VERSION "BASE;119 -- 04.07.2025 -- R3233 -- FDMgenDBC1.0"

NS_ :

BS_:

BU_: CM4

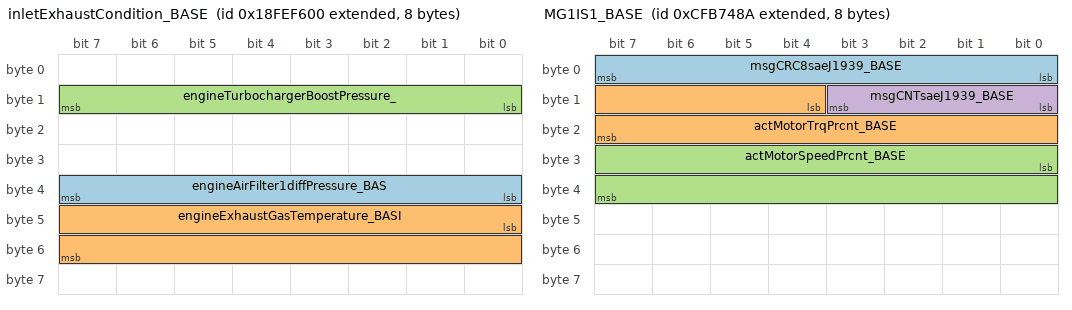
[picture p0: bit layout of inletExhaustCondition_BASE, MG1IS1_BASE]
BO_ 2566845952 inletExhaustCondition_BASE: 8 Vector__XXX
 SG_ engineAirFilter1diffPressure_BAS : 32|8@1+ (0.05,0) [0|12.5] "kPa" CM4
 SG_ engineExhaustGasTemperature_BASI : 40|16@1+ (0.03125,-273) [-273|1734.96875] "°C" CM4
 SG_ engineTurbochargerBoostPressure_ : 8|8@1+ (2,0) [0|500] "kPa" CM4

BO_ 2365289610 MG1IS1_BASE: 8 Vector__XXX
 SG_ msgCRC8saeJ1939_BASE : 0|8@1+ (1,0) [0|255] "-" CM4
 SG_ actMotorTrqPrcnt_BASE : 12|12@1+ (0.0625,-125) [-125|125.9375] "%" CM4
 SG_ actMotorSpeedPrcnt_BASE : 24|16@1+ (0.00390625,-125) [-125|125.99609375] "%" CM4
 SG_ msgCNTsaeJ1939_BASE : 8|4@1+ (1,0) [0|15] "-" CM4

BO_ 2566898183 bodyBuilderInfo7_BASE: 8 Vector__XXX
 SG_ BB_PlaceHolder_BASE : 0|8@1+ (1,0) [0|255] "-" CM4

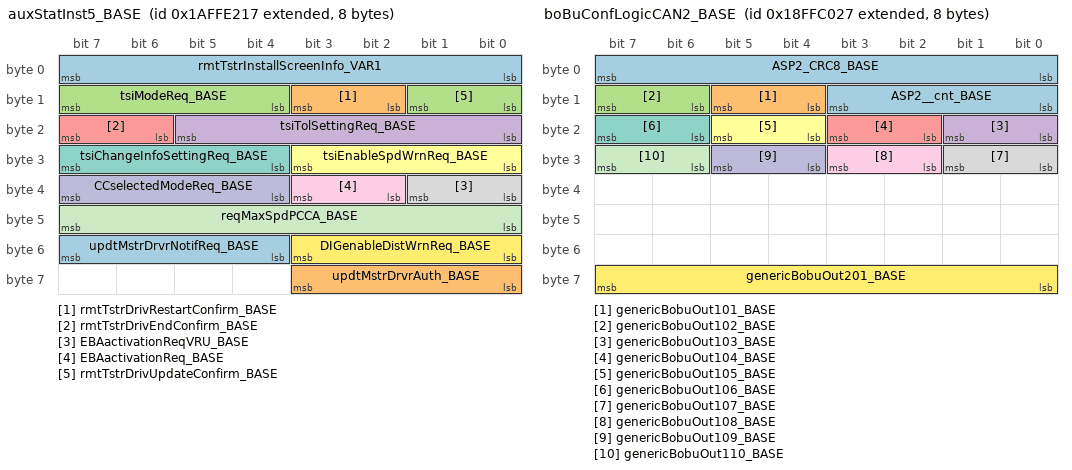
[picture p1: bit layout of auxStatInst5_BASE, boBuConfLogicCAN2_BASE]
BO_ 2600460823 auxStatInst5_BASE: 8 Vector__XXX
 SG_ rmtTstrInstallScreenInfo_VAR1 : 0|8@1+ (1,0) [0|0] "-" CM4
 SG_ rmtTstrDrivRestartConfirm_BASE : 10|2@1+ (1,0) [0|0] "-" CM4
 SG_ tsiModeReq_BASE : 12|4@1+ (1,0) [0|0] "-" CM4
 SG_ tsiTolSettingReq_BASE : 16|6@1+ (1,0) [0|0] "-" CM4
 SG_ rmtTstrDrivEndConfirm_BASE : 22|2@1+ (1,0) [0|0] "-" CM4
 SG_ tsiEnableSpdWrnReq_BASE : 24|4@1+ (1,0) [0|0] "-" CM4
 SG_ tsiChangeInfoSettingReq_BASE : 28|4@1+ (1,0) [0|0] "-" CM4
 SG_ EBAactivationReqVRU_BASE : 32|2@1+ (1,0) [0|0] "-" CM4
 SG_ EBAactivationReq_BASE : 34|2@1+ (1,0) [0|0] "-" CM4
 SG_ CCselectedModeReq_BASE : 36|4@1+ (1,0) [0|0] "-" CM4
 SG_ reqMaxSpdPCCA_BASE : 40|8@1+ (0.2,80) [80|130] "km/h" CM4
 SG_ DIGenableDistWrnReq_BASE : 48|4@1+ (1,0) [0|0] "-" CM4
 SG_ updtMstrDrvrNotifReq_BASE : 52|4@1+ (1,0) [0|0] "-" CM4
 SG_ updtMstrDrvrAuth_BASE : 56|4@1+ (1,0) [0|0] "-" CM4
 SG_ rmtTstrDrivUpdateConfirm_BASE : 8|2@1+ (1,0) [0|0] "-" CM4

BO_ 2566891559 auxStatMC7_BASE: 8 Vector__XXX
 SG_ bckgrndLghtAutoRevRqSave_BASE : 0|2@1+ (1,0) [0|0] "-" CM4
 SG_ ISCcondClutchOpen_BASE : 16|2@1+ (1,0) [0|0] "-" CM4
 SG_ ISCcondEngWarming_BASE : 18|2@1+ (1,0) [0|0] "-" CM4
 SG_ ISCcondBrakeNotPressed_BASE : 2|2@1+ (1,0) [0|0] "-" CM4
 SG_ ISCcondGearEngaged_BASE : 20|2@1+ (1,0) [0|0] "-" CM4
 SG_ ISCcondNeutralEngaged_BASE : 22|2@1+ (1,0) [0|0] "-" CM4
 SG_ ISCcondParkingBrakeActv_BASE : 24|2@1+ (1,0) [0|0] "-" CM4
 SG_ ISCcondParkingBrakeNotActv_BASE : 26|2@1+ (1,0) [0|0] "-" CM4
 SG_ ISCcondVehSpd_BASE : 28|2@1+ (1,0) [0|0] "-" CM4
 SG_ ZDRact_BASE : 30|2@1+ (1,0) [0|0] "-" CM4
 SG_ brightFunctionLight_BASE : 32|8@1+ (0.4,0) [0|100] "%" CM4
 SG_ ISCcondBrakePressed_BASE : 4|2@1+ (1,0) [0|0] "-" CM4
 SG_ dispInteriorLightAutoReq_BASE : 40|2@1+ (1,0) [0|0] "-" CM4
 SG_ dispIntLghtAutoCLreq_BASE : 42|2@1+ (1,0) [0|0] "-" CM4
 SG_ centrLubGreaseLvlLow_BASE : 44|2@1+ (1,0) [0|0] "-" CM4
 SG_ vehStandStill_BASE : 46|2@1+ (1,0) [0|0] "-" CM4
 SG_ centralUnlockDoorSelect_BASE : 48|2@1+ (1,0) [0|0] "-" CM4
 SG_ dispEntranceLightAutoReq_BASE : 50|2@1+ (1,0) [0|0] "-" CM4
 SG_ ureaLvlWarningDisp_BASE : 52|2@1+ (1,0) [0|0] "-" CM4
 SG_ centralLockSpeedSelect_BASE : 54|2@1+ (1,0) [0|0] "-" CM4
 SG_ auxStatMC7cntE2E_BASE : 56|4@1+ (1,0) [0|15] "-" CM4
 SG_ ISCcondClutchClosed_BASE : 6|2@1+ (1,0) [0|0] "-" CM4
 SG_ auxStatMC7chkE2E_BASE : 60|4@1+ (1,0) [0|15] "-" CM4
 SG_ bckgrndLghtBrghtReqSave_BASE : 8|8@1+ (0.4,0) [0|100] "%" CM4

BO_ 2566897703 boBuConfLogicCAN2_BASE: 8 Vector__XXX
 SG_ ASP2_CRC8_BASE : 0|8@1+ (1,0) [0|255] "-" CM4
 SG_ genericBobuOut101_BASE : 12|2@1+ (1,0) [0|0] "-" CM4
 SG_ genericBobuOut102_BASE : 14|2@1+ (1,0) [0|0] "-" CM4
 SG_ genericBobuOut103_BASE : 16|2@1+ (1,0) [0|0] "-" CM4
 SG_ genericBobuOut104_BASE : 18|2@1+ (1,0) [0|0] "-" CM4
 SG_ genericBobuOut105_BASE : 20|2@1+ (1,0) [0|0] "-" CM4
 SG_ genericBobuOut106_BASE : 22|2@1+ (1,0) [0|0] "-" CM4
 SG_ genericBobuOut107_BASE : 24|2@1+ (1,0) [0|0] "-" CM4
 SG_ genericBobuOut108_BASE : 26|2@1+ (1,0) [0|0] "-" CM4
 SG_ genericBobuOut109_BASE : 28|2@1+ (1,0) [0|0] "-" CM4
 SG_ genericBobuOut110_BASE : 30|2@1+ (1,0) [0|0] "-" CM4
 SG_ genericBobuOut201_BASE : 56|8@1+ (1,0) [0|250] "-" CM4
 SG_ ASP2__cnt_BASE : 8|4@1+ (1,0) [0|15] "-" CM4

BO_ 2600407315 customerInterface26_BASE: 8 Vector__XXX
 SG_ placeholderCuIntf26_BASE : 0|8@1+ (1,0) [0|255] "-" CM4

BO_ 2600407314 customerInterface25_BASE: 8 Vector__XXX
 SG_ placeholderCuIntf25_BASE : 0|8@1+ (1,0) [0|255] "-" CM4

BO_ 2600407316 customerInterface27_BASE: 8 Vector__XXX
 SG_ placeholderCuIntf27_BASE : 0|8@1+ (1,0) [0|255] "-" CM4

BO_ 2600407310 customerInterface21_BASE: 8 Vector__XXX
 SG_ placeholderCuIntf21_BASE : 0|8@1+ (1,0) [0|255] "-" CM4

BO_ 2600407311 customerInterface22_BASE: 8 Vector__XXX
 SG_ placeholderCuIntf22_BASE : 0|8@1+ (1,0) [0|255] "-" CM4

BO_ 2600407312 customerInterface23_BASE: 8 Vector__XXX
 SG_ placeholderCuIntf23_BASE : 0|8@1+ (1,0) [0|255] "-" CM4

BO_ 2600407313 customerInterface24_BASE: 8 Vector__XXX
 SG_ placeholderCuIntf24_BASE : 0|8@1+ (1,0) [0|255] "-" CM4

BO_ 2565879335 HVESSS2_BASE: 8 Vector__XXX
 SG_ HVESSDischrgPwLimDueSOC_BASE : 0|2@1+ (1,0) [0|0] "-" CM4

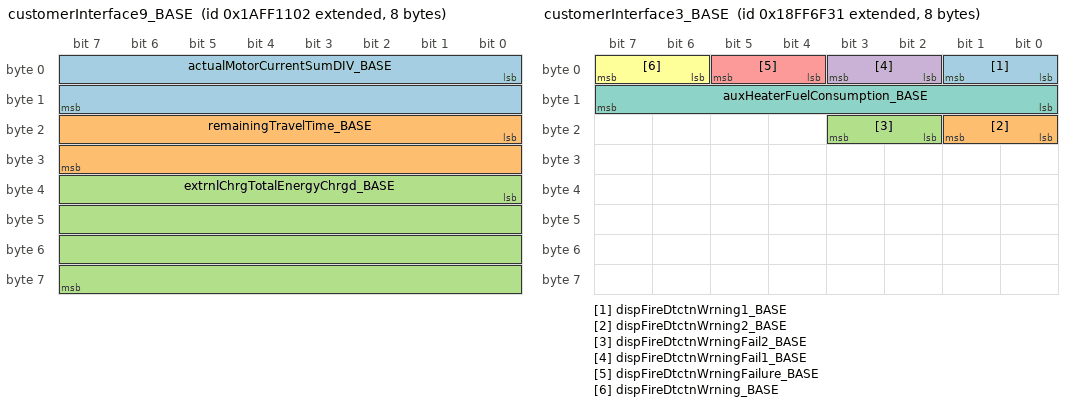
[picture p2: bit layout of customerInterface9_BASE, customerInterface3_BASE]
BO_ 2600407298 customerInterface9_BASE: 8 Vector__XXX
 SG_ actualMotorCurrentSumDIV_BASE : 0|16@1+ (1,-32000) [-32000|32255] "A" CM4
 SG_ remainingTravelTime_BASE : 16|16@1+ (0.05,0) [0|3212.75] "h" CM4
 SG_ extrnlChrgTotalEnergyChrgd_BASE : 32|32@1+ (1,0) [0|4211081215] "kWh" CM4

BO_ 2561553175 tirePressureReferenceSetting_BAS: 8 Vector__XXX
 SG_ axleLocation_TPRS : 0|8@1+ (1,0) [0|0] "-" CM4
 SG_ referenceTirePressureSetting_BAS : 8|8@1+ (8,0) [0|2000] "kPa" CM4

BO_ 2566764851 tirePressureReferenceInformation: 8 Vector__XXX
 SG_ axleLocation_TPRI : 0|8@1+ (1,0) [0|0] "-" CM4
 SG_ referenceTirePressure_BASIS : 8|8@1+ (8,0) [0|2000] "kPa" CM4

BO_ 2566876977 customerInterface3_BASE: 8 Vector__XXX
 SG_ dispFireDtctnWrning1_BASE : 0|2@1+ (1,0) [0|0] "-" CM4
 SG_ dispFireDtctnWrning2_BASE : 16|2@1+ (1,0) [0|0] "-" CM4
 SG_ dispFireDtctnWrningFail2_BASE : 18|2@1+ (1,0) [0|0] "-" CM4
 SG_ dispFireDtctnWrningFail1_BASE : 2|2@1+ (1,0) [0|0] "-" CM4
 SG_ dispFireDtctnWrningFailure_BASE : 4|2@1+ (1,0) [0|0] "-" CM4
 SG_ dispFireDtctnWrning_BASE : 6|2@1+ (1,0) [0|0] "-" CM4
 SG_ auxHeaterFuelConsumption_BASE : 8|8@1+ (0.1,0) [0|25] "l/h" CM4

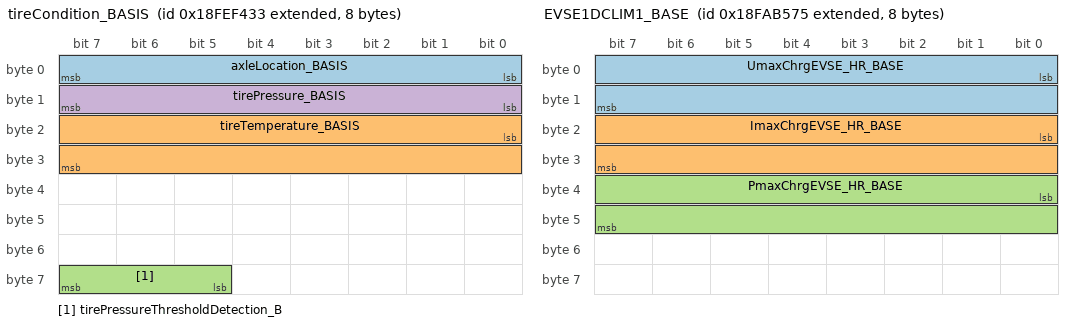
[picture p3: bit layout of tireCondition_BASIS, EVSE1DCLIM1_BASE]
BO_ 2566845491 tireCondition_BASIS: 8 Vector__XXX
 SG_ axleLocation_BASIS : 0|8@1+ (1,0) [0|255] "-" CM4
 SG_ tireTemperature_BASIS : 16|16@1+ (0.03125,-273) [-273|1735] "°C" CM4
 SG_ tirePressureThresholdDetection_B : 61|3@1+ (1,0) [0|0] "-" CM4
 SG_ tirePressure_BASIS : 8|8@1+ (8,0) [0|2000] "kPa" CM4

BO_ 2566567285 EVSE1DCLIM1_BASE: 8 Vector__XXX
 SG_ UmaxChrgEVSE_HR_BASE : 0|16@1+ (0.05,0) [0|3212.75] "V" CM4
 SG_ ImaxChrgEVSE_HR_BASE : 16|16@1+ (0.0625,0) [0|4015.9375] "A" CM4
 SG_ PmaxChrgEVSE_HR_BASE : 32|16@1+ (0.05,0) [0|3212.75] "kW" CM4

BO_ 2600407302 customerInterface13_BASE: 8 Vector__XXX
 SG_ customerInterface13placeholder_B : 0|8@1+ (1,0) [0|255] "-" CM4

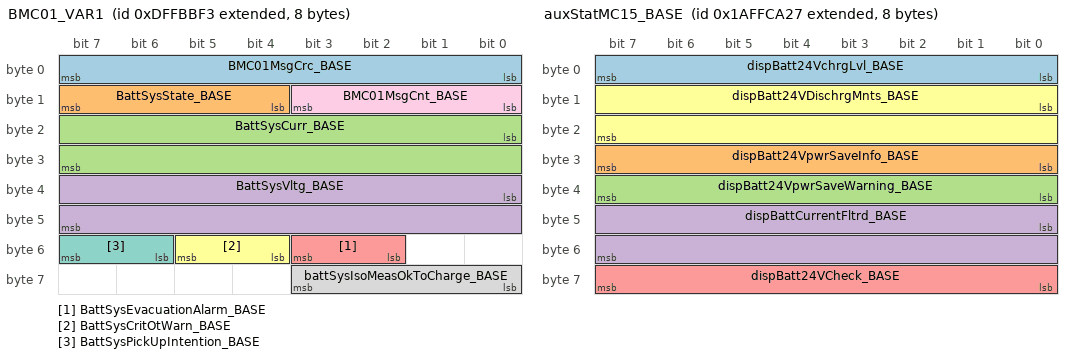
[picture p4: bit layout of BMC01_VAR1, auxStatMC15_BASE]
BO_ 2382347251 BMC01_VAR1: 8 Vector__XXX
 SG_ BMC01MsgCrc_BASE : 0|8@1+ (1,0) [0|255] "-" CM4
 SG_ BattSysState_BASE : 12|4@1+ (1,0) [0|0] "-" CM4
 SG_ BattSysCurr_BASE : 16|16@1+ (0.1,-3200) [-3200|3225.5] "A" CM4
 SG_ BattSysVltg_BASE : 32|16@1+ (0.1,0) [0|6425.5] "V" CM4
 SG_ BattSysEvacuationAlarm_BASE : 50|2@1+ (1,0) [0|0] "-" CM4
 SG_ BattSysCritOtWarn_BASE : 52|2@1+ (1,0) [0|0] "-" CM4
 SG_ BattSysPickUpIntention_BASE : 54|2@1+ (1,0) [0|0] "-" CM4
 SG_ battSysIsoMeasOkToCharge_BASE : 56|4@1+ (1,0) [0|0] "-" CM4
 SG_ BMC01MsgCnt_BASE : 8|4@1+ (1,0) [0|15] "-" CM4

BO_ 2600406039 parkHeaterInfo_VAR1: 8 Vector__XXX
 SG_ uiLCWactivationReq_BASE : 22|2@1+ (1,0) [0|0] "-" CM4
 SG_ uiTCWactivationReq_BASE : 24|2@1+ (1,0) [0|0] "-" CM4

BO_ 2600454695 auxStatMC15_BASE: 8 Vector__XXX
 SG_ dispBatt24VchrgLvl_BASE : 0|8@1+ (0.5,0) [0|125] "%" CM4
 SG_ dispBatt24VpwrSaveInfo_BASE : 24|8@1+ (1,0) [0|0] "-" CM4
 SG_ dispBatt24VpwrSaveWarning_BASE : 32|8@1+ (1,0) [0|0] "-" CM4
 SG_ dispBattCurrentFltrd_BASE : 40|16@1+ (0.1,-3212.8) [-3212.8|3212.7] "A" CM4
 SG_ dispBatt24VCheck_BASE : 56|8@1+ (1,0) [0|0] "-" CM4
 SG_ dispBatt24VDischrgMnts_BASE : 8|16@1+ (1,0) [0|64255] "min" CM4

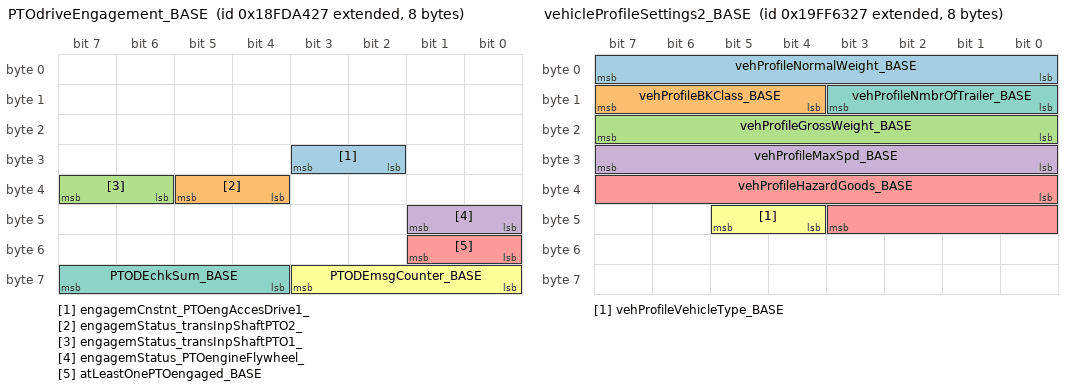
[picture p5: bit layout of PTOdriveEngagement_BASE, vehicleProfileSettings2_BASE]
BO_ 2566759463 PTOdriveEngagement_BASE: 8 Vector__XXX
 SG_ engagemCnstnt_PTOengAccesDrive1_ : 26|2@1+ (1,0) [0|0] "-" CM4
 SG_ engagemStatus_transInpShaftPTO2_ : 36|2@1+ (1,0) [0|0] "-" CM4
 SG_ engagemStatus_transInpShaftPTO1_ : 38|2@1+ (1,0) [0|0] "-" CM4
 SG_ engagemStatus_PTOengineFlywheel_ : 40|2@1+ (1,0) [0|0] "-" CM4
 SG_ atLeastOnePTOengaged_BASE : 48|2@1+ (1,0) [0|0] "-" CM4
 SG_ PTODEmsgCounter_BASE : 56|4@1+ (1,0) [0|7] "count" CM4
 SG_ PTODEchkSum_BASE : 60|4@1+ (1,0) [0|7] "count" CM4

BO_ 2583651111 vehicleProfileSettings2_BASE: 8 Vector__XXX
 SG_ vehProfileNormalWeight_BASE : 0|8@1+ (500,0) [0|99000] "kg" CM4
 SG_ vehProfileBKClass_BASE : 12|4@1+ (1,0) [0|0] "-" CM4
 SG_ vehProfileGrossWeight_BASE : 16|8@1+ (500,0) [0|99000] "kg" CM4
 SG_ vehProfileMaxSpd_BASE : 24|8@1+ (1,0) [0|120] "km/h" CM4
 SG_ vehProfileHazardGoods_BASE : 32|12@1+ (1,0) [0|4095] "-" CM4
 SG_ vehProfileVehicleType_BASE : 44|2@1+ (1,0) [0|0] "-" CM4
 SG_ vehProfileNmbrOfTrailer_BASE : 8|4@1+ (1,0) [0|0] "-" CM4

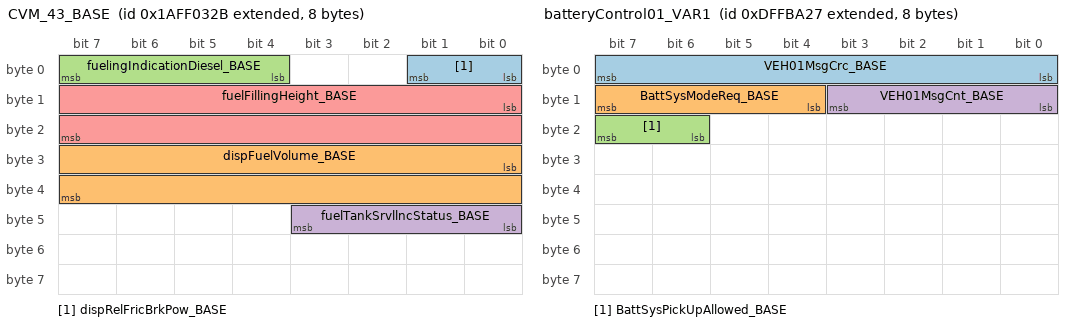
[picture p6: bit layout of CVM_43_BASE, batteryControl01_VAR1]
BO_ 2600403755 CVM_43_BASE: 8 Vector__XXX
 SG_ dispRelFricBrkPow_BASE : 0|2@1+ (1,0) [0|0] "-" CM4
 SG_ dispFuelVolume_BASE : 24|16@1+ (0.5,0) [0|32127.5] "l" CM4
 SG_ fuelingIndicationDiesel_BASE : 4|4@1+ (1,0) [0|0] "-" CM4
 SG_ fuelTankSrvllncStatus_BASE : 40|4@1+ (1,0) [0|0] "-" CM4
 SG_ fuelFillingHeight_BASE : 8|16@1+ (1,0) [0|64255] "mm" CM4

BO_ 2382346791 batteryControl01_VAR1: 8 Vector__XXX
 SG_ VEH01MsgCrc_BASE : 0|8@1+ (1,0) [0|255] "-" CM4
 SG_ BattSysModeReq_BASE : 12|4@1+ (1,0) [0|0] "-" CM4
 SG_ BattSysPickUpAllowed_BASE : 22|2@1+ (1,0) [0|0] "-" CM4
 SG_ VEH01MsgCnt_BASE : 8|4@1+ (1,0) [0|15] "-" CM4

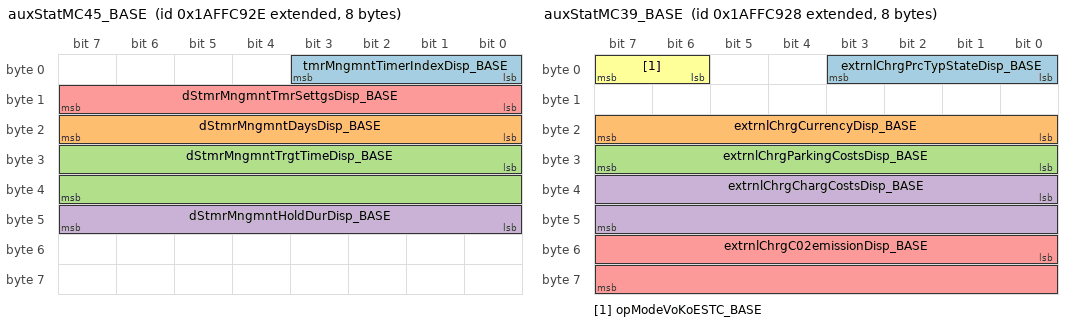
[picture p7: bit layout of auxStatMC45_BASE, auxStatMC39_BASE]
BO_ 2600454446 auxStatMC45_BASE: 8 Vector__XXX
 SG_ tmrMngmntTimerIndexDisp_BASE : 0|4@1+ (1,0) [0|0] "-" CM4
 SG_ dStmrMngmntDaysDisp_BASE : 16|8@1+ (1,0) [0|127] "-" CM4
 SG_ dStmrMngmntTrgtTimeDisp_BASE : 24|16@1+ (1,0) [0|64255] "min" CM4
 SG_ dStmrMngmntHoldDurDisp_BASE : 40|8@1+ (15,0) [0|3750] "min" CM4
 SG_ dStmrMngmntTmrSettgsDisp_BASE : 8|8@1+ (1,0) [0|127] "-" CM4

BO_ 2600454440 auxStatMC39_BASE: 8 Vector__XXX
 SG_ extrnlChrgPrcTypStateDisp_BASE : 0|4@1+ (1,0) [0|0] "-" CM4
 SG_ extrnlChrgCurrencyDisp_BASE : 16|8@1+ (1,0) [0|0] "-" CM4
 SG_ extrnlChrgParkingCostsDisp_BASE : 24|8@1+ (1,0) [0|250] "-" CM4
 SG_ extrnlChrgChargCostsDisp_BASE : 32|16@1+ (1,0) [0|64255] "-" CM4
 SG_ extrnlChrgC02emissionDisp_BASE : 48|16@1+ (0.1,0) [0|6425.5] "kg" CM4
 SG_ opModeVoKoESTC_BASE : 6|2@1+ (1,0) [0|0] "-" CM4

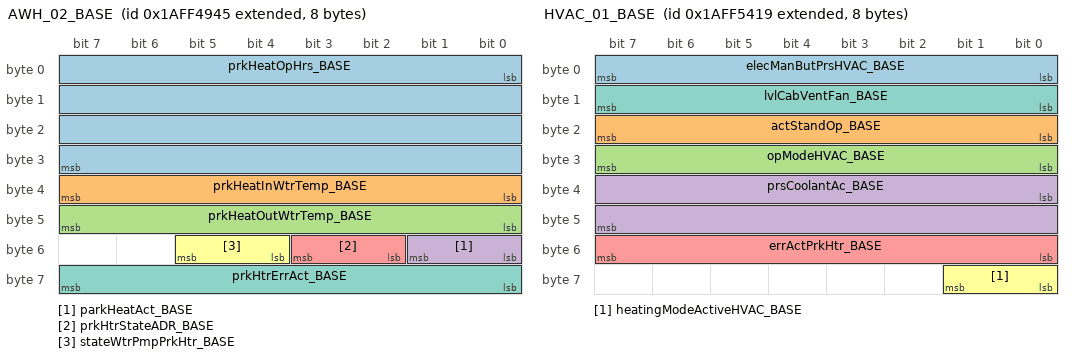
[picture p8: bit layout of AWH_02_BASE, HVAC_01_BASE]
BO_ 2600421701 AWH_02_BASE: 8 Vector__XXX
 SG_ prkHeatOpHrs_BASE : 0|32@1+ (0.0166667,0) [0|50000] "h" CM4
 SG_ prkHeatInWtrTemp_BASE : 32|8@1+ (1,-40) [-40|210] "°C" CM4
 SG_ prkHeatOutWtrTemp_BASE : 40|8@1+ (1,-40) [-40|210] "°C" CM4
 SG_ parkHeatAct_BASE : 48|2@1+ (1,0) [0|0] "-" CM4
 SG_ prkHtrStateADR_BASE : 50|2@1+ (1,0) [0|0] "-" CM4
 SG_ stateWtrPmpPrkHtr_BASE : 52|2@1+ (1,0) [0|0] "-" CM4
 SG_ prkHtrErrAct_BASE : 56|8@1+ (1,0) [0|0] "-" CM4

BO_ 2600425497 HVAC_05_BASE: 8 Vector__XXX
 SG_ nmbStrtCmprssr_BASE : 0|32@1+ (1,0) [0|4211081215] "-" CM4
 SG_ totOprtnHoursCmprssr_BASE : 32|32@1+ (0.05,0) [0|210554060.75] "h" CM4

BO_ 2600424473 HVAC_01_BASE: 8 Vector__XXX
 SG_ elecManButPrsHVAC_BASE : 0|8@1+ (1,0) [0|0] "-" CM4
 SG_ actStandOp_BASE : 16|8@1+ (1,0) [0|0] "-" CM4
 SG_ opModeHVAC_BASE : 24|8@1+ (1,0) [0|0] "-" CM4
 SG_ prsCoolantAc_BASE : 32|16@1+ (0.5,0) [0|32127.5] "kPa" CM4
 SG_ errActPrkHtr_BASE : 48|8@1+ (1,0) [0|0] "-" CM4
 SG_ heatingModeActiveHVAC_BASE : 56|2@1+ (1,0) [0|0] "-" CM4
 SG_ lvlCabVentFan_BASE : 8|8@1+ (1,0) [0|250] "-" CM4

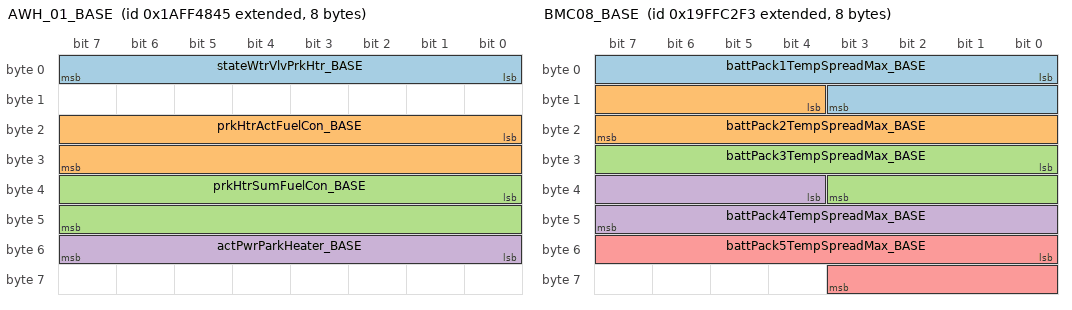
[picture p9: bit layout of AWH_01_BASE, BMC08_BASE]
BO_ 2600421445 AWH_01_BASE: 8 Vector__XXX
 SG_ stateWtrVlvPrkHtr_BASE : 0|8@1+ (1,0) [0|0] "-" CM4
 SG_ prkHtrActFuelCon_BASE : 16|16@1+ (0.01,0) [0|50] "l/h" CM4
 SG_ prkHtrSumFuelCon_BASE : 32|16@1+ (1,0) [0|50000] "l" CM4
 SG_ actPwrParkHeater_BASE : 48|8@1+ (0.04,0) [0|10] "kW" CM4

BO_ 2600425241 HVAC_04_BASE: 8 Vector__XXX
 SG_ nmbStrtElCmprssr_BASE : 0|32@1+ (1,0) [0|4211081215] "-" CM4
 SG_ totOprtnHoursElCmprssr_BASE : 32|32@1+ (0.05,0) [0|210554060.75] "h" CM4

BO_ 2583675635 BMC08_BASE: 8 Vector__XXX
 SG_ battPack1TempSpreadMax_BASE : 0|12@1+ (0.1,0) [0|401.5] "°C" CM4
 SG_ battPack2TempSpreadMax_BASE : 12|12@1+ (0.1,0) [0|401.5] "°C" CM4
 SG_ battPack3TempSpreadMax_BASE : 24|12@1+ (0.1,0) [0|401.5] "°C" CM4
 SG_ battPack4TempSpreadMax_BASE : 36|12@1+ (0.1,0) [0|401.5] "°C" CM4
 SG_ battPack5TempSpreadMax_BASE : 48|12@1+ (0.1,0) [0|401.5] "°C" CM4

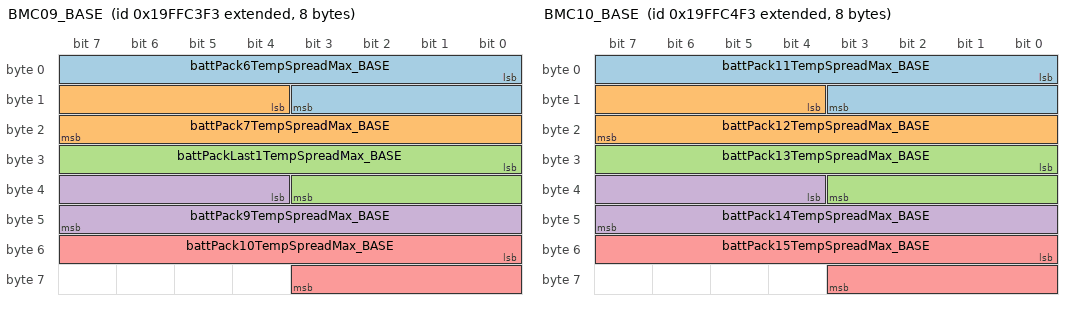
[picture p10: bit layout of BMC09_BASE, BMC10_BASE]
BO_ 2583675891 BMC09_BASE: 8 Vector__XXX
 SG_ battPack6TempSpreadMax_BASE : 0|12@1+ (0.1,0) [0|401.5] "°C" CM4
 SG_ battPack7TempSpreadMax_BASE : 12|12@1+ (0.1,0) [0|401.5] "°C" CM4
 SG_ battPackLast1TempSpreadMax_BASE : 24|12@1+ (0.1,0) [0|401.5] "°C" CM4
 SG_ battPack9TempSpreadMax_BASE : 36|12@1+ (0.1,0) [0|401.5] "°C" CM4
 SG_ battPack10TempSpreadMax_BASE : 48|12@1+ (0.1,0) [0|401.5] "°C" CM4

BO_ 2583676147 BMC10_BASE: 8 Vector__XXX
 SG_ battPack11TempSpreadMax_BASE : 0|12@1+ (0.1,0) [0|401.5] "°C" CM4
 SG_ battPack12TempSpreadMax_BASE : 12|12@1+ (0.1,0) [0|401.5] "°C" CM4
 SG_ battPack13TempSpreadMax_BASE : 24|12@1+ (0.1,0) [0|401.5] "°C" CM4
 SG_ battPack14TempSpreadMax_BASE : 36|12@1+ (0.1,0) [0|401.5] "°C" CM4
 SG_ battPack15TempSpreadMax_BASE : 48|12@1+ (0.1,0) [0|401.5] "°C" CM4

BO_ 2600403762 CVM_50_BASE: 8 Vector__XXX
 SG_ CVM50placeholder_BASE : 0|8@1+ (1,0) [0|255] "-" CM4

BO_ 2600403763 CVM_51_BASE: 8 Vector__XXX
 SG_ CVM51placeholder_BASE : 8|8@1+ (1,0) [0|255] "-" CM4

BO_ 2583677942 batteryAnalyticsPack02_BASE: 8 Vector__XXX
 SG_ battAnalyticsPack02muxID_BASE M : 0|4@1+ (1,0) [0|0] "-" CM4
 SG_ HVESP2highestCellTemp_BASE m5 : 16|16@1+ (0.03125,-273) [-273|1734.96875] "°C" CM4
 SG_ HVESP2lowestCellTemp_BASE m6 : 16|16@1+ (0.03125,-273) [-273|1734.96875] "°C" CM4
 SG_ battPack02dschrgEthrtcMax_BASE m4 : 16|16@1+ (0.05,0) [0|1000] "kWh" CM4
 SG_ HVESP2dischargeCapacity_BASE m3 : 16|16@1+ (0.01,0) [0|642.55] "Ah" CM4
 SG_ HVESP2fastUpdateSOC_BASE m0 : 16|16@1+ (0.0015625,0) [0|100.3984375] "%" CM4
 SG_ HVESP2voltageLevel_BASE m0 : 32|16@1+ (0.05,0) [0|3212.75] "V" CM4
 SG_ battPack02minCellVoltage_BASE m1 : 32|16@1+ (0.0001,0) [0|6.4255] "V" CM4
 SG_ battPack02isoMeasResNegv_BASE m3 : 4|12@1+ (2500,0) [0|10037500] "Ohm" CM4
 SG_ battPack02isoMeasResPosv_BASE m2 : 4|12@1+ (2500,0) [0|10037500] "Ohm" CM4
 SG_ battPack02glblDscnnctReq_BASE m0 : 4|4@1+ (1,0) [0|15] "-" CM4
 SG_ battPack02maxCellVoltage_BASE m1 : 48|16@1+ (0.0001,0) [0|6.4255] "V" CM4
 SG_ HVESP2current_BASE m0 : 48|16@1+ (0.05,-1600) [-1600|1612.75] "A" CM4
 SG_ battPack02SOH_BASE m1 : 6|10@1+ (0.1,0) [0|100] "%" CM4
 SG_ battPack02modeReq_BASE m0 : 8|4@1+ (1,0) [0|0] "-" CM4

BO_ 2583677881 batteryAnalyticsPack03_BASE: 8 Vector__XXX
 SG_ battAnalyticsPack03muxID_BASE M : 0|4@1+ (1,0) [0|0] "-" CM4
 SG_ HVESP3highestCellTemp_BASE m5 : 16|16@1+ (0.03125,-273) [-273|1734.96875] "°C" CM4
 SG_ HVESP3lowestCellTemp_BASE m6 : 16|16@1+ (0.03125,-273) [-273|1734.96875] "°C" CM4
 SG_ battPack03dschrgEthrtcMax_BASE m4 : 16|16@1+ (0.05,0) [0|1000] "kWh" CM4
 SG_ HVESP3dischargeCapacity_BASE m3 : 16|16@1+ (0.01,0) [0|642.55] "Ah" CM4
 SG_ HVESP3fastUpdateSOC_BASE m0 : 16|16@1+ (0.0015625,0) [0|100.3984375] "%" CM4
 SG_ battPack03minCellVoltage_BASE m1 : 32|16@1+ (0.0001,0) [0|6.4255] "V" CM4
 SG_ HVESP3voltageLevel_BASE m0 : 32|16@1+ (0.05,0) [0|3212.75] "V" CM4
 SG_ battPack03isoMeasResPosv_BASE m2 : 4|12@1+ (2500,0) [0|10037500] "Ohm" CM4
 SG_ battPack03isoMeasResNegv_BASE m3 : 4|12@1+ (2500,0) [0|10037500] "Ohm" CM4
 SG_ battPack03glblDscnnctReq_BASE m0 : 4|4@1+ (1,0) [0|15] "-" CM4
 SG_ HVESP3current_BASE m0 : 48|16@1+ (0.05,-1600) [-1600|1612.75] "A" CM4
 SG_ battPack03maxCellVoltage_BASE m1 : 48|16@1+ (0.0001,0) [0|6.4255] "V" CM4
 SG_ battPack03SOH_BASE m1 : 6|10@1+ (0.1,0) [0|100] "%" CM4
 SG_ battPack03modeReq_BASE m0 : 8|4@1+ (1,0) [0|0] "-" CM4

BO_ 2583677882 batteryAnalyticsPack04_BASE: 8 Vector__XXX
 SG_ battAnalyticsPack04muxID_BASE M : 0|4@1+ (1,0) [0|0] "-" CM4
 SG_ battPack04dschrgEthrtcMax_BASE m4 : 16|16@1+ (0.05,0) [0|1000] "kWh" CM4
 SG_ HVESP4lowestCellTemp_BASE m6 : 16|16@1+ (0.03125,-273) [-273|1734.96875] "°C" CM4
 SG_ HVESP4highestCellTemp_BASE m5 : 16|16@1+ (0.03125,-273) [-273|1734.96875] "°C" CM4
 SG_ HVESP4dischargeCapacity_BASE m3 : 16|16@1+ (0.01,0) [0|642.55] "Ah" CM4
 SG_ HVESP4fastUpdateSOC_BASE m0 : 16|16@1+ (0.0015625,0) [0|100.3984375] "%" CM4
 SG_ HVESP4voltageLevel_BASE m0 : 32|16@1+ (0.05,0) [0|3212.75] "V" CM4
 SG_ battPack04minCellVoltage_BASE m1 : 32|16@1+ (0.0001,0) [0|6.4255] "V" CM4
 SG_ battPack04isoMeasResPosv_BASE m2 : 4|12@1+ (2500,0) [0|10037500] "Ohm" CM4
 SG_ battPack04glblDscnnctReq_BASE m0 : 4|4@1+ (1,0) [0|15] "-" CM4
 SG_ battPack04isoMeasResNegv_BASE m3 : 4|12@1+ (2500,0) [0|10037500] "Ohm" CM4
 SG_ battPack04maxCellVoltage_BASE m1 : 48|16@1+ (0.0001,0) [0|6.4255] "V" CM4
 SG_ HVESP4current_BASE m0 : 48|16@1+ (0.05,-1600) [-1600|1612.75] "A" CM4
 SG_ battPack04SOH_BASE m1 : 6|10@1+ (0.1,0) [0|100] "%" CM4
 SG_ battPack04modeReq_BASE m0 : 8|4@1+ (1,0) [0|0] "-" CM4

BO_ 2583677883 batteryAnalyticsPack05_BASE: 8 Vector__XXX
 SG_ battAnalyticsPack05muxID_BASE M : 0|4@1+ (1,0) [0|0] "-" CM4
 SG_ battPack05dschrgEthrtcMax_BASE m4 : 16|16@1+ (0.05,0) [0|1000] "kWh" CM4
 SG_ HVESP5lowestCellTemp_BASE m6 : 16|16@1+ (0.03125,-273) [-273|1734.96875] "°C" CM4
 SG_ HVESP5highestCellTemp_BASE m5 : 16|16@1+ (0.03125,-273) [-273|1734.96875] "°C" CM4
 SG_ HVESP5fastUpdateSOC_BASE m0 : 16|16@1+ (0.0015625,0) [0|100.3984375] "%" CM4
 SG_ HVESP5dischargeCapacity_BASE m3 : 16|16@1+ (0.01,0) [0|642.55] "Ah" CM4
 SG_ battPack05minCellVoltage_BASE m1 : 32|16@1+ (0.0001,0) [0|6.4255] "V" CM4
 SG_ HVESP5voltageLevel_BASE m0 : 32|16@1+ (0.05,0) [0|3212.75] "V" CM4
 SG_ battPack05glblDscnnctReq_BASE m0 : 4|4@1+ (1,0) [0|15] "-" CM4
 SG_ battPack05isoMeasResNegv_BASE m3 : 4|12@1+ (2500,0) [0|10037500] "Ohm" CM4
 SG_ battPack05isoMeasResPosv_BASE m2 : 4|12@1+ (2500,0) [0|10037500] "Ohm" CM4
 SG_ HVESP5current_BASE m0 : 48|16@1+ (0.05,-1600) [-1600|1612.75] "A" CM4
 SG_ battPack05maxCellVoltage_BASE m1 : 48|16@1+ (0.0001,0) [0|6.4255] "V" CM4
 SG_ battPack05SOH_BASE m1 : 6|10@1+ (0.1,0) [0|100] "%" CM4
 SG_ battPack05modeReq_BASE m0 : 8|4@1+ (1,0) [0|0] "-" CM4

BO_ 2583677884 batteryAnalyticsPack06_BASE: 8 Vector__XXX
 SG_ battAnalyticsPack06muxID_BASE M : 0|4@1+ (1,0) [0|0] "-" CM4
 SG_ battPack06dschrgEthrtcMax_BASE m4 : 16|16@1+ (0.05,0) [0|1000] "kWh" CM4
 SG_ HVESP6highestCellTemp_BASE m5 : 16|16@1+ (0.03125,-273) [-273|1734.96875] "°C" CM4
 SG_ HVESP6lowestCellTemp_BASE m6 : 16|16@1+ (0.03125,-273) [-273|1734.96875] "°C" CM4
 SG_ HVESP6dischargeCapacity_BASE m3 : 16|16@1+ (0.01,0) [0|642.55] "Ah" CM4
 SG_ HVESP6fastUpdateSOC_BASE m0 : 16|16@1+ (0.0015625,0) [0|100.3984375] "%" CM4
 SG_ HVESP6voltageLevel_BASE m0 : 32|16@1+ (0.05,0) [0|3212.75] "V" CM4
 SG_ battPack06minCellVoltage_BASE m1 : 32|16@1+ (0.0001,0) [0|6.4255] "V" CM4
 SG_ battPack06isoMeasResPosv_BASE m2 : 4|12@1+ (2500,0) [0|10037500] "Ohm" CM4
 SG_ battPack06isoMeasResNegv_BASE m3 : 4|12@1+ (2500,0) [0|10037500] "Ohm" CM4
 SG_ battPack06glblDscnnctReq_BASE m0 : 4|4@1+ (1,0) [0|15] "-" CM4
 SG_ battPack06maxCellVoltage_BASE m1 : 48|16@1+ (0.0001,0) [0|6.4255] "V" CM4
 SG_ HVESP6current_BASE m0 : 48|16@1+ (0.05,-1600) [-1600|1612.75] "A" CM4
 SG_ battPack06SOH_BASE m1 : 6|10@1+ (0.1,0) [0|100] "%" CM4
 SG_ battPack06modeReq_BASE m0 : 8|4@1+ (1,0) [0|0] "-" CM4

BO_ 2583677886 batteryAnalyticsPack07_BASE: 8 Vector__XXX
 SG_ battAnalyticsPack07muxID_BASE M : 0|4@1+ (1,0) [0|0] "-" CM4
 SG_ HVESP7highestCellTemp_BASE m5 : 16|16@1+ (0.03125,-273) [-273|1734.96875] "°C" CM4
 SG_ battPack07dschrgEthrtcMax_BASE m4 : 16|16@1+ (0.05,0) [0|1000] "kWh" CM4
 SG_ HVESP7lowestCellTemp_BASE m6 : 16|16@1+ (0.03125,-273) [-273|1734.96875] "°C" CM4
 SG_ HVESP7dischargeCapacity_BASE m3 : 16|16@1+ (0.01,0) [0|642.55] "Ah" CM4
 SG_ HVESP7fastUpdateSOC_BASE m0 : 16|16@1+ (0.0015625,0) [0|100.3984375] "%" CM4
 SG_ battPack07minCellVoltage_BASE m1 : 32|16@1+ (0.0001,0) [0|6.4255] "V" CM4
 SG_ HVESP7voltageLevel_BASE m0 : 32|16@1+ (0.05,0) [0|3212.75] "V" CM4
 SG_ battPack07isoMeasResNegv_BASE m3 : 4|12@1+ (2500,0) [0|10037500] "Ohm" CM4
 SG_ battPack07isoMeasResPosv_BASE m2 : 4|12@1+ (2500,0) [0|10037500] "Ohm" CM4
 SG_ battPack07glblDscnnctReq_BASE m0 : 4|4@1+ (1,0) [0|15] "-" CM4
 SG_ HVESP7current_BASE m0 : 48|16@1+ (0.05,-1600) [-1600|1612.75] "A" CM4
 SG_ battPack07maxCellVoltage_BASE m1 : 48|16@1+ (0.0001,0) [0|6.4255] "V" CM4
 SG_ battPack07SOH_BASE m1 : 6|10@1+ (0.1,0) [0|100] "%" CM4
 SG_ battPack07modeReq_BASE m0 : 8|4@1+ (1,0) [0|0] "-" CM4

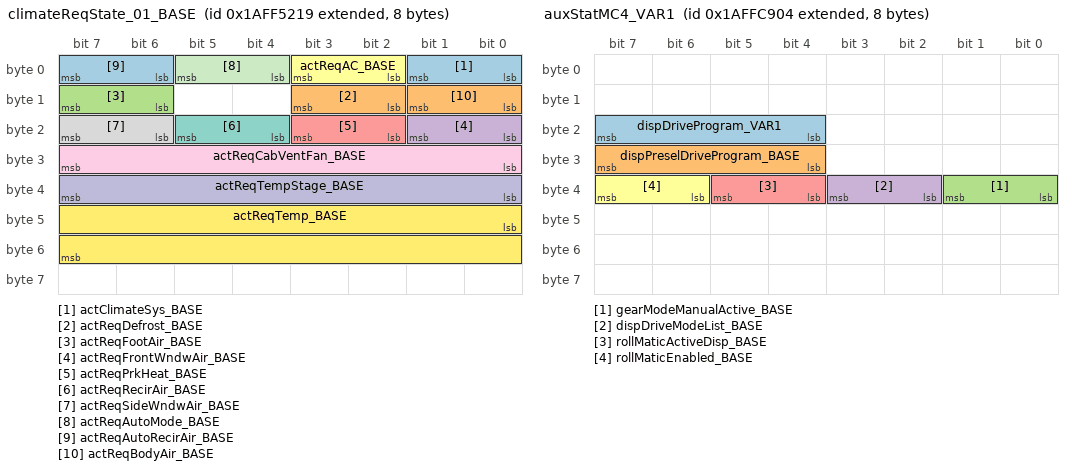
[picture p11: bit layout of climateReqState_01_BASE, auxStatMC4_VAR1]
BO_ 2600423961 climateReqState_01_BASE: 8 Vector__XXX
 SG_ actClimateSys_BASE : 0|2@1+ (1,0) [0|0] "-" CM4
 SG_ actReqDefrost_BASE : 10|2@1+ (1,0) [0|0] "-" CM4
 SG_ actReqFootAir_BASE : 14|2@1+ (1,0) [0|0] "-" CM4
 SG_ actReqFrontWndwAir_BASE : 16|2@1+ (1,0) [0|0] "-" CM4
 SG_ actReqPrkHeat_BASE : 18|2@1+ (1,0) [0|0] "-" CM4
 SG_ actReqAC_BASE : 2|2@1+ (1,0) [0|0] "-" CM4
 SG_ actReqRecirAir_BASE : 20|2@1+ (1,0) [0|0] "-" CM4
 SG_ actReqSideWndwAir_BASE : 22|2@1+ (1,0) [0|0] "-" CM4
 SG_ actReqCabVentFan_BASE : 24|8@1+ (1,0) [0|250] "-" CM4
 SG_ actReqTempStage_BASE : 32|8@1+ (1,0) [0|30] "-" CM4
 SG_ actReqAutoMode_BASE : 4|2@1+ (1,0) [0|0] "-" CM4
 SG_ actReqTemp_BASE : 40|16@1+ (0.03125,-273) [-273|1734.96875] "°C" CM4
 SG_ actReqAutoRecirAir_BASE : 6|2@1+ (1,0) [0|0] "-" CM4
 SG_ actReqBodyAir_BASE : 8|2@1+ (1,0) [0|0] "-" CM4

BO_ 2583677894 batteryAnalyticsPack08_BASE: 8 Vector__XXX
 SG_ battAnalyticsPack08muxID_BASE M : 0|4@1+ (1,0) [0|0] "-" CM4
 SG_ HVESP8lowestCellTemp_BASE m6 : 16|16@1+ (0.03125,-273) [-273|1734.96875] "°C" CM4
 SG_ HVESP8highestCellTemp_BASE m5 : 16|16@1+ (0.03125,-273) [-273|1734.96875] "°C" CM4
 SG_ battPack08dschrgEthrtcMax_BASE m4 : 16|16@1+ (0.05,0) [0|1000] "kWh" CM4
 SG_ HVESP8dischargeCapacity_BASE m3 : 16|16@1+ (0.01,0) [0|642.55] "Ah" CM4
 SG_ HVESP8fastUpdateSOC_BASE m0 : 16|16@1+ (0.0015625,0) [0|100.3984375] "%" CM4
 SG_ HVESP8voltageLevel_BASE m0 : 32|16@1+ (0.05,0) [0|3212.75] "V" CM4
 SG_ battPack08minCellVoltage_BASE m1 : 32|16@1+ (0.0001,0) [0|6.4255] "V" CM4
 SG_ battPack08isoMeasResNegv_BASE m3 : 4|12@1+ (2500,0) [0|10037500] "Ohm" CM4
 SG_ battPack08isoMeasResPosv_BASE m2 : 4|12@1+ (2500,0) [0|10037500] "Ohm" CM4
 SG_ battPack08glblDscnnctReq_BASE m0 : 4|4@1+ (1,0) [0|15] "-" CM4
 SG_ HVESP8current_BASE m0 : 48|16@1+ (0.05,-1600) [-1600|1612.75] "A" CM4
 SG_ battPack08maxCellVoltage_BASE m1 : 48|16@1+ (0.0001,0) [0|6.4255] "V" CM4
 SG_ battPack08SOH_BASE m1 : 6|10@1+ (0.1,0) [0|100] "%" CM4
 SG_ battPack08modeReq_BASE m0 : 8|4@1+ (1,0) [0|0] "-" CM4

BO_ 2583677895 batteryAnalyticsPack09_BASE: 8 Vector__XXX
 SG_ battAnalyticsPack09muxID_BASE M : 0|4@1+ (1,0) [0|0] "-" CM4
 SG_ HVESP9fastUpdateSOC_BASE m0 : 16|16@1+ (0.0015625,0) [0|100.3984375] "%" CM4
 SG_ battPack09dschrgEthrtcMax_BASE m4 : 16|16@1+ (0.05,0) [0|1000] "kWh" CM4
 SG_ HVESP9lowestCellTemp_BASE m6 : 16|16@1+ (0.03125,-273) [-273|1734.96875] "°C" CM4
 SG_ HVESP9dischargeCapacity_BASE m3 : 16|16@1+ (0.01,0) [0|642.55] "Ah" CM4
 SG_ HVESP9highestCellTemp_BASE m5 : 16|16@1+ (0.03125,-273) [-273|1734.96875] "°C" CM4
 SG_ battPack09minCellVoltage_BASE m1 : 32|16@1+ (0.0001,0) [0|6.4255] "V" CM4
 SG_ HVESP9voltageLevel_BASE m0 : 32|16@1+ (0.05,0) [0|3212.75] "V" CM4
 SG_ battPack09isoMeasResPosv_BASE m2 : 4|12@1+ (2500,0) [0|10037500] "Ohm" CM4
 SG_ battPack09glblDscnnctReq_BASE m0 : 4|4@1+ (1,0) [0|15] "-" CM4
 SG_ battPack09isoMeasResNegv_BASE m3 : 4|12@1+ (2500,0) [0|10037500] "Ohm" CM4
 SG_ HVESP9current_BASE m0 : 48|16@1+ (0.05,-1600) [-1600|1612.75] "A" CM4
 SG_ battPack09maxCellVoltage_BASE m1 : 48|16@1+ (0.0001,0) [0|6.4255] "V" CM4
 SG_ battPack09SOH_BASE m1 : 6|10@1+ (0.1,0) [0|100] "%" CM4
 SG_ battPack09modeReq_BASE m0 : 8|4@1+ (1,0) [0|0] "-" CM4

BO_ 2583677902 batteryAnalyticsPack11_BASE: 8 Vector__XXX
 SG_ battAnalyticsPack11muxID_BASE M : 0|4@1+ (1,0) [0|0] "-" CM4
 SG_ HVESP11highestCellTemp_BASE m5 : 16|16@1+ (0.03125,-273) [-273|1734.96875] "°C" CM4
 SG_ HVESP11fastUpdateSOC_BASE m0 : 16|16@1+ (0.0015625,0) [0|100.3984375] "%" CM4
 SG_ battPack11dschrgEthrtcMax_BASE m4 : 16|16@1+ (0.05,0) [0|1000] "kWh" CM4
 SG_ HVESP11dischargeCapacity_BASE m3 : 16|16@1+ (0.01,0) [0|642.55] "Ah" CM4
 SG_ HVESP11lowestCellTemp_BASE m6 : 16|16@1+ (0.03125,-273) [-273|1734.96875] "°C" CM4
 SG_ HVESP11voltageLevel_BASE m0 : 32|16@1+ (0.05,0) [0|3212.75] "V" CM4
 SG_ battPack11minCellVoltage_BASE m1 : 32|16@1+ (0.0001,0) [0|6.4255] "V" CM4
 SG_ battPack11glblDscnnctReq_BASE m0 : 4|4@1+ (1,0) [0|15] "-" CM4
 SG_ battPack11isoMeasResNegv_BASE m3 : 4|12@1+ (2500,0) [0|10037500] "Ohm" CM4
 SG_ battPack11isoMeasResPosv_BASE m2 : 4|12@1+ (2500,0) [0|10037500] "Ohm" CM4
 SG_ battPack11maxCellVoltage_BASE m1 : 48|16@1+ (0.0001,0) [0|6.4255] "V" CM4
 SG_ HVESP11current_BASE m0 : 48|16@1+ (0.05,-1600) [-1600|1612.75] "A" CM4
 SG_ battPack11SOH_BASE m1 : 6|10@1+ (0.1,0) [0|100] "%" CM4
 SG_ battPack11modeReq_BASE m0 : 8|4@1+ (1,0) [0|0] "-" CM4

BO_ 2583677903 batteryAnalyticsPack12_BASE: 8 Vector__XXX
 SG_ battAnalyticsPack12muxID_BASE M : 0|4@1+ (1,0) [0|0] "-" CM4
 SG_ battPack12dschrgEthrtcMax_BASE m4 : 16|16@1+ (0.05,0) [0|1000] "kWh" CM4
 SG_ HVESP12dischargeCapacity_BASE m3 : 16|16@1+ (0.01,0) [0|642.55] "Ah" CM4
 SG_ HVESP12highestCellTemp_BASE m5 : 16|16@1+ (0.03125,-273) [-273|1734.96875] "°C" CM4
 SG_ HVESP12lowestCellTemp_BASE m6 : 16|16@1+ (0.03125,-273) [-273|1734.96875] "°C" CM4
 SG_ HVESP12fastUpdateSOC_BASE m0 : 16|16@1+ (0.0015625,0) [0|100.3984375] "%" CM4
 SG_ battPack12minCellVoltage_BASE m1 : 32|16@1+ (0.0001,0) [0|6.4255] "V" CM4
 SG_ HVESP12voltageLevel_BASE m0 : 32|16@1+ (0.05,0) [0|3212.75] "V" CM4
 SG_ battPack12glblDscnnctReq_BASE m0 : 4|4@1+ (1,0) [0|15] "-" CM4
 SG_ battPack12isoMeasResPosv_BASE m2 : 4|12@1+ (2500,0) [0|10037500] "Ohm" CM4
 SG_ battPack12isoMeasResNegv_BASE m3 : 4|12@1+ (2500,0) [0|10037500] "Ohm" CM4
 SG_ HVESP12current_BASE m0 : 48|16@1+ (0.05,-1600) [-1600|1612.75] "A" CM4
 SG_ battPack12maxCellVoltage_BASE m1 : 48|16@1+ (0.0001,0) [0|6.4255] "V" CM4
 SG_ battPack12SOH_BASE m1 : 6|10@1+ (0.1,0) [0|100] "%" CM4
 SG_ battPack12modeReq_BASE m0 : 8|4@1+ (1,0) [0|0] "-" CM4

BO_ 2583677900 batteryAnalyticsPack10_BASE: 8 Vector__XXX
 SG_ battAnalyticsPack10muxID_BASE M : 0|4@1+ (1,0) [0|0] "-" CM4
 SG_ HVESP10fastUpdateSOC_BASE m0 : 16|16@1+ (0.0015625,0) [0|100.3984375] "%" CM4
 SG_ HVESP10highestCellTemp_BASE m5 : 16|16@1+ (0.03125,-273) [-273|1734.96875] "°C" CM4
 SG_ HVESP10dischargeCapacity_BASE m3 : 16|16@1+ (0.01,0) [0|642.55] "Ah" CM4
 SG_ HVESP10lowestCellTemp_BASE m6 : 16|16@1+ (0.03125,-273) [-273|1734.96875] "°C" CM4
 SG_ battPack10dschrgEthrtcMax_BASE m4 : 16|16@1+ (0.05,0) [0|1000] "kWh" CM4
 SG_ HVESP10voltageLevel_BASE m0 : 32|16@1+ (0.05,0) [0|3212.75] "V" CM4
 SG_ battPack10minCellVoltage_BASE m1 : 32|16@1+ (0.0001,0) [0|6.4255] "V" CM4
 SG_ battPack10isoMeasResPosv_BASE m2 : 4|12@1+ (2500,0) [0|10037500] "Ohm" CM4
 SG_ battPack10isoMeasResNegv_BASE m3 : 4|12@1+ (2500,0) [0|10037500] "Ohm" CM4
 SG_ battPack10glblDscnnctReq_BASE m0 : 4|4@1+ (1,0) [0|15] "-" CM4
 SG_ battPack10maxCellVoltage_BASE m1 : 48|16@1+ (0.0001,0) [0|6.4255] "V" CM4
 SG_ HVESP10current_BASE m0 : 48|16@1+ (0.05,-1600) [-1600|1612.75] "A" CM4
 SG_ battPack10SOH_BASE m1 : 6|10@1+ (0.1,0) [0|100] "%" CM4
 SG_ battPack10modeReq_BASE m0 : 8|4@1+ (1,0) [0|0] "-" CM4

BO_ 2583677939 batteryAnalyticsPack01_BASE: 8 Vector__XXX
 SG_ battAnalyticsPack01muxID_BASE M : 0|4@1+ (1,0) [0|0] "-" CM4
 SG_ battPack01dschrgEthrtcMax_BASE m4 : 16|16@1+ (0.05,0) [0|1000] "kWh" CM4
 SG_ HVESP1dischargeCapacity_BASE m3 : 16|16@1+ (0.01,0) [0|642.55] "Ah" CM4
 SG_ HVESP1fastUpdateSOC_BASE m0 : 16|16@1+ (0.0015625,0) [0|100.3984375] "%" CM4
 SG_ HVESP1highestCellTemp_BASE m5 : 16|16@1+ (0.03125,-273) [-273|1734.96875] "°C" CM4
 SG_ HVESP1lowestCellTemp_BASE m6 : 16|16@1+ (0.03125,-273) [-273|1734.96875] "°C" CM4
 SG_ battPack01minCellVoltage_BASE m1 : 32|16@1+ (0.0001,0) [0|6.4255] "V" CM4
 SG_ HVESP1voltageLevel_BASE m0 : 32|16@1+ (0.05,0) [0|3212.75] "V" CM4
 SG_ battPack01glblDscnnctReq_BASE m0 : 4|4@1+ (1,0) [0|15] "-" CM4
 SG_ battPack01isoMeasResNegv_BASE m3 : 4|12@1+ (2500,0) [0|10037500] "Ohm" CM4
 SG_ battPack01isoMeasResPosv_BASE m2 : 4|12@1+ (2500,0) [0|10037500] "Ohm" CM4
 SG_ battPack01maxCellVoltage_BASE m1 : 48|16@1+ (0.0001,0) [0|6.4255] "V" CM4
 SG_ HVESP1current_BASE m0 : 48|16@1+ (0.05,-1600) [-1600|1612.75] "A" CM4
 SG_ battPack01SOH_BASE m1 : 6|10@1+ (0.1,0) [0|100] "%" CM4
 SG_ battPack01modeReq_BASE m0 : 8|4@1+ (1,0) [0|0] "-" CM4

BO_ 2600454404 auxStatMC4_VAR1: 8 Vector__XXX
 SG_ dispDriveProgram_VAR1 : 20|4@1+ (1,0) [0|0] "-" CM4
 SG_ dispPreselDriveProgram_BASE : 28|4@1+ (1,0) [0|0] "-" CM4
 SG_ gearModeManualActive_BASE : 32|2@1+ (1,0) [0|0] "-" CM4
 SG_ dispDriveModeList_BASE : 34|2@1+ (1,0) [0|0] "-" CM4
 SG_ rollMaticActiveDisp_BASE : 36|2@1+ (1,0) [0|0] "-" CM4
 SG_ rollMaticEnabled_BASE : 38|2@1+ (1,0) [0|0] "-" CM4

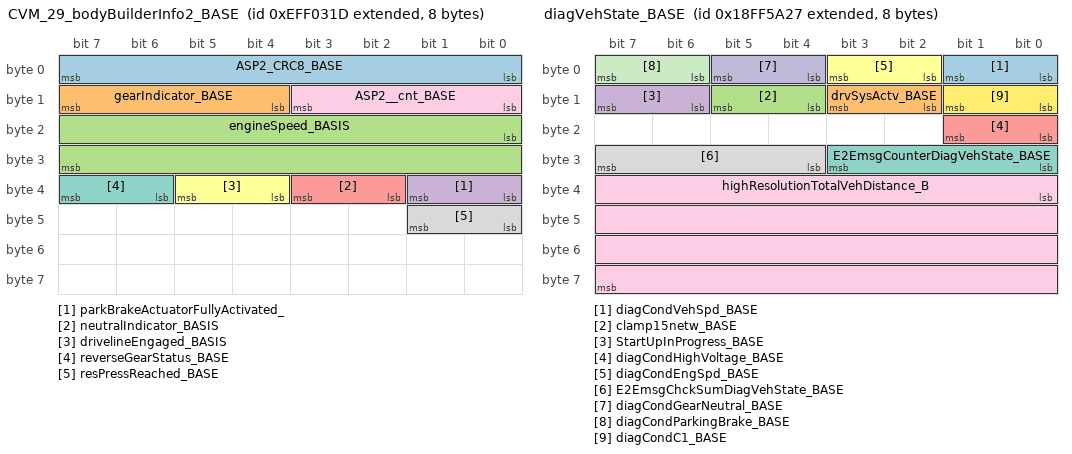
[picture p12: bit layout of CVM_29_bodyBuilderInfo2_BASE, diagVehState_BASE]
BO_ 2399077149 CVM_29_bodyBuilderInfo2_BASE: 8 Vector__XXX
 SG_ ASP2_CRC8_BASE : 0|8@1+ (1,0) [0|255] "-" CM4
 SG_ gearIndicator_BASE : 12|4@1+ (1,0) [0|0] "-" CM4
 SG_ engineSpeed_BASIS : 16|16@1+ (0.125,0) [0|8031.875] "rpm" CM4
 SG_ parkBrakeActuatorFullyActivated_ : 32|2@1+ (1,0) [0|0] "-" CM4
 SG_ neutralIndicator_BASIS : 34|2@1+ (1,0) [0|0] "-" CM4
 SG_ drivelineEngaged_BASIS : 36|2@1+ (1,0) [0|0] "-" CM4
 SG_ reverseGearStatus_BASE : 38|2@1+ (1,0) [0|0] "-" CM4
 SG_ resPressReached_BASE : 40|2@1+ (1,0) [0|0] "-" CM4
 SG_ ASP2__cnt_BASE : 8|4@1+ (1,0) [0|15] "-" CM4

BO_ 2566871591 diagVehState_BASE: 8 Vector__XXX
 SG_ diagCondVehSpd_BASE : 0|2@1+ (1,0) [0|0] "-" CM4
 SG_ drvSysActv_BASE : 10|2@1+ (1,0) [0|0] "-" CM4
 SG_ clamp15netw_BASE : 12|2@1+ (1,0) [0|0] "-" CM4
 SG_ StartUpInProgress_BASE : 14|2@1+ (1,0) [0|0] "-" CM4
 SG_ diagCondHighVoltage_BASE : 16|2@1+ (1,0) [0|0] "-" CM4
 SG_ diagCondEngSpd_BASE : 2|2@1+ (1,0) [0|0] "-" CM4
 SG_ E2EmsgCounterDiagVehState_BASE : 24|4@1+ (1,0) [0|15] "count" CM4
 SG_ E2EmsgChckSumDiagVehState_BASE : 28|4@1+ (1,0) [0|15] "count" CM4
 SG_ highResolutionTotalVehDistance_B : 32|32@1+ (0.005,0) [0|21055406] "km" CM4
 SG_ diagCondGearNeutral_BASE : 4|2@1+ (1,0) [0|0] "-" CM4
 SG_ diagCondParkingBrake_BASE : 6|2@1+ (1,0) [0|0] "-" CM4
 SG_ diagCondC1_BASE : 8|2@1+ (1,0) [0|0] "-" CM4

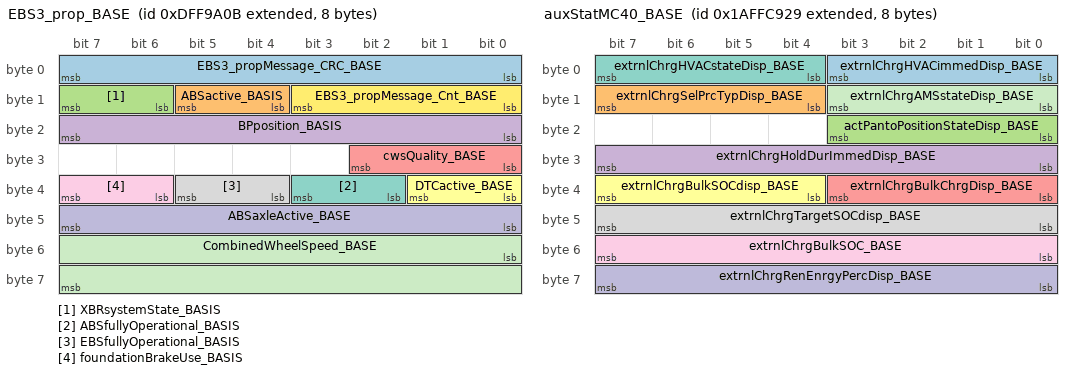
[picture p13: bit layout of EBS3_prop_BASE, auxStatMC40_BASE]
BO_ 2382338571 EBS3_prop_BASE: 8 Vector__XXX
 SG_ EBS3_propMessage_CRC_BASE : 0|8@1+ (1,0) [0|255] "-" CM4
 SG_ ABSactive_BASIS : 12|2@1+ (1,0) [0|0] "-" CM4
 SG_ XBRsystemState_BASIS : 14|2@1+ (1,0) [0|0] "-" CM4
 SG_ BPposition_BASIS : 16|8@1+ (0.4,0) [0|100] "%" CM4
 SG_ cwsQuality_BASE : 24|3@1+ (1,0) [0|0] "-" CM4
 SG_ DTCactive_BASE : 32|2@1+ (1,0) [0|0] "-" CM4
 SG_ ABSfullyOperational_BASIS : 34|2@1+ (1,0) [0|0] "-" CM4
 SG_ EBSfullyOperational_BASIS : 36|2@1+ (1,0) [0|0] "-" CM4
 SG_ foundationBrakeUse_BASIS : 38|2@1+ (1,0) [0|0] "-" CM4
 SG_ ABSaxleActive_BASE : 40|8@1+ (1,0) [0|0] "-" CM4
 SG_ CombinedWheelSpeed_BASE : 48|16@1+ (0.0078125,-251) [-251|250.9921875] "km/h" CM4
 SG_ EBS3_propMessage_Cnt_BASE : 8|4@1+ (1,0) [0|15] "-" CM4

BO_ 2600454441 auxStatMC40_BASE: 8 Vector__XXX
 SG_ extrnlChrgHVACimmedDisp_BASE : 0|4@1+ (1,0) [0|0] "-" CM4
 SG_ extrnlChrgSelPrcTypDisp_BASE : 12|4@1+ (1,0) [0|0] "-" CM4
 SG_ actPantoPositionStateDisp_BASE : 16|4@1+ (1,0) [0|0] "-" CM4
 SG_ extrnlChrgHoldDurImmedDisp_BASE : 24|8@1+ (15,0) [0|3750] "min" CM4
 SG_ extrnlChrgBulkChrgDisp_BASE : 32|4@1+ (1,0) [0|0] "-" CM4
 SG_ extrnlChrgBulkSOCdisp_BASE : 36|4@1+ (10,0) [0|100] "%" CM4
 SG_ extrnlChrgHVACstateDisp_BASE : 4|4@1+ (1,0) [0|0] "-" CM4
 SG_ extrnlChrgTargetSOCdisp_BASE : 40|8@1+ (0.5,0) [0|125] "%" CM4
 SG_ extrnlChrgBulkSOC_BASE : 48|8@1+ (0.5,0) [0|125] "%" CM4
 SG_ extrnlChrgRenEnrgyPercDisp_BASE : 56|8@1+ (1,0) [0|250] "%" CM4
 SG_ extrnlChrgAMSstateDisp_BASE : 8|4@1+ (1,0) [0|0] "-" CM4

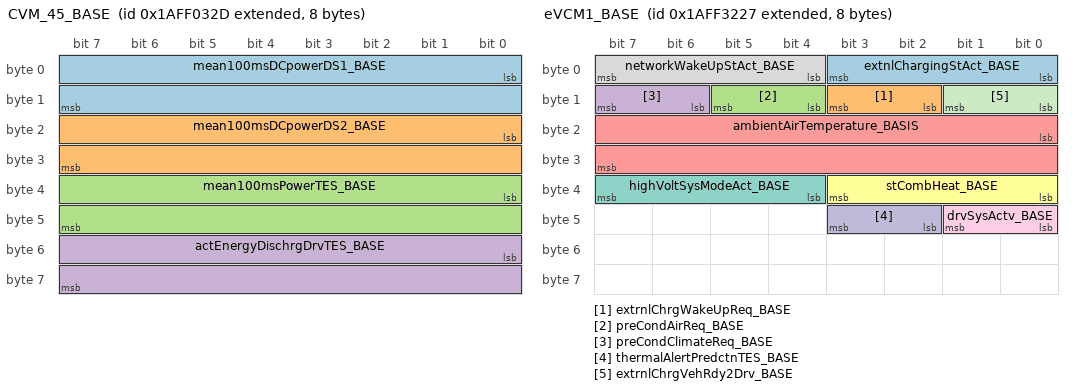
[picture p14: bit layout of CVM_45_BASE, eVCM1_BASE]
BO_ 2600403757 CVM_45_BASE: 8 Vector__XXX
 SG_ mean100msDCpowerDS1_BASE : 0|16@1+ (0.025,-800) [-800|800] "kW" CM4
 SG_ mean100msDCpowerDS2_BASE : 16|16@1+ (0.025,-800) [-800|800] "kW" CM4
 SG_ mean100msPowerTES_BASE : 32|16@1+ (0.05,-1600) [-1600|1600] "kW" CM4
 SG_ actEnergyDischrgDrvTES_BASE : 48|16@1+ (0.05,0) [0|3000] "kWh" CM4

BO_ 2600415783 eVCM1_BASE: 8 Vector__XXX
 SG_ extnlChargingStAct_BASE : 0|4@1+ (1,0) [0|0] "-" CM4
 SG_ extrnlChrgWakeUpReq_BASE : 10|2@1+ (1,0) [0|0] "-" CM4
 SG_ preCondAirReq_BASE : 12|2@1+ (1,0) [0|0] "-" CM4
 SG_ preCondClimateReq_BASE : 14|2@1+ (1,0) [0|0] "-" CM4
 SG_ ambientAirTemperature_BASIS : 16|16@1+ (0.03125,-273) [-273|1734.96875] "°C" CM4
 SG_ stCombHeat_BASE : 32|4@1+ (1,0) [0|0] "-" CM4
 SG_ highVoltSysModeAct_BASE : 36|4@1+ (1,0) [0|0] "-" CM4
 SG_ networkWakeUpStAct_BASE : 4|4@1+ (1,0) [0|0] "-" CM4
 SG_ drvSysActv_BASE : 40|2@1+ (1,0) [0|0] "-" CM4
 SG_ thermalAlertPredctnTES_BASE : 42|2@1+ (1,0) [0|0] "-" CM4
 SG_ extrnlChrgVehRdy2Drv_BASE : 8|2@1+ (1,0) [0|0] "-" CM4

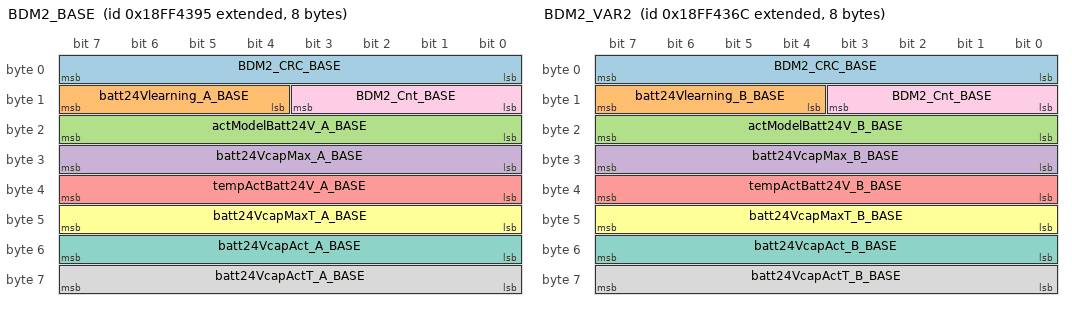
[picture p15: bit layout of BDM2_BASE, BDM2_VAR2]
BO_ 2566865813 BDM2_BASE: 8 Vector__XXX
 SG_ BDM2_CRC_BASE : 0|8@1+ (1,0) [0|255] "-" CM4
 SG_ batt24Vlearning_A_BASE : 12|4@1+ (1,0) [0|0] "-" CM4
 SG_ actModelBatt24V_A_BASE : 16|8@1+ (1,0) [0|0] "-" CM4
 SG_ batt24VcapMax_A_BASE : 24|8@1+ (1,0) [0|250] "Ah" CM4
 SG_ tempActBatt24V_A_BASE : 32|8@1+ (1,-100) [-100|150] "°C" CM4
 SG_ batt24VcapMaxT_A_BASE : 40|8@1+ (1,0) [0|250] "Ah" CM4
 SG_ batt24VcapAct_A_BASE : 48|8@1+ (1,0) [0|250] "Ah" CM4
 SG_ batt24VcapActT_A_BASE : 56|8@1+ (1,0) [0|250] "Ah" CM4
 SG_ BDM2_Cnt_BASE : 8|4@1+ (1,0) [0|15] "-" CM4

BO_ 2566865772 BDM2_VAR2: 8 Vector__XXX
 SG_ BDM2_CRC_BASE : 0|8@1+ (1,0) [0|255] "-" CM4
 SG_ batt24Vlearning_B_BASE : 12|4@1+ (1,0) [0|0] "-" CM4
 SG_ actModelBatt24V_B_BASE : 16|8@1+ (1,0) [0|0] "-" CM4
 SG_ batt24VcapMax_B_BASE : 24|8@1+ (1,0) [0|250] "Ah" CM4
 SG_ tempActBatt24V_B_BASE : 32|8@1+ (1,-100) [-100|150] "°C" CM4
 SG_ batt24VcapMaxT_B_BASE : 40|8@1+ (1,0) [0|250] "Ah" CM4
 SG_ batt24VcapAct_B_BASE : 48|8@1+ (1,0) [0|250] "Ah" CM4
 SG_ batt24VcapActT_B_BASE : 56|8@1+ (1,0) [0|250] "Ah" CM4
 SG_ BDM2_Cnt_BASE : 8|4@1+ (1,0) [0|15] "-" CM4

BO_ 2667525633 AppCommunication1_BASE: 8 Vector__XXX
 SG_ driveProgramAppVersion_BASE : 0|4@1+ (1,0) [0|15] "-" CM4
 SG_ appMinValSlider1_BASE : 12|4@1+ (0.1,0) [0|1] "-" CM4
 SG_ appValSlider1_BASE : 16|4@1+ (0.1,0) [0|1] "-" CM4
 SG_ appMaxValSlider2_BASE : 20|4@1+ (0.1,0) [0|1] "-" CM4
 SG_ appMinValSlider2_BASE : 24|4@1+ (0.1,0) [0|1] "-" CM4
 SG_ appValSlider2_BASE : 28|4@1+ (0.1,0) [0|1] "-" CM4
 SG_ appEnaSwitch3_BASE : 32|2@1+ (1,0) [0|0] "-" CM4
 SG_ appValSwitch3_BASE : 34|2@1+ (1,0) [0|0] "-" CM4
 SG_ appEnaSwitch4_BASE : 36|2@1+ (1,0) [0|0] "-" CM4
 SG_ appValSwitch4_BASE : 38|2@1+ (1,0) [0|0] "-" CM4
 SG_ appEnaSwitch1_BASE : 4|2@1+ (1,0) [0|0] "-" CM4
 SG_ appEnaSwitch5_BASE : 40|2@1+ (1,0) [0|0] "-" CM4
 SG_ appValSwitch5_BASE : 42|2@1+ (1,0) [0|0] "-" CM4
 SG_ appMaxValSlider3_BASE : 44|4@1+ (0.1,0) [0|1] "-" CM4
 SG_ appMinValSlider3_BASE : 48|4@1+ (0.1,0) [0|1] "-" CM4
 SG_ appValSlider3_BASE : 52|4@1+ (0.1,0) [0|1] "-" CM4
 SG_ appEnaSwitch2_BASE : 56|2@1+ (1,0) [0|0] "-" CM4
 SG_ appValSwitch2_BASE : 58|2@1+ (1,0) [0|0] "-" CM4
 SG_ appValSwitch1_BASE : 6|2@1+ (1,0) [0|0] "-" CM4
 SG_ appMaxValSlider1_BASE : 8|4@1+ (0.1,0) [0|1] "-" CM4

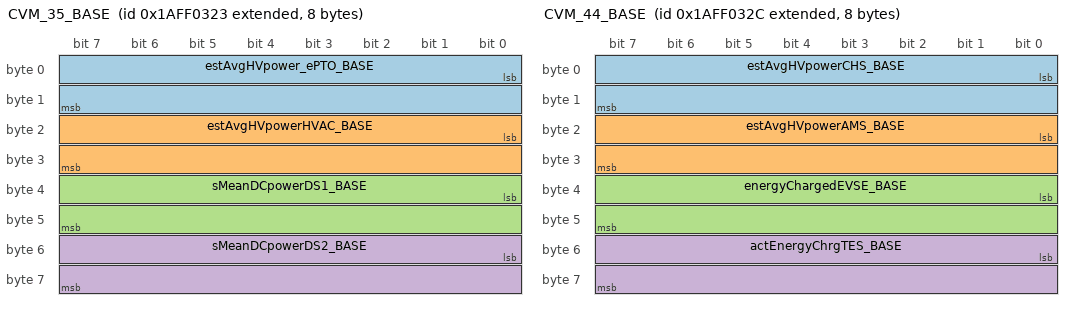
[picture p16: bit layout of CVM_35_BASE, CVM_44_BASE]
BO_ 2600403747 CVM_35_BASE: 8 Vector__XXX
 SG_ estAvgHVpower_ePTO_BASE : 0|16@1+ (0.025,-800) [-800|806.375] "kW" CM4
 SG_ estAvgHVpowerHVAC_BASE : 16|16@1+ (0.025,-800) [-800|806.375] "kW" CM4
 SG_ sMeanDCpowerDS1_BASE : 32|16@1+ (0.025,-800) [-800|800] "kW" CM4
 SG_ sMeanDCpowerDS2_BASE : 48|16@1+ (0.025,-800) [-800|800] "kW" CM4

BO_ 2600403756 CVM_44_BASE: 8 Vector__XXX
 SG_ estAvgHVpowerCHS_BASE : 0|16@1+ (0.025,-800) [-800|806.375] "kW" CM4
 SG_ estAvgHVpowerAMS_BASE : 16|16@1+ (0.025,-800) [-800|806.375] "kW" CM4
 SG_ energyChargedEVSE_BASE : 32|16@1+ (1,0) [0|64255] "kWh" CM4
 SG_ actEnergyChrgTES_BASE : 48|16@1+ (0.05,0) [0|3000] "kWh" CM4

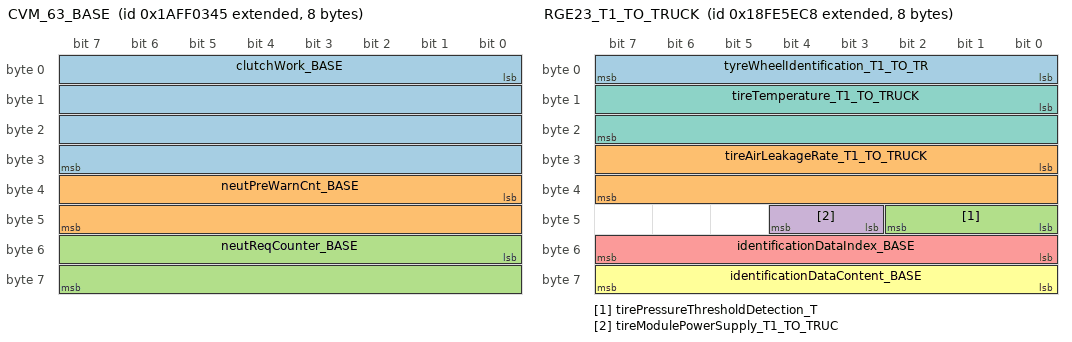
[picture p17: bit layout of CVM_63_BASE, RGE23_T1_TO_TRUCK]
BO_ 2600403781 CVM_63_BASE: 8 Vector__XXX
 SG_ clutchWork_BASE : 0|32@1+ (0.001,0) [0|4294967.294999999925494194] "kWs" CM4
 SG_ neutPreWarnCnt_BASE : 32|16@1+ (1,0) [0|65535] "-" CM4
 SG_ neutReqCounter_BASE : 48|16@1+ (1,0) [0|65535] "-" CM4

BO_ 2566807240 RGE23_T1_TO_TRUCK: 8 Vector__XXX
 SG_ tyreWheelIdentification_T1_TO_TR : 0|8@1+ (1,0) [0|0] "-" CM4
 SG_ tireAirLeakageRate_T1_TO_TRUCK : 24|16@1+ (0.1,0) [0|6425.5] "Pa/s" CM4
 SG_ tirePressureThresholdDetection_T : 40|3@1+ (1,0) [0|0] "-" CM4
 SG_ tireModulePowerSupply_T1_TO_TRUC : 43|2@1+ (1,0) [0|0] "-" CM4
 SG_ identificationDataIndex_BASE : 48|8@1+ (1,0) [0|250] "-" CM4
 SG_ identificationDataContent_BASE : 56|8@1+ (1,0) [0|250] "-" CM4
 SG_ tireTemperature_T1_TO_TRUCK : 8|16@1+ (0.03125,-273) [-273|1735] "°C" CM4

CM_ BO_ 2566845952 "Intake/Exhaust Conditions 1";
CM_ BO_ 2365289610 "Motor/Generator 1 Inverter Status 1 msg id: 0x00FB748A";
CM_ SG_ 2365289610 msgCRC8saeJ1939_BASE "CRC8 SAE J1939";
CM_ SG_ 2365289610 actMotorTrqPrcnt_BASE "The measured or estimated motor torque";
CM_ SG_ 2365289610 actMotorSpeedPrcnt_BASE "current motor speed of the drive inverter with percentage reference to the reference speed";
CM_ SG_ 2365289610 msgCNTsaeJ1939_BASE "The message counter is used to detect situations where the transmitting ECU malfunction repeats the same frame all the time. The receiver of the information may use the counter parameter to detect this situation. The transmitting device will increase the ";
CM_ BO_ 2566898183 "bodyBuilderInfo7";
CM_ BO_ 2600460823 "CAN message auxStatInst5";
CM_ SG_ 2600460823 rmtTstrInstallScreenInfo_VAR1 "This signal denotes the selected screen in the MANDIGITAL Menustructure with the following exceptions: 0: any other screen is displayed This is the signal variant for FOTA L3. The names are derived from the state names in document CV_vehicleConfiguration";
CM_ SG_ 2600460823 rmtTstrDrivRestartConfirm_BASE "This signal is set to 1 as soon as the driver confirms a restart of an installation by the RemoteTester, e.g. after a clamp30 power-off/on event. Reset when number of RemoteTester jobs is reduced by 1";
CM_ SG_ 2600460823 tsiModeReq_BASE "The signal is used to request a specific mode to the traffic sign information.";
CM_ SG_ 2600460823 tsiTolSettingReq_BASE "Request for the setting value for the speed limit tolerance for the speed limit violation warning.";
CM_ SG_ 2600460823 rmtTstrDrivEndConfirm_BASE "This signal is set to 1 as soon as the driver confirms the end of an installation by the RemoteTester. Reset when number of RemoteTester jobs is reduced by 1";
CM_ SG_ 2600460823 tsiEnableSpdWrnReq_BASE "This signal requests a change of the speed limit warning setting.";
CM_ SG_ 2600460823 tsiChangeInfoSettingReq_BASE "This signal requests a change of the sound notfication setting. The sound notification is provided when the speed limit changed.";
CM_ SG_ 2600460823 EBAactivationReqVRU_BASE "Signal of the checkbox for pre- or deselection of the EBA functionality for VRU (Vulnerable Road Users)";
CM_ SG_ 2600460823 EBAactivationReq_BASE "Signal of the checkbox for pre- or deselection of the EBA (Emergency Brake Assist)";
CM_ SG_ 2600460823 CCselectedModeReq_BASE "This signal indicates which longitudinal assistance system is requested to be preselected by the driver.";
CM_ SG_ 2600460823 reqMaxSpdPCCA_BASE "The signal indicates the requested maximum speed for PCCA by the driver interface";
CM_ SG_ 2600460823 DIGenableDistWrnReq_BASE "This signal requests a change of the distance warning setting.";
CM_ SG_ 2600460823 updtMstrDrvrNotifReq_BASE "Signal contains the driver's request to change the value of update notifications suppression.";
CM_ SG_ 2600460823 updtMstrDrvrAuth_BASE "Signal indicates if the driver authorizes the update or wants to postpone it.";
CM_ SG_ 2600460823 rmtTstrDrivUpdateConfirm_BASE "This signal is set to 1 as soon as the driver confirms the start of an installation by the RemoteTester. Reset when number of RemoteTester jobs is reduced by 1";
CM_ SG_ 2566891559 auxStatMC7cntE2E_BASE "counter of end-to-end communication protection";
CM_ SG_ 2566891559 auxStatMC7chkE2E_BASE "checksum of end-to-end communication protection";
CM_ BO_ 2566897703 "body builder configurable logic CAN output data ID: 65 86 173 204 184 21 244 138 34 208 128 185 30 2 212 137";
CM_ SG_ 2566897703 ASP2_CRC8_BASE "CRC8 Autosar Profile 2 with Data ID";
CM_ SG_ 2566897703 genericBobuOut101_BASE "Generic Output Signal CAN - bool";
CM_ SG_ 2566897703 genericBobuOut102_BASE "Generic Output Signal CAN - bool";
CM_ SG_ 2566897703 genericBobuOut103_BASE "Generic Output Signal CAN - bool";
CM_ SG_ 2566897703 genericBobuOut104_BASE "Generic Output Signal CAN - bool";
CM_ SG_ 2566897703 genericBobuOut105_BASE "Generic Input Signal via CAN - bool";
CM_ SG_ 2566897703 genericBobuOut106_BASE "Generic Input Signal via CAN - bool";
CM_ SG_ 2566897703 genericBobuOut107_BASE "Generic Input Signal via CAN - bool";
CM_ SG_ 2566897703 genericBobuOut108_BASE "Generic Input Signal via CAN - bool";
CM_ SG_ 2566897703 genericBobuOut109_BASE "Generic Input Signal via CAN - bool";
CM_ SG_ 2566897703 genericBobuOut110_BASE "Generic Input Signal via CAN - bool";
CM_ SG_ 2566897703 genericBobuOut201_BASE "Generic Output Signal via CAN - 8bit";
CM_ SG_ 2566897703 ASP2__cnt_BASE "Cnt Autosar Profile 2";
CM_ BO_ 2600407315 "prop. message for the transmission of customer-specific signals";
CM_ SG_ 2600407315 placeholderCuIntf26_BASE "placeholder signal";
CM_ BO_ 2600407314 "prop. message for the transmission of customer-specific signals";
CM_ SG_ 2600407314 placeholderCuIntf25_BASE "placeholder signal";
CM_ BO_ 2600407316 "prop. message for the transmission of customer-specific signals";
CM_ SG_ 2600407316 placeholderCuIntf27_BASE "placeholder signal";
CM_ BO_ 2600407310 "prop. message for the transmission of customer-specific signals";
CM_ SG_ 2600407310 placeholderCuIntf21_BASE "placeholder signal";
CM_ BO_ 2600407311 "prop. message for the transmission of customer-specific signals";
CM_ SG_ 2600407311 placeholderCuIntf22_BASE "placeholder signal";
CM_ BO_ 2600407312 "prop. message for the transmission of customer-specific signals";
CM_ SG_ 2600407312 placeholderCuIntf23_BASE "placeholder signal";
CM_ BO_ 2600407313 "prop. message for the transmission of customer-specific signals";
CM_ SG_ 2600407313 placeholderCuIntf24_BASE "placeholder signal";
CM_ SG_ 2565879335 HVESSDischrgPwLimDueSOC_BASE "Indicates whether or not discharge power of this HVES instance is being limited due to state of charge.";
CM_ BO_ 2600407298 "prop. message for the transmission of customer-specific signals";
CM_ SG_ 2600407298 actualMotorCurrentSumDIV_BASE "Actual DC-current of drive inverters as sum of all installed drive inverters.";
CM_ SG_ 2600407298 remainingTravelTime_BASE "The remaining travel time of the vehicle based on the remaining range and the average vehicle speed.";
CM_ SG_ 2600407298 extrnlChrgTotalEnergyChrgd_BASE "Total external energy demand over the entire vehicle life.";
CM_ BO_ 2561553175 "For setting the tire pressure reference values.&#x0D; &#x0D; This message is the setpoint for the PGN 64953 Tire Pressure reference information message.";
CM_ SG_ 2561553175 axleLocation_TPRS "To identify to which of several similar devices (such as tires or fuel tanks) the information applies.The low order 4 bits represent a position number, counting left to right when facing in the direction of normal vehicle travel (forward).The high order 4";
CM_ SG_ 2561553175 referenceTirePressureSetting_BAS "reference tire pressure setting for specific axle location";
CM_ BO_ 2566764851 "Information on actual tire pressure reference value for monitoring.&#x0D; &#x0D; NOTE: Message has to repeated as necessary to transmit all available information. This method of location identification requires individual SPs to be assigned to report fail";
CM_ SG_ 2566764851 axleLocation_TPRI "Identifies which tire is associated with the parametric data in this PG.The low order 4 bits represent a position number, counting left to right when facing in the direction of normal vehicle travel (forward).The high order 4 bits represent a position num";
CM_ SG_ 2566876977 dispFireDtctnWrning1_BASE "Fire Detection Alarm Information from FireProtection System This signal using for E4C GelenkBus's front motor cabine.";
CM_ SG_ 2566876977 dispFireDtctnWrning2_BASE "Fire Detection Alarm Information from FireProtection System This signal using for E4C GelenkBus's rear motor cabine.";
CM_ SG_ 2566876977 dispFireDtctnWrningFail2_BASE "Fire Detection system Failure is detected. This signal using for E4C GelenkBus's rear motor cabine.";
CM_ SG_ 2566876977 dispFireDtctnWrningFail1_BASE "Fire Detection system Failure is detected. This signal using for E4C GelenkBus's front motor cabine.";
CM_ SG_ 2566876977 dispFireDtctnWrningFailure_BASE "Fire Detection system Failure is detected.";
CM_ SG_ 2566876977 dispFireDtctnWrning_BASE "Fire Detection Alarm Information from FireProtection System";
CM_ SG_ 2566876977 auxHeaterFuelConsumption_BASE "Static fuel consumption of the diesel auxiliary heater";
CM_ BO_ 2566567285 "TX CAN message of the EVCC2. Data from the EVCC that reports the maximum charging limits of a DC EVSE.";
CM_ SG_ 2566567285 UmaxChrgEVSE_HR_BASE "Maximum available voltage of the EVSE.";
CM_ SG_ 2566567285 ImaxChrgEVSE_HR_BASE "Maximum available DC current of the EVSE.";
CM_ SG_ 2566567285 PmaxChrgEVSE_HR_BASE "Maximum available charging power of the EVSE.";
CM_ BO_ 2600407302 "prop. message for the transmission of customer-specific signals";
CM_ SG_ 2600407302 customerInterface13placeholder_B "Placeholder signal";
CM_ BO_ 2382347251 "harmonized BMC1 message &#x0A;Data ID Number : 232  &#x0A;Data ID : 66 112 74 181 98 126 205 157 27 24 180 6 160 129 22 1&#x0A; (in direction of increasing counter value 0 ..... 15)";
CM_ SG_ 2382347251 BMC01MsgCrc_BASE "Message checksum";
CM_ SG_ 2382347251 BattSysState_BASE "Battery system state";
CM_ SG_ 2382347251 BattSysCurr_BASE "Battery system current";
CM_ SG_ 2382347251 BattSysVltg_BASE "Battery system voltage";
CM_ SG_ 2382347251 BattSysEvacuationAlarm_BASE "Evacuation alarm";
CM_ SG_ 2382347251 BattSysCritOtWarn_BASE "Critical battery system over-temperature warning";
CM_ SG_ 2382347251 BattSysPickUpIntention_BASE "Signal indicates if pick-up of not connected battery packs is intended";
CM_ SG_ 2382347251 battSysIsoMeasOkToCharge_BASE "Battery system isolation measurement signal indicating the approval to charge. Signal value Ok to Charge indicates that no system major isolaton fault was detected.";
CM_ SG_ 2382347251 BMC01MsgCnt_BASE "Message counter";
CM_ SG_ 2600454695 dispBatt24VCheck_BASE "States for display the menue of the battery condition with 24V.";
CM_ SG_ 2600454695 dispBatt24VDischrgMnts_BASE "Estimated discharge time to be displayed in minutes until the shut off condition is met. Special value 64255: no display of discharge time.";
CM_ SG_ 2566759463 engagemStatus_transInpShaftPTO2_ "Reports if this specific PTO drive is engaged. This parameter should be broadcast only by the controller(s) receiving feedback about the specific drive. For example, a pressure switch may be used to determine if a PTO-driven pump has been engaged. If the ";
CM_ SG_ 2566759463 engagemStatus_transInpShaftPTO1_ "Reports if this specific PTO drive is engaged. This parameter should be broadcast only by the controller(s) receiving feedback about the specific drive. For example, a pressure switch may be used to determine if a PTO-driven pump has been engaged. If the ";
CM_ SG_ 2566759463 PTODEmsgCounter_BASE "The message checksum is used to verify the signal path from the transmitting device to the receiving device.";
CM_ SG_ 2566759463 PTODEchkSum_BASE "Checksum according TSC1 The message counter is used to detect situations where the transmitting ECU malfunction repeats the same frame all the time. The receiver of the information may use the counter parameter to detect this situation. The transmitting d";
CM_ SG_ 2583651111 vehProfileNormalWeight_BASE "Normal weight of the vehicle combination according current profile setting. 0 - No profile selected. 127000 - error 127500 - not available";
CM_ SG_ 2583651111 vehProfileBKClass_BASE "Entry restriction due to BK-Class classification for Sweden for road link. Initial value is set to 1 (= international), which means that BK-Classes are available in the HMI menu. User is able to set the BK-Classes on his own via HMI.";
CM_ SG_ 2583651111 vehProfileGrossWeight_BASE "Vehicle combinations maximum gross weight according profile setting. 127000 - error 127500 - not available";
CM_ SG_ 2583651111 vehProfileMaxSpd_BASE "Maximum speed according profile setting. Unit (kph or mph) is managed centrally. 254 - error 255 - not available";
CM_ SG_ 2583651111 vehProfileHazardGoods_BASE "Entry restriction due to hazardous goods load. Combined signal for all hazardous classes (1-9). If a restriction for at least one class applies, the signal shall be 1). 2046 - error 2047 - not available Bitmask Bit 0: Hazardous class 1 Bit 1: Hazardous cl";
CM_ SG_ 2583651111 vehProfileVehicleType_BASE "Signal shows the vehicle type of the current vehicle.";
CM_ SG_ 2583651111 vehProfileNmbrOfTrailer_BASE "Number of trailers according vehicle profile.";
CM_ BO_ 2600403755 "CANMSG CVM_43";
CM_ SG_ 2600403755 dispRelFricBrkPow_BASE "Displays friction brake interactions.";
CM_ SG_ 2600403755 dispFuelVolume_BASE "fuel volume to display";
CM_ SG_ 2600403755 fuelingIndicationDiesel_BASE "fueling states for diesel tank";
CM_ SG_ 2600403755 fuelTankSrvllncStatus_BASE "fuel/diesel tank surveillance status signal - indicating activated mode for fuel theft detection (concealed / acoustic) or an active alert";
CM_ BO_ 2382346791 "PGN auf DP 1&#x0A;harmonized BMC1 control message&#x0A;see  Data ID Number : 229  &#x0A;Data ID : 65 42 208 45 25 226 167 106 224 113 250 62 243 80 41 154 (&#x0A;in direction of increasing counter value 0 ..... 15)";
CM_ SG_ 2382346791 VEH01MsgCrc_BASE "Message checksum";
CM_ SG_ 2382346791 BattSysModeReq_BASE "Battery system mode request";
CM_ SG_ 2382346791 BattSysPickUpAllowed_BASE "Signal indicates if PickUp is allowed or inhibited";
CM_ SG_ 2382346791 VEH01MsgCnt_BASE "Message counter";
CM_ SG_ 2600454446 tmrMngmntTimerIndexDisp_BASE "Indicates for which of the seven timer the transferred information is related to.";
CM_ SG_ 2600454446 dStmrMngmntDaysDisp_BASE "Data set for seven timers containing the days the timer is valid provided as bitmask (0 = disabled; 1 = enabled).bit 0: Mondaybit 1: Tuesdaybit 2: Wednesday bit 3: Thursday bit 4: Friday bit 5: Saturday bit 6: Sunday CANSIG is transfering the content of o";
CM_ SG_ 2600454446 dStmrMngmntTrgtTimeDisp_BASE "Data set for seven timers containing the target time of the timer in minutes calculated from 00:00. CANSIG is transfering the content of one timer. The timer number can be identified by the multiplexor signal tmrMngmntTimerIndexDisp.";
CM_ SG_ 2600454446 dStmrMngmntHoldDurDisp_BASE "Data set for seven timers containing the holding duration of the timer. CANSIG is transfering the content of one timer. The timer number can be identified by the multiplexor signal tmrMngmntTimerIndexDisp.";
CM_ SG_ 2600454446 dStmrMngmntTmrSettgsDisp_BASE "Data set for seven timers containing the information about the timer settings provided as bitmask (0 = disabled; 1 = enabled). &#x0A;bit 0: charging timer &#x0A;bit 1: recurring &#x0A;bit 2: TES preconditioning &#x0A;bit 3: HVAC preconditioning &#x0A;bit ";
CM_ BO_ 2600454440 "CANMSG auxStatMC39";
CM_ SG_ 2600454440 extrnlChrgPrcTypStateDisp_BASE "The signal indicates the pricing type for the running/upcoming charging displayed in the cluster.";
CM_ SG_ 2600454440 extrnlChrgCurrencyDisp_BASE "The currency of the prices related for external charging.";
CM_ SG_ 2600454440 extrnlChrgParkingCostsDisp_BASE "The parking costs for the charging session.";
CM_ SG_ 2600454440 extrnlChrgChargCostsDisp_BASE "The charging costs for the charging session.";
CM_ SG_ 2600454440 extrnlChrgC02emissionDisp_BASE "The CO2 emission for the charging session.";
CM_ SG_ 2600454440 opModeVoKoESTC_BASE "Indication if the TES comfort pre-condition is active.";
CM_ SG_ 2583675635 battPack1TempSpreadMax_BASE "Maximum temperature spread within battery pack 1";
CM_ SG_ 2583675635 battPack2TempSpreadMax_BASE "Maximum temperature spread within battery pack 2";
CM_ SG_ 2583675635 battPack3TempSpreadMax_BASE "Maximum temperature spread within battery pack 3";
CM_ SG_ 2583675635 battPack4TempSpreadMax_BASE "Maximum temperature spread within battery pack 4";
CM_ SG_ 2583675635 battPack5TempSpreadMax_BASE "Maximum temperature spread within battery pack 5";
CM_ SG_ 2583675891 battPack6TempSpreadMax_BASE "Maximum temperature spread within battery pack 6";
CM_ SG_ 2583675891 battPack7TempSpreadMax_BASE "Maximum temperature spread within battery pack 7";
CM_ SG_ 2583675891 battPackLast1TempSpreadMax_BASE "Maximum temperature spread within last high voltage battery pack on the first Battery System CAN";
CM_ SG_ 2583675891 battPack9TempSpreadMax_BASE "Maximum temperature spread within battery pack 9";
CM_ SG_ 2583675891 battPack10TempSpreadMax_BASE "Maximum temperature spread within battery pack 10";
CM_ SG_ 2583676147 battPack11TempSpreadMax_BASE "Maximum temperature spread within battery pack 11";
CM_ SG_ 2583676147 battPack12TempSpreadMax_BASE "Maximum temperature spread within battery pack 12";
CM_ SG_ 2583676147 battPack13TempSpreadMax_BASE "Maximum temperature spread within battery pack 13";
CM_ SG_ 2583676147 battPack14TempSpreadMax_BASE "Maximum temperature spread within battery pack 14";
CM_ SG_ 2583676147 battPack15TempSpreadMax_BASE "Maximum temperature spread within battery pack 15";
CM_ BO_ 2600403762 "CANMSG CVM_50";
CM_ SG_ 2600403762 CVM50placeholder_BASE "Placeholder signal";
CM_ BO_ 2600403763 "CANMSG CVM_51";
CM_ SG_ 2600403763 CVM51placeholder_BASE "Placeholder signal";
CM_ BO_ 2583677942 "CANMSG for batteryAnalytics of battery pack 02.  !!!! due to EESE tool restrictions the layout is not containing all content !!!!  HVESP1voltageLevel is further presend on: layout 2 starting bit 32 layout 4 starting bit 32 layout 6 starting bit 32 layout ";
CM_ SG_ 2583677942 battAnalyticsPack02muxID_BASE "multiplexer for the CANMSG batteryAnalyticsPack02";
CM_ SG_ 2583677942 HVESP2highestCellTemp_BASE "The highest temperature level reported by any cell in High Voltage Energy Storage Pack 2.";
CM_ SG_ 2583677942 HVESP2lowestCellTemp_BASE "The lowest temperature level reported by any cell in High Voltage Energy Storage Pack 2.";
CM_ SG_ 2583677942 battPack02dschrgEthrtcMax_BASE "Maximum possible discharge energy content [kWh] of the battery pack 2 in whole SOC window.";
CM_ SG_ 2583677942 HVESP2dischargeCapacity_BASE "Discharge capacity of battery pack 2. SAE description: The amount of stored electrical charge in this High Voltage Energy Storage Pack instance that is available for use by the hybrid system, i.e. how full is the tank.";
CM_ SG_ 2583677942 HVESP2fastUpdateSOC_BASE "State of charge (SOC) of battery pack 2. SAE description: Indicates this High Voltage Energy Storage Pack instance state of charge. 0% means no charge remaining, 100% means the system is fully charged in terms of physical limits of this energy storage pac";
CM_ SG_ 2583677942 HVESP2voltageLevel_BASE "The voltage level of High Voltage Energy Storage Pack 2.";
CM_ SG_ 2583677942 battPack02minCellVoltage_BASE "The lowest voltage level reported by any cell in battery pack 2.";
CM_ SG_ 2583677942 battPack02isoMeasResNegv_BASE "Resistance of the isolation measurement for HV-.";
CM_ SG_ 2583677942 battPack02isoMeasResPosv_BASE "Resistance of the isolation measurement for HV+.";
CM_ SG_ 2583677942 battPack02glblDscnnctReq_BASE "Request from the battery pack to disconnect all packs in the battery system.";
CM_ SG_ 2583677942 battPack02maxCellVoltage_BASE "The highest voltage level reported by any cell in battery pack 2.";
CM_ SG_ 2583677942 HVESP2current_BASE "The current in or out of High Voltage Energy Storage Pack2.";
CM_ SG_ 2583677942 battPack02SOH_BASE "High voltage battery pack 2 state of health.";
CM_ SG_ 2583677942 battPack02modeReq_BASE "Mode Request for battery pack 02";
CM_ BO_ 2583677881 "CANMSG for batteryAnalytics of battery pack 03.  !!!! due to EESE tool restrictions the layout is not containing all content !!!!  HVESP1voltageLevel is further presend on: layout 2 starting bit 32 layout 4 starting bit 32 layout 6 starting bit 32 layout ";
CM_ SG_ 2583677881 battAnalyticsPack03muxID_BASE "multiplexer for the CANMSG batteryAnalyticsPack03";
CM_ SG_ 2583677881 HVESP3highestCellTemp_BASE "The highest temperature level reported by any cell in High Voltage Energy Storage Pack .";
CM_ SG_ 2583677881 HVESP3lowestCellTemp_BASE "The lowest temperature level reported by any cell in High Voltage Energy Storage Pack 3.";
CM_ SG_ 2583677881 battPack03dschrgEthrtcMax_BASE "Maximum possible discharge energy content [kWh] of the battery pack 3 in whole SOC window.";
CM_ SG_ 2583677881 HVESP3dischargeCapacity_BASE "Discharge capacity of battery pack 3. SAE description: The amount of stored electrical charge in this High Voltage Energy Storage Pack instance that is available for use by the hybrid system, i.e. how full is the tank.";
CM_ SG_ 2583677881 HVESP3fastUpdateSOC_BASE "State of charge (SOC) of battery pack 3. SAE description: Indicates this High Voltage Energy Storage Pack instance state of charge. 0% means no charge remaining, 100% means the system is fully charged in terms of physical limits of this energy storage pac";
CM_ SG_ 2583677881 battPack03minCellVoltage_BASE "The lowest voltage level reported by any cell in battery pack 3.";
CM_ SG_ 2583677881 HVESP3voltageLevel_BASE "The voltage level of High Voltage Energy Storage Pack 3.";
CM_ SG_ 2583677881 battPack03isoMeasResPosv_BASE "Resistance of the isolation measurement for HV+.";
CM_ SG_ 2583677881 battPack03isoMeasResNegv_BASE "Resistance of the isolation measurement for HV-.";
CM_ SG_ 2583677881 battPack03glblDscnnctReq_BASE "Request from the battery pack to disconnect all packs in the battery system.";
CM_ SG_ 2583677881 HVESP3current_BASE "The current in or out of High Voltage Energy Storage Pack 3.";
CM_ SG_ 2583677881 battPack03maxCellVoltage_BASE "The highest voltage level reported by any cell in battery pack 3.";
CM_ SG_ 2583677881 battPack03SOH_BASE "High voltage battery pack 3 state of health.";
CM_ SG_ 2583677881 battPack03modeReq_BASE "Mode Request for battery pack 03";
CM_ BO_ 2583677882 "CANMSG for batteryAnalytics of battery pack 04.  !!!! due to EESE tool restrictions the layout is not containing all content !!!!  HVESP1voltageLevel is further presend on: layout 2 starting bit 32 layout 4 starting bit 32 layout 6 starting bit 32 layout ";
CM_ SG_ 2583677882 battAnalyticsPack04muxID_BASE "multiplexer for the CANMSG batteryAnalyticsPack04";
CM_ SG_ 2583677882 battPack04dschrgEthrtcMax_BASE "Maximum possible discharge energy content [kWh] of the battery pack 4 in whole SOC window.";
CM_ SG_ 2583677882 HVESP4lowestCellTemp_BASE "The lowest temperature level reported by any cell in High Voltage Energy Storage Pack 4.";
CM_ SG_ 2583677882 HVESP4highestCellTemp_BASE "The highest temperature level reported by any cell in High Voltage Energy Storage Pack 4.";
CM_ SG_ 2583677882 HVESP4dischargeCapacity_BASE "Discharge capacity of battery pack 4. SAE description: The amount of stored electrical charge in this High Voltage Energy Storage Pack instance that is available for use by the hybrid system, i.e. how full is the tank.";
CM_ SG_ 2583677882 HVESP4fastUpdateSOC_BASE "State of charge (SOC) of battery pack 4. SAE description: Indicates this High Voltage Energy Storage Pack instance state of charge. 0% means no charge remaining, 100% means the system is fully charged in terms of physical limits of this energy storage pac";
CM_ SG_ 2583677882 HVESP4voltageLevel_BASE "The voltage level of High Voltage Energy Storage Pack 4.";
CM_ SG_ 2583677882 battPack04minCellVoltage_BASE "The lowest voltage level reported by any cell in battery pack 4.";
CM_ SG_ 2583677882 battPack04isoMeasResPosv_BASE "Resistance of the isolation measurement for HV+.";
CM_ SG_ 2583677882 battPack04glblDscnnctReq_BASE "Request from the battery pack to disconnect all packs in the battery system.";
CM_ SG_ 2583677882 battPack04isoMeasResNegv_BASE "Resistance of the isolation measurement for HV-.";
CM_ SG_ 2583677882 battPack04maxCellVoltage_BASE "The highest voltage level reported by any cell in battery pack 4.";
CM_ SG_ 2583677882 HVESP4current_BASE "The current in or out of High Voltage Energy Storage Pack 4.";
CM_ SG_ 2583677882 battPack04SOH_BASE "High voltage battery pack 4 state of health.";
CM_ SG_ 2583677882 battPack04modeReq_BASE "Mode Request for battery pack 04";
CM_ BO_ 2583677883 "CANMSG for batteryAnalytics of battery pack 05.  !!!! due to EESE tool restrictions the layout is not containing all content !!!!  HVESP1voltageLevel is further presend on: layout 2 starting bit 32 layout 4 starting bit 32 layout 6 starting bit 32 layout ";
CM_ SG_ 2583677883 battAnalyticsPack05muxID_BASE "multiplexer for the CANMSG batteryAnalyticsPack05";
CM_ SG_ 2583677883 battPack05dschrgEthrtcMax_BASE "Maximum possible discharge energy content [kWh] of the battery pack 5 in whole SOC window.";
CM_ SG_ 2583677883 HVESP5lowestCellTemp_BASE "The lowest temperature level reported by any cell in High Voltage Energy Storage Pack 5.";
CM_ SG_ 2583677883 HVESP5highestCellTemp_BASE "The highest temperature level reported by any cell in High Voltage Energy Storage Pack 5.";
CM_ SG_ 2583677883 HVESP5fastUpdateSOC_BASE "State of charge (SOC) of battery pack 5. SAE description: Indicates this High Voltage Energy Storage Pack instance state of charge. 0% means no charge remaining, 100% means the system is fully charged in terms of physical limits of this energy storage pac";
CM_ SG_ 2583677883 HVESP5dischargeCapacity_BASE "Discharge capacity of battery pack 5. SAE description: The amount of stored electrical charge in this High Voltage Energy Storage Pack instance that is available for use by the hybrid system, i.e. how full is the tank.";
CM_ SG_ 2583677883 battPack05minCellVoltage_BASE "The lowest voltage level reported by any cell in battery pack 5.";
CM_ SG_ 2583677883 HVESP5voltageLevel_BASE "The voltage level of High Voltage Energy Storage Pack 5.";
CM_ SG_ 2583677883 battPack05glblDscnnctReq_BASE "Request from the battery pack to disconnect all packs in the battery system.";
CM_ SG_ 2583677883 battPack05isoMeasResNegv_BASE "Resistance of the isolation measurement for HV-.";
CM_ SG_ 2583677883 battPack05isoMeasResPosv_BASE "Resistance of the isolation measurement for HV+.";
CM_ SG_ 2583677883 HVESP5current_BASE "The current in or out of High Voltage Energy Storage Pack 5.";
CM_ SG_ 2583677883 battPack05maxCellVoltage_BASE "The highest voltage level reported by any cell in battery pack 5.";
CM_ SG_ 2583677883 battPack05SOH_BASE "High voltage battery pack 5 state of health.";
CM_ SG_ 2583677883 battPack05modeReq_BASE "Mode Request for battery pack 05";
CM_ BO_ 2583677884 "CANMSG for batteryAnalytics of battery pack 06.  !!!! due to EESE tool restrictions the layout is not containing all content !!!!  HVESP1voltageLevel is further presend on: layout 2 starting bit 32 layout 4 starting bit 32 layout 6 starting bit 32 layout ";
CM_ SG_ 2583677884 battAnalyticsPack06muxID_BASE "multiplexer for the CANMSG batteryAnalyticsPack06";
CM_ SG_ 2583677884 battPack06dschrgEthrtcMax_BASE "Maximum possible discharge energy content [kWh] of the battery pack 6 in whole SOC window.";
CM_ SG_ 2583677884 HVESP6highestCellTemp_BASE "The highest temperature level reported by any cell in High Voltage Energy Storage Pack 6.";
CM_ SG_ 2583677884 HVESP6lowestCellTemp_BASE "The lowest temperature level reported by any cell in High Voltage Energy Storage Pack 6.";
CM_ SG_ 2583677884 HVESP6dischargeCapacity_BASE "Discharge capacity of battery pack 6. SAE description: The amount of stored electrical charge in this High Voltage Energy Storage Pack instance that is available for use by the hybrid system, i.e. how full is the tank.";
CM_ SG_ 2583677884 HVESP6fastUpdateSOC_BASE "State of charge (SOC) of battery pack 6. SAE description: Indicates this High Voltage Energy Storage Pack instance state of charge. 0% means no charge remaining, 100% means the system is fully charged in terms of physical limits of this energy storage pac";
CM_ SG_ 2583677884 HVESP6voltageLevel_BASE "The voltage level of High Voltage Energy Storage Pack 6.";
CM_ SG_ 2583677884 battPack06minCellVoltage_BASE "The lowest voltage level reported by any cell in battery pack 6.";
CM_ SG_ 2583677884 battPack06isoMeasResPosv_BASE "Resistance of the isolation measurement for HV+.";
CM_ SG_ 2583677884 battPack06isoMeasResNegv_BASE "Resistance of the isolation measurement for HV-.";
CM_ SG_ 2583677884 battPack06glblDscnnctReq_BASE "Request from the battery pack to disconnect all packs in the battery system.";
CM_ SG_ 2583677884 battPack06maxCellVoltage_BASE "The highest voltage level reported by any cell in battery pack 6.";
CM_ SG_ 2583677884 HVESP6current_BASE "The current in or out of High Voltage Energy Storage Pack 6.";
CM_ SG_ 2583677884 battPack06SOH_BASE "High voltage battery pack 6 state of health.";
CM_ SG_ 2583677884 battPack06modeReq_BASE "Mode Request for battery pack 06";
CM_ BO_ 2583677886 "CANMSG for batteryAnalytics of battery pack 07.  !!!! due to EESE tool restrictions the layout is not containing all content !!!!  HVESP1voltageLevel is further presend on: layout 2 starting bit 32 layout 4 starting bit 32 layout 6 starting bit 32 layout ";
CM_ SG_ 2583677886 battAnalyticsPack07muxID_BASE "multiplexer for the CANMSG batteryAnalyticsPack07";
CM_ SG_ 2583677886 HVESP7highestCellTemp_BASE "The highest temperature level reported by any cell in High Voltage Energy Storage Pack 7.";
CM_ SG_ 2583677886 battPack07dschrgEthrtcMax_BASE "Maximum possible discharge energy content [kWh] of the battery pack 7 in whole SOC window.";
CM_ SG_ 2583677886 HVESP7lowestCellTemp_BASE "The lowest temperature level reported by any cell in High Voltage Energy Storage Pack 7.";
CM_ SG_ 2583677886 HVESP7dischargeCapacity_BASE "Discharge capacity of battery pack 7. SAE description: The amount of stored electrical charge in this High Voltage Energy Storage Pack instance that is available for use by the hybrid system, i.e. how full is the tank.";
CM_ SG_ 2583677886 HVESP7fastUpdateSOC_BASE "State of charge (SOC) of battery pack 7. SAE description: Indicates this High Voltage Energy Storage Pack instance state of charge. 0% means no charge remaining, 100% means the system is fully charged in terms of physical limits of this energy storage pac";
CM_ SG_ 2583677886 battPack07minCellVoltage_BASE "The lowest voltage level reported by any cell in battery pack 7.";
CM_ SG_ 2583677886 HVESP7voltageLevel_BASE "The voltage level of High Voltage Energy Storage Pack 7.";
CM_ SG_ 2583677886 battPack07isoMeasResNegv_BASE "Resistance of the isolation measurement for HV-.";
CM_ SG_ 2583677886 battPack07isoMeasResPosv_BASE "Resistance of the isolation measurement for HV+.";
CM_ SG_ 2583677886 battPack07glblDscnnctReq_BASE "Request from the battery pack to disconnect all packs in the battery system.";
CM_ SG_ 2583677886 HVESP7current_BASE "The current in or out of High Voltage Energy Storage Pack 7.";
CM_ SG_ 2583677886 battPack07maxCellVoltage_BASE "The highest voltage level reported by any cell in battery pack 7.";
CM_ SG_ 2583677886 battPack07SOH_BASE "High voltage battery pack 7 state of health.";
CM_ SG_ 2583677886 battPack07modeReq_BASE "Mode Request for battery pack 07";
CM_ BO_ 2583677894 "CANMSG for batteryAnalytics of battery pack 08.  !!!! due to EESE tool restrictions the layout is not containing all content !!!!  HVESP1voltageLevel is further presend on: layout 2 starting bit 32 layout 4 starting bit 32 layout 6 starting bit 32 layout ";
CM_ SG_ 2583677894 battAnalyticsPack08muxID_BASE "multiplexer for the CANMSG batteryAnalyticsPack08";
CM_ SG_ 2583677894 HVESP8lowestCellTemp_BASE "The lowest temperature level reported by any cell in High Voltage Energy Storage Pack 8.";
CM_ SG_ 2583677894 HVESP8highestCellTemp_BASE "The highest temperature level reported by any cell in High Voltage Energy Storage Pack 8.";
CM_ SG_ 2583677894 battPack08dschrgEthrtcMax_BASE "Maximum possible discharge energy content [kWh] of the battery pack 8 in whole SOC window.";
CM_ SG_ 2583677894 HVESP8dischargeCapacity_BASE "Discharge capacity of battery pack 8. SAE description: The amount of stored electrical charge in this High Voltage Energy Storage Pack instance that is available for use by the hybrid system, i.e. how full is the tank.";
CM_ SG_ 2583677894 HVESP8fastUpdateSOC_BASE "State of charge (SOC) of battery pack 8. SAE description: Indicates this High Voltage Energy Storage Pack instance state of charge. 0% means no charge remaining, 100% means the system is fully charged in terms of physical limits of this energy storage pac";
CM_ SG_ 2583677894 HVESP8voltageLevel_BASE "The voltage level of High Voltage Energy Storage Pack 8.";
CM_ SG_ 2583677894 battPack08minCellVoltage_BASE "The lowest voltage level reported by any cell in battery pack 8.";
CM_ SG_ 2583677894 battPack08isoMeasResNegv_BASE "Resistance of the isolation measurement for HV-.";
CM_ SG_ 2583677894 battPack08isoMeasResPosv_BASE "Resistance of the isolation measurement for HV+.";
CM_ SG_ 2583677894 battPack08glblDscnnctReq_BASE "Request from the battery pack to disconnect all packs in the battery system.";
CM_ SG_ 2583677894 HVESP8current_BASE "The current in or out of High Voltage Energy Storage Pack 8.";
CM_ SG_ 2583677894 battPack08maxCellVoltage_BASE "The highest voltage level reported by any cell in battery pack 8.";
CM_ SG_ 2583677894 battPack08SOH_BASE "High voltage battery pack 8 state of health.";
CM_ SG_ 2583677894 battPack08modeReq_BASE "Mode Request for battery pack 08";
CM_ BO_ 2583677895 "CANMSG for batteryAnalytics of battery pack 09.  !!!! due to EESE tool restrictions the layout is not containing all content !!!!  HVESP1voltageLevel is further presend on: layout 2 starting bit 32 layout 4 starting bit 32 layout 6 starting bit 32 layout ";
CM_ SG_ 2583677895 battAnalyticsPack09muxID_BASE "multiplexer for the CANMSG batteryAnalyticsPack09";
CM_ SG_ 2583677895 HVESP9fastUpdateSOC_BASE "State of charge (SOC) of battery pack 9. SAE description: Indicates this High Voltage Energy Storage Pack instance state of charge. 0% means no charge remaining, 100% means the system is fully charged in terms of physical limits of this energy storage pac";
CM_ SG_ 2583677895 battPack09dschrgEthrtcMax_BASE "Maximum possible discharge energy content [kWh] of the battery pack 9 in whole SOC window.";
CM_ SG_ 2583677895 HVESP9lowestCellTemp_BASE "The lowest temperature level reported by any cell in High Voltage Energy Storage Pack 9.";
CM_ SG_ 2583677895 HVESP9dischargeCapacity_BASE "Discharge capacity of battery pack 9. SAE description: The amount of stored electrical charge in this High Voltage Energy Storage Pack instance that is available for use by the hybrid system, i.e. how full is the tank.";
CM_ SG_ 2583677895 HVESP9highestCellTemp_BASE "The highest temperature level reported by any cell in High Voltage Energy Storage Pack 9.";
CM_ SG_ 2583677895 battPack09minCellVoltage_BASE "The lowest voltage level reported by any cell in battery pack 9.";
CM_ SG_ 2583677895 HVESP9voltageLevel_BASE "The voltage level of High Voltage Energy Storage Pack 9.";
CM_ SG_ 2583677895 battPack09isoMeasResPosv_BASE "Resistance of the isolation measurement for HV+.";
CM_ SG_ 2583677895 battPack09glblDscnnctReq_BASE "Request from the battery pack to disconnect all packs in the battery system.";
CM_ SG_ 2583677895 battPack09isoMeasResNegv_BASE "Resistance of the isolation measurement for HV-.";
CM_ SG_ 2583677895 HVESP9current_BASE "The current in or out of High Voltage Energy Storage Pack9.";
CM_ SG_ 2583677895 battPack09maxCellVoltage_BASE "The highest voltage level reported by any cell in battery pack 9.";
CM_ SG_ 2583677895 battPack09SOH_BASE "High voltage battery pack 9 state of health.";
CM_ SG_ 2583677895 battPack09modeReq_BASE "Mode Request for battery pack 09";
CM_ BO_ 2583677902 "CANMSG for batteryAnalytics of battery pack 11.  !!!! due to EESE tool restrictions the layout is not containing all content !!!!  HVESP1voltageLevel is further presend on: layout 2 starting bit 32 layout 4 starting bit 32 layout 6 starting bit 32 layout ";
CM_ SG_ 2583677902 battAnalyticsPack11muxID_BASE "multiplexer for the CANMSG batteryAnalyticsPack11";
CM_ SG_ 2583677902 HVESP11highestCellTemp_BASE "The highest temperature level reported by any cell in High Voltage Energy Storage Pack 11.";
CM_ SG_ 2583677902 HVESP11fastUpdateSOC_BASE "State of charge (SOC) of battery pack 11. SAE description: Indicates this High Voltage Energy Storage Pack instance state of charge. 0% means no charge remaining, 100% means the system is fully charged in terms of physical limits of this energy storage pa";
CM_ SG_ 2583677902 battPack11dschrgEthrtcMax_BASE "Maximum possible discharge energy content [kWh] of the battery pack 11 in whole SOC window.";
CM_ SG_ 2583677902 HVESP11dischargeCapacity_BASE "Discharge capacity of battery pack 11. SAE description: The amount of stored electrical charge in this High Voltage Energy Storage Pack instance that is available for use by the hybrid system, i.e. how full is the tank.";
CM_ SG_ 2583677902 HVESP11lowestCellTemp_BASE "The lowest temperature level reported by any cell in High Voltage Energy Storage Pack 11.";
CM_ SG_ 2583677902 HVESP11voltageLevel_BASE "The voltage level of High Voltage Energy Storage Pack 11.";
CM_ SG_ 2583677902 battPack11minCellVoltage_BASE "The lowest voltage level reported by any cell in battery pack 11.";
CM_ SG_ 2583677902 battPack11glblDscnnctReq_BASE "Request from the battery pack to disconnect all packs in the battery system.";
CM_ SG_ 2583677902 battPack11isoMeasResNegv_BASE "Resistance of the isolation measurement for HV-.";
CM_ SG_ 2583677902 battPack11isoMeasResPosv_BASE "Resistance of the isolation measurement for HV+.";
CM_ SG_ 2583677902 battPack11maxCellVoltage_BASE "The highest voltage level reported by any cell in battery pack 11.";
CM_ SG_ 2583677902 HVESP11current_BASE "The current in or out of High Voltage Energy Storage Pack11.";
CM_ SG_ 2583677902 battPack11SOH_BASE "High voltage battery pack 11 state of health.";
CM_ SG_ 2583677902 battPack11modeReq_BASE "Mode Request for battery pack 11";
CM_ BO_ 2583677903 "CANMSG for batteryAnalytics of battery pack 12.  !!!! due to EESE tool restrictions the layout is not containing all content !!!!  HVESP1voltageLevel is further presend on: layout 2 starting bit 32 layout 4 starting bit 32 layout 6 starting bit 32 layout ";
CM_ SG_ 2583677903 battAnalyticsPack12muxID_BASE "multiplexer for the CANMSG batteryAnalyticsPack12";
CM_ SG_ 2583677903 battPack12dschrgEthrtcMax_BASE "Maximum possible discharge energy content [kWh] of the battery pack 12 in whole SOC window.";
CM_ SG_ 2583677903 HVESP12dischargeCapacity_BASE "Discharge capacity of battery pack 12. SAE description: The amount of stored electrical charge in this High Voltage Energy Storage Pack instance that is available for use by the hybrid system, i.e. how full is the tank.";
CM_ SG_ 2583677903 HVESP12highestCellTemp_BASE "The highest temperature level reported by any cell in High Voltage Energy Storage Pack 12.";
CM_ SG_ 2583677903 HVESP12lowestCellTemp_BASE "The lowest temperature level reported by any cell in High Voltage Energy Storage Pack 12.";
CM_ SG_ 2583677903 HVESP12fastUpdateSOC_BASE "State of charge (SOC) of battery pack 12. SAE description: Indicates this High Voltage Energy Storage Pack instance state of charge. 0% means no charge remaining, 100% means the system is fully charged in terms of physical limits of this energy storage pa";
CM_ SG_ 2583677903 battPack12minCellVoltage_BASE "The lowest voltage level reported by any cell in battery pack 12.";
CM_ SG_ 2583677903 HVESP12voltageLevel_BASE "The voltage level of High Voltage Energy Storage Pack 12.";
CM_ SG_ 2583677903 battPack12glblDscnnctReq_BASE "Request from the battery pack to disconnect all packs in the battery system.";
CM_ SG_ 2583677903 battPack12isoMeasResPosv_BASE "Resistance of the isolation measurement for HV+.";
CM_ SG_ 2583677903 battPack12isoMeasResNegv_BASE "Resistance of the isolation measurement for HV-.";
CM_ SG_ 2583677903 HVESP12current_BASE "The current in or out of High Voltage Energy Storage Pack12.";
CM_ SG_ 2583677903 battPack12maxCellVoltage_BASE "The highest voltage level reported by any cell in battery pack 12.";
CM_ SG_ 2583677903 battPack12SOH_BASE "High voltage battery pack 12 state of health.";
CM_ SG_ 2583677903 battPack12modeReq_BASE "Mode Request for battery pack 12";
CM_ BO_ 2583677900 "CANMSG for batteryAnalytics of battery pack 10.  !!!! due to EESE tool restrictions the layout is not containing all content !!!!  HVESP1voltageLevel is further presend on: layout 2 starting bit 32 layout 4 starting bit 32 layout 6 starting bit 32 layout ";
CM_ SG_ 2583677900 battAnalyticsPack10muxID_BASE "multiplexer for the CANMSG batteryAnalyticsPack10";
CM_ SG_ 2583677900 HVESP10fastUpdateSOC_BASE "State of charge (SOC) of battery pack 10. SAE description: Indicates this High Voltage Energy Storage Pack instance state of charge. 0% means no charge remaining, 100% means the system is fully charged in terms of physical limits of this energy storage pa";
CM_ SG_ 2583677900 HVESP10highestCellTemp_BASE "The highest temperature level reported by any cell in High Voltage Energy Storage Pack 10.";
CM_ SG_ 2583677900 HVESP10dischargeCapacity_BASE "Discharge capacity of battery pack 10. SAE description: The amount of stored electrical charge in this High Voltage Energy Storage Pack instance that is available for use by the hybrid system, i.e. how full is the tank.";
CM_ SG_ 2583677900 HVESP10lowestCellTemp_BASE "The lowest temperature level reported by any cell in High Voltage Energy Storage Pack 10.";
CM_ SG_ 2583677900 battPack10dschrgEthrtcMax_BASE "Maximum possible discharge energy content [kWh] of the battery pack 10 in whole SOC window.";
CM_ SG_ 2583677900 HVESP10voltageLevel_BASE "The voltage level of High Voltage Energy Storage Pack 10.";
CM_ SG_ 2583677900 battPack10minCellVoltage_BASE "The lowest voltage level reported by any cell in battery pack 10.";
CM_ SG_ 2583677900 battPack10isoMeasResPosv_BASE "Resistance of the isolation measurement for HV+.";
CM_ SG_ 2583677900 battPack10isoMeasResNegv_BASE "Resistance of the isolation measurement for HV-.";
CM_ SG_ 2583677900 battPack10glblDscnnctReq_BASE "Request from the battery pack to disconnect all packs in the battery system.";
CM_ SG_ 2583677900 battPack10maxCellVoltage_BASE "The highest voltage level reported by any cell in battery pack 10.";
CM_ SG_ 2583677900 HVESP10current_BASE "The current in or out of High Voltage Energy Storage Pack10.";
CM_ SG_ 2583677900 battPack10SOH_BASE "High voltage battery pack 10 state of health.";
CM_ SG_ 2583677900 battPack10modeReq_BASE "Mode Request for battery pack 10";
CM_ BO_ 2583677939 "CANMSG for batteryAnalytics of battery pack 01.  !!!! due to EESE tool restrictions the layout is not containing all content !!!!  HVESP1voltageLevel is further presend on: layout 2 starting bit 32 layout 4 starting bit 32 layout 6 starting bit 32 layout ";
CM_ SG_ 2583677939 battAnalyticsPack01muxID_BASE "multiplexer for the CANMSG batteryAnalyticsPack01";
CM_ SG_ 2583677939 battPack01dschrgEthrtcMax_BASE "Maximum possible discharge energy content [kWh] of the battery pack 1 in whole SOC window.";
CM_ SG_ 2583677939 HVESP1dischargeCapacity_BASE "Discharge capacity of battery pack 1. SAE description: The amount of stored electrical charge in this High Voltage Energy Storage Pack instance that is available for use by the hybrid system, i.e. how full is the tank.";
CM_ SG_ 2583677939 HVESP1fastUpdateSOC_BASE "State of charge (SOC) of battery pack 1. SAE description: Indicates this High Voltage Energy Storage Pack instance state of charge. 0% means no charge remaining, 100% means the system is fully charged in terms of physical limits of this energy storage pac";
CM_ SG_ 2583677939 HVESP1highestCellTemp_BASE "The highest temperature level reported by any cell in High Voltage Energy Storage Pack 1.";
CM_ SG_ 2583677939 HVESP1lowestCellTemp_BASE "The lowest temperature level reported by any cell in High Voltage Energy Storage Pack 1.";
CM_ SG_ 2583677939 battPack01minCellVoltage_BASE "The lowest voltage level reported by any cell in battery pack 1.";
CM_ SG_ 2583677939 HVESP1voltageLevel_BASE "The voltage level of High Voltage Energy Storage Pack 1.";
CM_ SG_ 2583677939 battPack01glblDscnnctReq_BASE "Request from the battery pack to disconnect all packs in the battery system.";
CM_ SG_ 2583677939 battPack01isoMeasResNegv_BASE "Resistance of the isolation measurement for HV-.";
CM_ SG_ 2583677939 battPack01isoMeasResPosv_BASE "Resistance of the isolation measurement for HV+.";
CM_ SG_ 2583677939 battPack01maxCellVoltage_BASE "The highest voltage level reported by any cell in battery pack 1.";
CM_ SG_ 2583677939 HVESP1current_BASE "The current in or out of High Voltage Energy Storage Pack 1.";
CM_ SG_ 2583677939 battPack01SOH_BASE "High voltage battery pack 1 state of health.";
CM_ BO_ 2600454404 "CAN message auxStatMC4";
CM_ SG_ 2600454404 dispDriveModeList_BASE "Signal requests to activate the drive program menu entries.";
CM_ BO_ 2399077149 "CVM_29 body builder info 2 message; ASP2; Data Id no: 460; Data Id: 68 115 48 46 167 174 64 150 51 88 132 54 241 67 191 102;";
CM_ SG_ 2399077149 ASP2_CRC8_BASE "CRC8 Autosar Profile 2 with Data ID";
CM_ SG_ 2399077149 gearIndicator_BASE "Direction information of the currently engaged gear.";
CM_ SG_ 2399077149 engineSpeed_BASIS "Actual engine speed which is calculated over a minimum crankshaft angle of 720 degrees divided by the number of cylinders.";
CM_ SG_ 2399077149 parkBrakeActuatorFullyActivated_ "Signal which indicates when the parking brake actuator is fully activated.";
CM_ SG_ 2399077149 drivelineEngaged_BASIS "Driveline engaged indicates the transmission controlled portion of the driveline is engaged sufficiently to allow a transfer of torque through the transmission. Driveline engaged is ACTIVE whenever the transmission is in gear and the clutch (if controlled";
CM_ SG_ 2399077149 reverseGearStatus_BASE "This signal indicates if the reverse gear at the gearshift box of the commercial vehicle is engaged or not.";
CM_ SG_ 2399077149 resPressReached_BASE "The signal indicates that the residual pressure maintenance is active and the residual pressure is balanced out.";
CM_ SG_ 2399077149 ASP2__cnt_BASE "Cnt Autosar Profile 2";
CM_ BO_ 2566871591 "Proprietary CAN message diagVehState which provides relevant information about the vehicle needed for diagnostic purposes.  Remark for checksum:  Checksum = (Byte1 + Byte2 + Byte3 + Byte5 + Byte6 + Byte7 + Byte8 + (message counter & 0x0F) + message ID low";
CM_ SG_ 2566871591 diagCondVehSpd_BASE "vehicle condition for diagnosis: vehicle is standing still";
CM_ SG_ 2566871591 drvSysActv_BASE "The signal describes whether the drive system is ready for operation.";
CM_ SG_ 2566871591 clamp15netw_BASE "CAN signal to communicate the state of clamp 15";
CM_ SG_ 2566871591 diagCondHighVoltage_BASE "vehicle condition for diagnosis: high voltage isolated";
CM_ SG_ 2566871591 diagCondEngSpd_BASE "vehicle condition for diagnosis: engine is stopped";
CM_ SG_ 2566871591 E2EmsgCounterDiagVehState_BASE "The message counter is used to detect situations where the transmitting ECU malfunction repeats the same frame all the time. range 0 to 15 , then 0";
CM_ SG_ 2566871591 E2EmsgChckSumDiagVehState_BASE "The message checksum is used to verify the signal path from the transmitting device to the receiving device. range 0 to 15";
CM_ SG_ 2566871591 highResolutionTotalVehDistance_B "Accumulated distance traveled by the vehicle during its operation.";
CM_ SG_ 2566871591 diagCondGearNeutral_BASE "vehicle condition for diagnosis: gearbox in neutral gear";
CM_ SG_ 2566871591 diagCondParkingBrake_BASE "vehicle condition for diagnosis: parking brake is engaged";
CM_ SG_ 2566871591 diagCondC1_BASE "vehicle condition for diagnosis: UDS C1- condition";
CM_ BO_ 2382338571 "Proprietary CAN-message Data ID for CRC8 AutoSAR Profile 2:  17 195 94 59 1 183 159 146 190 208 123 38 245 194 211 66";
CM_ SG_ 2382338571 EBS3_propMessage_CRC_BASE "The message checksum is used to verify the signal path from the transmitting device to the receiving device.";
CM_ SG_ 2382338571 ABSactive_BASIS "State signal which indicates that the ABS is active. The signal is set when...";
CM_ SG_ 2382338571 BPposition_BASIS "Ratio of brake pedal position to maximum pedal position. Used for electric brake applications. 0% means no braking. Also when there are two brake pedals on the machine the maximum of the two should be transmitted for Brake Pedal Position.";
CM_ SG_ 2382338571 cwsQuality_BASE "Quality signal for combinedWheelSpeed";
CM_ SG_ 2382338571 DTCactive_BASE "The signal indicates the active state of the drag torque control";
CM_ SG_ 2382338571 ABSaxleActive_BASE "Information about the active state of the ABS ventilation valves on the axle(s) and/or the trailer interface";
CM_ SG_ 2382338571 CombinedWheelSpeed_BASE "Combined Wheel Speed";
CM_ SG_ 2382338571 EBS3_propMessage_Cnt_BASE "Counter of end-to-end communication protection. Refer to SPN 3189 (counter) of SAE J1939 standard.";
CM_ SG_ 2600454441 extrnlChrgHVACimmedDisp_BASE "The signal indicates if HVAC preconditioning is selected for immediate charging.";
CM_ SG_ 2600454441 extrnlChrgSelPrcTypDisp_BASE "The signal indicates the selected pricing type for the running/upcoming charging session displayed in the cluster.";
CM_ SG_ 2600454441 actPantoPositionStateDisp_BASE "Actual state of Inverted Pantograph position for display purpose.";
CM_ SG_ 2600454441 extrnlChrgHoldDurImmedDisp_BASE "The signal indicates the duration of the holding period for immediate charging.";
CM_ SG_ 2600454441 extrnlChrgBulkChrgDisp_BASE "The signal indicates if bulk charging is selected.";
CM_ SG_ 2600454441 extrnlChrgBulkSOCdisp_BASE "The signal indicates the bulk SOC.";
CM_ SG_ 2600454441 extrnlChrgHVACstateDisp_BASE "The signal indicates if HVAC precondition is selected.";
CM_ SG_ 2600454441 extrnlChrgTargetSOCdisp_BASE "The signal indicates the target SOC.";
CM_ SG_ 2600454441 extrnlChrgBulkSOC_BASE "Requested bulk SOC of the traction energy storage.";
CM_ SG_ 2600454441 extrnlChrgRenEnrgyPercDisp_BASE "Percentage of renewable energy of the charging session.";
CM_ SG_ 2600454441 extrnlChrgAMSstateDisp_BASE "The signal indicates if AMS precondition is selected.";
CM_ BO_ 2600403757 "CANMSG CVM_45";
CM_ SG_ 2600403757 mean100msDCpowerDS1_BASE "This signal contains the 100 ms mean value of the dc-power consumption (positive: inverter consumes electric power from the HV-system; negative: inverter feeds electric power into the HV-system) of the inverter of the first drive system (DS1).";
CM_ SG_ 2600403757 mean100msDCpowerDS2_BASE "This signal contains the 100 ms mean value of the dc-power consumption (positive: inverter consumes electric power from the HV-system; negative: inverter feeds electric power into the HV-system) of the inverter of the second drive system (DS2).";
CM_ SG_ 2600403757 mean100msPowerTES_BASE "100 ms mean value of the power output of the Traction Energy Storage (TES). Power flowing into the TES has a positive sign, power flowing out of the TES has a negative sign.";
CM_ SG_ 2600403757 actEnergyDischrgDrvTES_BASE "Currently stored energy that can be discharged from the Traction Energy Storage (TES), considering average losses at the discharging of the TES in driving operation.";
CM_ BO_ 2600415783 "RX message of the Vehicle Connectivity Manager (VCM) for eMobility first use E4C";
CM_ SG_ 2600415783 extnlChargingStAct_BASE "Actual state of charging.";
CM_ SG_ 2600415783 extrnlChrgWakeUpReq_BASE "Request of the vehicle control for time based wake-up.";
CM_ SG_ 2600415783 preCondAirReq_BASE "request for the preconditioning of the air management system (AMS)";
CM_ SG_ 2600415783 preCondClimateReq_BASE "request for preconditioning of the heating, ventilation and air conditioning system (HVAC)";
CM_ SG_ 2600415783 ambientAirTemperature_BASIS "Temperature of air surrounding vehicle.";
CM_ SG_ 2600415783 stCombHeat_BASE "Feedback of the current status of the combustion heater of the climate system.";
CM_ SG_ 2600415783 highVoltSysModeAct_BASE "current operating mode of the high voltage system";
CM_ SG_ 2600415783 networkWakeUpStAct_BASE "current operation state of the ECU network";
CM_ SG_ 2600415783 drvSysActv_BASE "The signal describes whether the drive system is ready for operation.";
CM_ SG_ 2600415783 thermalAlertPredctnTES_BASE "condition of the TES (traction energy accumulator) warning of increased temperature";
CM_ SG_ 2600415783 extrnlChrgVehRdy2Drv_BASE "Indicates whether the vehicle is ready for departure from the point of view of external charging.";
CM_ BO_ 2566865813 "Transmit message 2 of the Battery Data Module (BDM). E2E Protection Autosarprofile 2. Data ID: 26 4 157 65 171 1 91 42 143 110 70 208 216 168 71 45";
CM_ SG_ 2566865813 BDM2_CRC_BASE "The message checksum is used to verify the signal path from the transmitting device to the receiving device.";
CM_ SG_ 2566865813 batt24Vlearning_A_BASE "Learning phase not completed for 24V battery set A.";
CM_ SG_ 2566865813 actModelBatt24V_A_BASE "Feedback of the used battery model number for the battery set A at the 24V electrical system.";
CM_ SG_ 2566865813 batt24VcapMax_A_BASE "Maximum capacity. Maximum useable capacity at norm-temperature and nominal current (I20) by full loaded 24V battery set A.";
CM_ SG_ 2566865813 tempActBatt24V_A_BASE "Actual temperature of battery set A at the 24V electrical system.";
CM_ SG_ 2566865813 batt24VcapMaxT_A_BASE "Maximum capacity at current temperature. Maximum useable capacity at current temperatur and nominal current (I20) by full loaded 24V battery set A.";
CM_ SG_ 2566865813 batt24VcapAct_A_BASE "Actual capacity: Charge of battery set A that can be used at nominal current I20 and a nominal temperature of 25°C without previous charge.";
CM_ SG_ 2566865813 batt24VcapActT_A_BASE "Actual capacity temperature-dependent: Capacity of 24V battery set A that can be used when discharging the battery at actual temperature and nominal current (I20).";
CM_ SG_ 2566865813 BDM2_Cnt_BASE "Counter of end-to-end communication protection. Refer to SPN 3189 (counter) of SAE J1939 standard.";
CM_ BO_ 2566865772 "Transmit message 2 of the Battery Data Module (BDM). E2E Protection Autosarprofile 2. Data ID: 248 190 8 14 242 43 193 77 135 68 107 238 20 96 171 25";
CM_ SG_ 2566865772 BDM2_CRC_BASE "The message checksum is used to verify the signal path from the transmitting device to the receiving device.";
CM_ SG_ 2566865772 batt24Vlearning_B_BASE "Learning phase not completed for 24V battery set B.";
CM_ SG_ 2566865772 actModelBatt24V_B_BASE "Feedback of the used battery model number for battery set B at the 24V electrical system.";
CM_ SG_ 2566865772 batt24VcapMax_B_BASE "Maximum capacity. Maximum useable capacity at norm-temperature and nominal current (I20) by full loaded 24V battery set B.";
CM_ SG_ 2566865772 tempActBatt24V_B_BASE "Actual temperature of battery set B at the 24V electrical system.";
CM_ SG_ 2566865772 batt24VcapMaxT_B_BASE "Maximum capacity at current temperature. Maximum useable capacity at current temperatur and nominal current (I20) by full loaded 24V battery set B.";
CM_ SG_ 2566865772 batt24VcapAct_B_BASE "Actual capacity: Charge of battery set B that can be used at nominal current I20 and a nominal temperature of 25°C without previous charge.";
CM_ SG_ 2566865772 batt24VcapActT_B_BASE "Actual capacity temperature-dependent: Capacity of 24V battery set B that can be used when discharging the battery at actual temperature and nominal current (I20).";
CM_ SG_ 2566865772 BDM2_Cnt_BASE "Counter of end-to-end communication protection. Refer to SPN 3189 (counter) of SAE J1939 standard.";
CM_ SG_ 2667525633 driveProgramAppVersion_BASE "version CAN raw value 14: error CAN raw value 15: not available";
CM_ SG_ 2667525633 appMinValSlider1_BASE "App Minimum Value Slider 1";
CM_ SG_ 2667525633 appValSlider1_BASE "App Value Slider 1";
CM_ SG_ 2667525633 appMaxValSlider2_BASE "App Maximum Value Slider 2";
CM_ SG_ 2667525633 appMinValSlider2_BASE "App Minimum Value Slider 2";
CM_ SG_ 2667525633 appValSlider2_BASE "App Value Slider 2";
CM_ SG_ 2667525633 appEnaSwitch3_BASE "App Enable Switch 3";
CM_ SG_ 2667525633 appValSwitch3_BASE "App Value Switch 3";
CM_ SG_ 2667525633 appEnaSwitch4_BASE "App Enable Switch 4";
CM_ SG_ 2667525633 appValSwitch4_BASE "App Value Switch 4";
CM_ SG_ 2667525633 appEnaSwitch1_BASE "App Enable Switch 1";
CM_ SG_ 2667525633 appEnaSwitch5_BASE "App Enable Switch 5";
CM_ SG_ 2667525633 appValSwitch5_BASE "App Value Switch 5";
CM_ SG_ 2667525633 appMaxValSlider3_BASE "App Maximum Value Slider 3";
CM_ SG_ 2667525633 appMinValSlider3_BASE "App Minimum Value Slider 3";
CM_ SG_ 2667525633 appValSlider3_BASE "App Value Slider 3";
CM_ SG_ 2667525633 appEnaSwitch2_BASE "App Enable Switch 2";
CM_ SG_ 2667525633 appValSwitch2_BASE "App Value Switch 2";
CM_ SG_ 2667525633 appValSwitch1_BASE "App Value Switch 1";
CM_ SG_ 2667525633 appMaxValSlider1_BASE "App Maximum Value Slider 1";
CM_ BO_ 2600403747 "CANMSG CVM_35";
CM_ SG_ 2600403747 estAvgHVpower_ePTO_BASE "The estimated average HV-power consumption of the Air Management System (AMS).";
CM_ SG_ 2600403747 estAvgHVpowerHVAC_BASE "The estimated average HV-power consumption of the Air Management System (AMS).";
CM_ SG_ 2600403747 sMeanDCpowerDS1_BASE "This signal contains the 1 s mean value of the dc-power consumption (positive: inverter consumes electric power from the HV-system; negative: inverter feeds electric power into the HV-system) of the inverter of the first drive system (DS1).";
CM_ SG_ 2600403747 sMeanDCpowerDS2_BASE "This signal contains the 1 s mean value of the dc-power consumption (positive: inverter consumes electric power from the HV-system; negative: inverter feeds electric power into the HV-system) of the inverter of the second drive system (DS2).";
CM_ BO_ 2600403756 "CANMSG CVM_44";
CM_ SG_ 2600403756 estAvgHVpowerCHS_BASE "The estimated average HV-power consumption of the Air Management System (AMS).";
CM_ SG_ 2600403756 estAvgHVpowerAMS_BASE "The estimated average HV-power consumption of the Air Management System (AMS).";
CM_ SG_ 2600403756 energyChargedEVSE_BASE "Charged energy during the current charging session, measured by the EVSE (value of ChargeEnergyReadingWh reported in current loop).";
CM_ SG_ 2600403756 actEnergyChrgTES_BASE "Currently storable energy that can be charged into the Traction Energy Storage (TES), considering average losses at the charging of the vehicle by the external charging system.";
CM_ BO_ 2600403781 "CANMSG CVM_63";
CM_ SG_ 2566807240 tyreWheelIdentification_T1_TO_TR "It shall indicate the identification number of the tyre or wheel. The identification number shall specify the tyre or wheel position on each axle (bit 1 to bit 4) and the number of axles starting from the front of the respective towed vehicle (bit 5 to bi";
CM_ SG_ 2566807240 tireAirLeakageRate_T1_TO_TRUCK "This signal indicates the current air leakage (pressure loss) of a tyre. This signal is used in conjunction with the tyre/wheel identification.";
CM_ SG_ 2566807240 tirePressureThresholdDetection_T "This signal indicates the pressure level of one specific tyre. This signal is used in conjunctionwith the tyre/wheel identification.";
CM_ SG_ 2566807240 tireModulePowerSupply_T1_TO_TRUC "This signal indicates the current status of the power supply of the tyre module. It shall indicate whether it is sufficient to achieve the specified performance of the module. This parameter is used in conjunction with the tyre/wheel identification.";
CM_ SG_ 2566807240 identificationDataIndex_BASE "This signal shall be used as an index to an array of identification data as defined by the signal identification data conten and shall not be used without that context.";
CM_ SG_ 2566807240 identificationDataContent_BASE "This signal shall be interpreted as an array of identification data that is indexed by the signal ¿identification data index¿.";
CM_ SG_ 2566807240 tireTemperature_T1_TO_TRUCK "This signal indicates the current temperature of a tyre. This signal is used in conjunction with the tyre/wheel identification.";
BA_DEF_ SG_  "SigType" ENUM  "DEFAULT","RANGE","RANGESIGNED","ASCII","DISCRETE","CONTROL","REFERENCEPGN","DTC","STRINGDELIMITER","STRINGLENGTH","STRINGLENGTHCONTROL","vector_leerstring";
BA_DEF_ SG_  "GenSigSendType" ENUM  "Cyclic","OnWrite","reserved","OnChange","reserved","reserved","reserved","NoSigSendType";
BA_DEF_ BO_  "VFrameFormat" ENUM  "CAN Standard","CAN Extended","reserved","J1939PG","reserved","reserved","reserved","reserved","reserved","reserved","reserved","reserved","reserved","reserved","StandardCAN_FD","ExtendedCAN_FD","vector_leerstring";
BA_DEF_ BO_  "GenMsgSendType" ENUM  "cyclic","reserved","cyclicIfActive","reserved","reserved","reserved","reserved","reserved","noMsgSendType","vector_leerstring";
BA_DEF_ BO_  "GenMsgCycleTime" INT 0 3600000;
BA_DEF_ BO_  "GenMsgStartDelayTime" INT 0 0;
BA_DEF_ BO_  "GenMsgILSupport" ENUM  "No","Yes","vector_leerstring";
BA_DEF_ SG_  "SystemSignalLongSymbol" STRING ;
BA_DEF_ BO_  "SystemMessageLongSymbol" STRING ;
BA_DEF_DEF_  "SigType" "DEFAULT";
BA_DEF_DEF_  "VFrameFormat" "CAN Extended";
BA_DEF_DEF_  "GenMsgSendType" "noMsgSendType";
BA_DEF_DEF_  "GenMsgCycleTime" 1000;
BA_DEF_DEF_  "GenMsgStartDelayTime" 0;
BA_DEF_DEF_  "GenMsgILSupport" "Yes";
BA_DEF_DEF_  "SystemSignalLongSymbol" "";
BA_DEF_DEF_  "GenSigSendType" "NoSigSendType";

BA_ "GenMsgSendType" BO_ 2566845952 0;
BA_ "GenMsgCycleTime" BO_ 2566845952 500;
BA_ "GenMsgStartDelayTime" BO_ 2566845952 20;

BA_ "GenMsgSendType" BO_ 2365289610 0;
BA_ "GenMsgCycleTime" BO_ 2365289610 10;

BA_ "GenMsgILSupport" BO_ 2566898183 0;
BA_ "GenMsgSendType" BO_ 2566898183 0;
BA_ "GenMsgCycleTime" BO_ 2566898183 100;

BA_ "GenMsgILSupport" BO_ 2600460823 0;
BA_ "VFrameFormat" BO_ 2600460823 3;

BA_ "GenMsgSendType" BO_ 2566891559 0;
BA_ "GenMsgCycleTime" BO_ 2566891559 100;

BA_ "GenMsgILSupport" BO_ 2566897703 0;
BA_ "GenMsgSendType" BO_ 2566897703 0;
BA_ "GenMsgCycleTime" BO_ 2566897703 100;

BA_ "GenMsgILSupport" BO_ 2600407315 0;
BA_ "GenMsgSendType" BO_ 2600407315 0;
BA_ "VFrameFormat" BO_ 2600407315 3;

BA_ "GenMsgILSupport" BO_ 2600407314 0;
BA_ "GenMsgSendType" BO_ 2600407314 0;
BA_ "VFrameFormat" BO_ 2600407314 3;

BA_ "GenMsgILSupport" BO_ 2600407316 0;
BA_ "GenMsgSendType" BO_ 2600407316 0;
BA_ "VFrameFormat" BO_ 2600407316 3;

BA_ "GenMsgILSupport" BO_ 2600407310 0;
BA_ "GenMsgSendType" BO_ 2600407310 0;
BA_ "VFrameFormat" BO_ 2600407310 3;

BA_ "GenMsgILSupport" BO_ 2600407311 0;
BA_ "GenMsgSendType" BO_ 2600407311 0;
BA_ "VFrameFormat" BO_ 2600407311 3;

BA_ "GenMsgILSupport" BO_ 2600407312 0;
BA_ "GenMsgSendType" BO_ 2600407312 0;
BA_ "VFrameFormat" BO_ 2600407312 3;

BA_ "GenMsgILSupport" BO_ 2600407313 0;
BA_ "GenMsgSendType" BO_ 2600407313 0;
BA_ "VFrameFormat" BO_ 2600407313 3;

BA_ "GenMsgILSupport" BO_ 2565879335 0;
BA_ "GenMsgSendType" BO_ 2565879335 0;
BA_ "GenMsgCycleTime" BO_ 2565879335 100;

BA_ "GenMsgILSupport" BO_ 2600407298 0;
BA_ "GenMsgSendType" BO_ 2600407298 0;
BA_ "VFrameFormat" BO_ 2600407298 3;

BA_ "GenMsgILSupport" BO_ 2561553175 0;
BA_ "GenMsgCycleTime" BO_ 2561553175 0;
BA_ "SystemMessageLongSymbol" BO_ 2561553175 "tirePressureReferenceSetting_BASIS";
BA_ "GenMsgILSupport" BO_ 2566764851 0;
BA_ "GenMsgCycleTime" BO_ 2566764851 0;
BA_ "SystemMessageLongSymbol" BO_ 2566764851 "tirePressureReferenceInformation_BASIS";
BA_ "GenMsgILSupport" BO_ 2566876977 0;
BA_ "GenMsgSendType" BO_ 2566876977 0;

BA_ "GenMsgSendType" BO_ 2566845491 0;
BA_ "GenMsgCycleTime" BO_ 2566845491 500;

BA_ "GenMsgILSupport" BO_ 2566567285 0;
BA_ "GenMsgSendType" BO_ 2566567285 0;

BA_ "GenMsgILSupport" BO_ 2600407302 0;
BA_ "GenMsgSendType" BO_ 2600407302 0;
BA_ "VFrameFormat" BO_ 2600407302 3;

BA_ "GenMsgSendType" BO_ 2382347251 0;
BA_ "VFrameFormat" BO_ 2382347251 3;

BA_ "GenMsgILSupport" BO_ 2600406039 0;
BA_ "GenMsgCycleTime" BO_ 2600406039 0;

BA_ "GenMsgILSupport" BO_ 2600454695 0;
BA_ "GenMsgSendType" BO_ 2600454695 0;
BA_ "GenMsgCycleTime" BO_ 2600454695 500;
BA_ "VFrameFormat" BO_ 2600454695 3;

BA_ "GenMsgSendType" BO_ 2566759463 0;
BA_ "GenMsgCycleTime" BO_ 2566759463 100;

BA_ "GenMsgILSupport" BO_ 2583651111 0;
BA_ "VFrameFormat" BO_ 2583651111 3;

BA_ "GenMsgILSupport" BO_ 2600403755 0;
BA_ "GenMsgCycleTime" BO_ 2600403755 0;

BA_ "GenMsgILSupport" BO_ 2382346791 0;
BA_ "GenMsgSendType" BO_ 2382346791 0;
BA_ "VFrameFormat" BO_ 2382346791 3;

BA_ "GenMsgILSupport" BO_ 2600454446 0;

BA_ "GenMsgILSupport" BO_ 2600454440 0;

BA_ "GenMsgSendType" BO_ 2600421701 0;

BA_ "GenMsgSendType" BO_ 2600425497 0;
BA_ "GenMsgCycleTime" BO_ 2600425497 10000;

BA_ "GenMsgSendType" BO_ 2600424473 0;

BA_ "GenMsgSendType" BO_ 2600421445 0;

BA_ "GenMsgSendType" BO_ 2600425241 0;
BA_ "GenMsgCycleTime" BO_ 2600425241 10000;

BA_ "GenMsgSendType" BO_ 2583675635 0;
BA_ "VFrameFormat" BO_ 2583675635 3;

BA_ "GenMsgSendType" BO_ 2583675891 0;
BA_ "VFrameFormat" BO_ 2583675891 3;

BA_ "GenMsgSendType" BO_ 2583676147 0;
BA_ "VFrameFormat" BO_ 2583676147 3;

BA_ "GenMsgILSupport" BO_ 2600403762 0;

BA_ "GenMsgILSupport" BO_ 2600403763 0;

BA_ "GenMsgILSupport" BO_ 2583677942 0;
BA_ "GenMsgSendType" BO_ 2583677942 0;
BA_ "GenMsgCycleTime" BO_ 2583677942 100;

BA_ "GenMsgILSupport" BO_ 2583677881 0;
BA_ "GenMsgSendType" BO_ 2583677881 0;
BA_ "GenMsgCycleTime" BO_ 2583677881 100;

BA_ "GenMsgILSupport" BO_ 2583677882 0;
BA_ "GenMsgSendType" BO_ 2583677882 0;
BA_ "GenMsgCycleTime" BO_ 2583677882 100;

BA_ "GenMsgILSupport" BO_ 2583677883 0;
BA_ "GenMsgSendType" BO_ 2583677883 0;
BA_ "GenMsgCycleTime" BO_ 2583677883 100;

BA_ "GenMsgILSupport" BO_ 2583677884 0;
BA_ "GenMsgSendType" BO_ 2583677884 0;
BA_ "GenMsgCycleTime" BO_ 2583677884 100;

BA_ "GenMsgILSupport" BO_ 2583677886 0;
BA_ "GenMsgSendType" BO_ 2583677886 0;
BA_ "GenMsgCycleTime" BO_ 2583677886 100;

BA_ "GenMsgILSupport" BO_ 2600423961 0;

BA_ "GenMsgILSupport" BO_ 2583677894 0;
BA_ "GenMsgSendType" BO_ 2583677894 0;
BA_ "GenMsgCycleTime" BO_ 2583677894 100;

BA_ "GenMsgILSupport" BO_ 2583677895 0;
BA_ "GenMsgSendType" BO_ 2583677895 0;
BA_ "GenMsgCycleTime" BO_ 2583677895 100;

BA_ "GenMsgILSupport" BO_ 2583677902 0;
BA_ "GenMsgSendType" BO_ 2583677902 0;
BA_ "GenMsgCycleTime" BO_ 2583677902 100;

BA_ "GenMsgILSupport" BO_ 2583677903 0;
BA_ "GenMsgSendType" BO_ 2583677903 0;
BA_ "GenMsgCycleTime" BO_ 2583677903 100;

BA_ "GenMsgILSupport" BO_ 2583677900 0;
BA_ "GenMsgSendType" BO_ 2583677900 0;
BA_ "GenMsgCycleTime" BO_ 2583677900 100;

BA_ "GenMsgILSupport" BO_ 2583677939 0;
BA_ "GenMsgSendType" BO_ 2583677939 0;
BA_ "GenMsgCycleTime" BO_ 2583677939 100;

BA_ "GenMsgILSupport" BO_ 2600454404 0;
BA_ "GenMsgCycleTime" BO_ 2600454404 0;

BA_ "GenMsgILSupport" BO_ 2399077149 0;
BA_ "GenMsgSendType" BO_ 2399077149 0;
BA_ "GenMsgCycleTime" BO_ 2399077149 20;

BA_ "GenMsgSendType" BO_ 2566871591 0;
BA_ "GenMsgCycleTime" BO_ 2566871591 100;

BA_ "GenMsgSendType" BO_ 2382338571 0;
BA_ "GenMsgCycleTime" BO_ 2382338571 10;
BA_ "VFrameFormat" BO_ 2382338571 3;

BA_ "GenMsgILSupport" BO_ 2600454441 0;

BA_ "GenMsgILSupport" BO_ 2600403757 0;
BA_ "GenMsgSendType" BO_ 2600403757 0;
BA_ "GenMsgCycleTime" BO_ 2600403757 100;

BA_ "GenMsgILSupport" BO_ 2600415783 0;
BA_ "GenMsgSendType" BO_ 2600415783 0;
BA_ "GenMsgCycleTime" BO_ 2600415783 100;
BA_ "VFrameFormat" BO_ 2600415783 3;

BA_ "GenMsgILSupport" BO_ 2566865813 0;
BA_ "GenMsgSendType" BO_ 2566865813 0;

BA_ "GenMsgILSupport" BO_ 2566865772 0;
BA_ "GenMsgSendType" BO_ 2566865772 0;

BA_ "GenMsgILSupport" BO_ 2667525633 0;
BA_ "GenMsgCycleTime" BO_ 2667525633 5000;

BA_ "GenMsgILSupport" BO_ 2600403747 0;
BA_ "GenMsgSendType" BO_ 2600403747 0;

BA_ "GenMsgILSupport" BO_ 2600403756 0;

BA_ "GenMsgILSupport" BO_ 2600403781 0;
BA_ "GenMsgSendType" BO_ 2600403781 0;
BA_ "GenMsgCycleTime" BO_ 2600403781 100;

BA_ "GenMsgSendType" BO_ 2566807240 0;
BA_ "SystemSignalLongSymbol" SG_ 2566845952 engineAirFilter1diffPressure_BAS "engineAirFilter1diffPressure_BASIS";
BA_ "SystemSignalLongSymbol" SG_ 2566845952 engineExhaustGasTemperature_BASI "engineExhaustGasTemperature_BASIS";
BA_ "SystemSignalLongSymbol" SG_ 2566845952 engineTurbochargerBoostPressure_ "engineTurbochargerBoostPressure_BASIS";
BA_ "SystemSignalLongSymbol" SG_ 2561553175 referenceTirePressureSetting_BAS "referenceTirePressureSetting_BASIS";
BA_ "SystemSignalLongSymbol" SG_ 2566845491 tirePressureThresholdDetection_B "tirePressureThresholdDetection_BASIS";
BA_ "SystemSignalLongSymbol" SG_ 2600407302 customerInterface13placeholder_B "customerInterface13placeholder_BASE";
BA_ "SystemSignalLongSymbol" SG_ 2566759463 engagemCnstnt_PTOengAccesDrive1_ "engagemCnstnt_PTOengAccesDrive1_BASE";
BA_ "SystemSignalLongSymbol" SG_ 2566759463 engagemStatus_transInpShaftPTO2_ "engagemStatus_transInpShaftPTO2_BASE";
BA_ "SystemSignalLongSymbol" SG_ 2566759463 engagemStatus_transInpShaftPTO1_ "engagemStatus_transInpShaftPTO1_BASE";
BA_ "SystemSignalLongSymbol" SG_ 2566759463 engagemStatus_PTOengineFlywheel_ "engagemStatus_PTOengineFlywheel_BASE";
BA_ "SystemSignalLongSymbol" SG_ 2399077149 parkBrakeActuatorFullyActivated_ "parkBrakeActuatorFullyActivated_BASE";
BA_ "SystemSignalLongSymbol" SG_ 2566871591 highResolutionTotalVehDistance_B "highResolutionTotalVehDistance_BASIS";
BA_ "SystemSignalLongSymbol" SG_ 2566807240 tyreWheelIdentification_T1_TO_TR "tyreWheelIdentification_T1_TO_TRUCK";
BA_ "SystemSignalLongSymbol" SG_ 2566807240 tirePressureThresholdDetection_T "tirePressureThresholdDetection_T1_TO_TRUCK";
BA_ "SystemSignalLongSymbol" SG_ 2566807240 tireModulePowerSupply_T1_TO_TRUC "tireModulePowerSupply_T1_TO_TRUCK";
BA_ "GenSigSendType" SG_ 2566845952 engineAirFilter1diffPressure_BAS 0;
BA_ "GenSigSendType" SG_ 2566845952 engineExhaustGasTemperature_BASI 0;
BA_ "GenSigSendType" SG_ 2566845952 engineTurbochargerBoostPressure_ 0;
BA_ "GenSigSendType" SG_ 2365289610 msgCRC8saeJ1939_BASE 0;
BA_ "GenSigSendType" SG_ 2365289610 actMotorTrqPrcnt_BASE 0;
BA_ "GenSigSendType" SG_ 2365289610 actMotorSpeedPrcnt_BASE 0;
BA_ "GenSigSendType" SG_ 2365289610 msgCNTsaeJ1939_BASE 0;
BA_ "GenSigSendType" SG_ 2566898183 BB_PlaceHolder_BASE 0;
BA_ "GenSigSendType" SG_ 2600460823 rmtTstrInstallScreenInfo_VAR1 0;
BA_ "GenSigSendType" SG_ 2600460823 rmtTstrDrivRestartConfirm_BASE 0;
BA_ "GenSigSendType" SG_ 2600460823 tsiModeReq_BASE 0;
BA_ "GenSigSendType" SG_ 2600460823 tsiTolSettingReq_BASE 0;
BA_ "GenSigSendType" SG_ 2600460823 rmtTstrDrivEndConfirm_BASE 0;
BA_ "GenSigSendType" SG_ 2600460823 tsiEnableSpdWrnReq_BASE 0;
BA_ "GenSigSendType" SG_ 2600460823 tsiChangeInfoSettingReq_BASE 0;
BA_ "GenSigSendType" SG_ 2600460823 EBAactivationReqVRU_BASE 0;
BA_ "GenSigSendType" SG_ 2600460823 EBAactivationReq_BASE 0;
BA_ "GenSigSendType" SG_ 2600460823 CCselectedModeReq_BASE 0;
BA_ "GenSigSendType" SG_ 2600460823 reqMaxSpdPCCA_BASE 0;
BA_ "GenSigSendType" SG_ 2600460823 DIGenableDistWrnReq_BASE 0;
BA_ "GenSigSendType" SG_ 2600460823 updtMstrDrvrNotifReq_BASE 0;
BA_ "GenSigSendType" SG_ 2600460823 updtMstrDrvrAuth_BASE 0;
BA_ "GenSigSendType" SG_ 2600460823 rmtTstrDrivUpdateConfirm_BASE 0;
BA_ "GenSigSendType" SG_ 2566891559 bckgrndLghtAutoRevRqSave_BASE 0;
BA_ "GenSigSendType" SG_ 2566891559 ISCcondClutchOpen_BASE 0;
BA_ "GenSigSendType" SG_ 2566891559 ISCcondEngWarming_BASE 0;
BA_ "GenSigSendType" SG_ 2566891559 ISCcondBrakeNotPressed_BASE 0;
BA_ "GenSigSendType" SG_ 2566891559 ISCcondGearEngaged_BASE 0;
BA_ "GenSigSendType" SG_ 2566891559 ISCcondNeutralEngaged_BASE 0;
BA_ "GenSigSendType" SG_ 2566891559 ISCcondParkingBrakeActv_BASE 0;
BA_ "GenSigSendType" SG_ 2566891559 ISCcondParkingBrakeNotActv_BASE 0;
BA_ "GenSigSendType" SG_ 2566891559 ISCcondVehSpd_BASE 0;
BA_ "GenSigSendType" SG_ 2566891559 ZDRact_BASE 0;
BA_ "GenSigSendType" SG_ 2566891559 brightFunctionLight_BASE 0;
BA_ "GenSigSendType" SG_ 2566891559 ISCcondBrakePressed_BASE 0;
BA_ "GenSigSendType" SG_ 2566891559 dispInteriorLightAutoReq_BASE 0;
BA_ "GenSigSendType" SG_ 2566891559 dispIntLghtAutoCLreq_BASE 0;
BA_ "GenSigSendType" SG_ 2566891559 centrLubGreaseLvlLow_BASE 0;
BA_ "GenSigSendType" SG_ 2566891559 vehStandStill_BASE 0;
BA_ "GenSigSendType" SG_ 2566891559 centralUnlockDoorSelect_BASE 0;
BA_ "GenSigSendType" SG_ 2566891559 dispEntranceLightAutoReq_BASE 0;
BA_ "GenSigSendType" SG_ 2566891559 ureaLvlWarningDisp_BASE 0;
BA_ "GenSigSendType" SG_ 2566891559 centralLockSpeedSelect_BASE 0;
BA_ "GenSigSendType" SG_ 2566891559 auxStatMC7cntE2E_BASE 0;
BA_ "GenSigSendType" SG_ 2566891559 ISCcondClutchClosed_BASE 0;
BA_ "GenSigSendType" SG_ 2566891559 auxStatMC7chkE2E_BASE 0;
BA_ "GenSigSendType" SG_ 2566891559 bckgrndLghtBrghtReqSave_BASE 0;
BA_ "GenSigSendType" SG_ 2566897703 ASP2_CRC8_BASE 0;
BA_ "GenSigSendType" SG_ 2566897703 genericBobuOut101_BASE 0;
BA_ "GenSigSendType" SG_ 2566897703 genericBobuOut102_BASE 0;
BA_ "GenSigSendType" SG_ 2566897703 genericBobuOut103_BASE 0;
BA_ "GenSigSendType" SG_ 2566897703 genericBobuOut104_BASE 0;
BA_ "GenSigSendType" SG_ 2566897703 genericBobuOut105_BASE 0;
BA_ "GenSigSendType" SG_ 2566897703 genericBobuOut106_BASE 0;
BA_ "GenSigSendType" SG_ 2566897703 genericBobuOut107_BASE 0;
BA_ "GenSigSendType" SG_ 2566897703 genericBobuOut108_BASE 0;
BA_ "GenSigSendType" SG_ 2566897703 genericBobuOut109_BASE 0;
BA_ "GenSigSendType" SG_ 2566897703 genericBobuOut110_BASE 0;
BA_ "GenSigSendType" SG_ 2566897703 genericBobuOut201_BASE 0;
BA_ "GenSigSendType" SG_ 2566897703 ASP2__cnt_BASE 0;
BA_ "GenSigSendType" SG_ 2600407315 placeholderCuIntf26_BASE 0;
BA_ "GenSigSendType" SG_ 2600407314 placeholderCuIntf25_BASE 0;
BA_ "GenSigSendType" SG_ 2600407316 placeholderCuIntf27_BASE 0;
BA_ "GenSigSendType" SG_ 2600407310 placeholderCuIntf21_BASE 0;
BA_ "GenSigSendType" SG_ 2600407311 placeholderCuIntf22_BASE 0;
BA_ "GenSigSendType" SG_ 2600407312 placeholderCuIntf23_BASE 0;
BA_ "GenSigSendType" SG_ 2600407313 placeholderCuIntf24_BASE 0;
BA_ "GenSigSendType" SG_ 2565879335 HVESSDischrgPwLimDueSOC_BASE 0;
BA_ "GenSigSendType" SG_ 2600407298 actualMotorCurrentSumDIV_BASE 0;
BA_ "GenSigSendType" SG_ 2600407298 remainingTravelTime_BASE 0;
BA_ "GenSigSendType" SG_ 2600407298 extrnlChrgTotalEnergyChrgd_BASE 0;
BA_ "GenSigSendType" SG_ 2561553175 axleLocation_TPRS 3;
BA_ "GenSigSendType" SG_ 2561553175 referenceTirePressureSetting_BAS 3;
BA_ "GenSigSendType" SG_ 2566764851 axleLocation_TPRI 1;
BA_ "GenSigSendType" SG_ 2566764851 referenceTirePressure_BASIS 1;
BA_ "GenSigSendType" SG_ 2566876977 dispFireDtctnWrning1_BASE 0;
BA_ "GenSigSendType" SG_ 2566876977 dispFireDtctnWrning2_BASE 0;
BA_ "GenSigSendType" SG_ 2566876977 dispFireDtctnWrningFail2_BASE 0;
BA_ "GenSigSendType" SG_ 2566876977 dispFireDtctnWrningFail1_BASE 0;
BA_ "GenSigSendType" SG_ 2566876977 dispFireDtctnWrningFailure_BASE 0;
BA_ "GenSigSendType" SG_ 2566876977 dispFireDtctnWrning_BASE 0;
BA_ "GenSigSendType" SG_ 2566876977 auxHeaterFuelConsumption_BASE 0;
BA_ "GenSigSendType" SG_ 2566845491 axleLocation_BASIS 0;
BA_ "GenSigSendType" SG_ 2566845491 tireTemperature_BASIS 0;
BA_ "GenSigSendType" SG_ 2566845491 tirePressureThresholdDetection_B 0;
BA_ "GenSigSendType" SG_ 2566845491 tirePressure_BASIS 0;
BA_ "GenSigSendType" SG_ 2566567285 UmaxChrgEVSE_HR_BASE 0;
BA_ "GenSigSendType" SG_ 2566567285 ImaxChrgEVSE_HR_BASE 0;
BA_ "GenSigSendType" SG_ 2566567285 PmaxChrgEVSE_HR_BASE 0;
BA_ "GenSigSendType" SG_ 2600407302 customerInterface13placeholder_B 0;
BA_ "GenSigSendType" SG_ 2382347251 BMC01MsgCrc_BASE 0;
BA_ "GenSigSendType" SG_ 2382347251 BattSysState_BASE 0;
BA_ "GenSigSendType" SG_ 2382347251 BattSysCurr_BASE 0;
BA_ "GenSigSendType" SG_ 2382347251 BattSysVltg_BASE 0;
BA_ "GenSigSendType" SG_ 2382347251 BattSysEvacuationAlarm_BASE 0;
BA_ "GenSigSendType" SG_ 2382347251 BattSysCritOtWarn_BASE 0;
BA_ "GenSigSendType" SG_ 2382347251 BattSysPickUpIntention_BASE 0;
BA_ "GenSigSendType" SG_ 2382347251 battSysIsoMeasOkToCharge_BASE 0;
BA_ "GenSigSendType" SG_ 2382347251 BMC01MsgCnt_BASE 0;
BA_ "GenSigSendType" SG_ 2600406039 uiLCWactivationReq_BASE 3;
BA_ "GenSigSendType" SG_ 2600406039 uiTCWactivationReq_BASE 3;
BA_ "GenSigSendType" SG_ 2600454695 dispBatt24VchrgLvl_BASE 0;
BA_ "GenSigSendType" SG_ 2600454695 dispBatt24VpwrSaveInfo_BASE 0;
BA_ "GenSigSendType" SG_ 2600454695 dispBatt24VpwrSaveWarning_BASE 0;
BA_ "GenSigSendType" SG_ 2600454695 dispBattCurrentFltrd_BASE 0;
BA_ "GenSigSendType" SG_ 2600454695 dispBatt24VCheck_BASE 0;
BA_ "GenSigSendType" SG_ 2600454695 dispBatt24VDischrgMnts_BASE 0;
BA_ "GenSigSendType" SG_ 2566759463 engagemCnstnt_PTOengAccesDrive1_ 0;
BA_ "GenSigSendType" SG_ 2566759463 engagemStatus_transInpShaftPTO2_ 0;
BA_ "GenSigSendType" SG_ 2566759463 engagemStatus_transInpShaftPTO1_ 0;
BA_ "GenSigSendType" SG_ 2566759463 engagemStatus_PTOengineFlywheel_ 0;
BA_ "GenSigSendType" SG_ 2566759463 atLeastOnePTOengaged_BASE 0;
BA_ "GenSigSendType" SG_ 2566759463 PTODEmsgCounter_BASE 0;
BA_ "GenSigSendType" SG_ 2566759463 PTODEchkSum_BASE 0;
BA_ "GenSigSendType" SG_ 2583651111 vehProfileNormalWeight_BASE 0;
BA_ "GenSigSendType" SG_ 2583651111 vehProfileBKClass_BASE 0;
BA_ "GenSigSendType" SG_ 2583651111 vehProfileGrossWeight_BASE 0;
BA_ "GenSigSendType" SG_ 2583651111 vehProfileMaxSpd_BASE 0;
BA_ "GenSigSendType" SG_ 2583651111 vehProfileHazardGoods_BASE 0;
BA_ "GenSigSendType" SG_ 2583651111 vehProfileVehicleType_BASE 0;
BA_ "GenSigSendType" SG_ 2583651111 vehProfileNmbrOfTrailer_BASE 0;
BA_ "GenSigSendType" SG_ 2600403755 dispRelFricBrkPow_BASE 3;
BA_ "GenSigSendType" SG_ 2600403755 dispFuelVolume_BASE 3;
BA_ "GenSigSendType" SG_ 2600403755 fuelingIndicationDiesel_BASE 3;
BA_ "GenSigSendType" SG_ 2600403755 fuelTankSrvllncStatus_BASE 3;
BA_ "GenSigSendType" SG_ 2600403755 fuelFillingHeight_BASE 3;
BA_ "GenSigSendType" SG_ 2382346791 VEH01MsgCrc_BASE 0;
BA_ "GenSigSendType" SG_ 2382346791 BattSysModeReq_BASE 0;
BA_ "GenSigSendType" SG_ 2382346791 BattSysPickUpAllowed_BASE 0;
BA_ "GenSigSendType" SG_ 2382346791 VEH01MsgCnt_BASE 0;
BA_ "GenSigSendType" SG_ 2600454446 tmrMngmntTimerIndexDisp_BASE 0;
BA_ "GenSigSendType" SG_ 2600454446 dStmrMngmntDaysDisp_BASE 0;
BA_ "GenSigSendType" SG_ 2600454446 dStmrMngmntTrgtTimeDisp_BASE 0;
BA_ "GenSigSendType" SG_ 2600454446 dStmrMngmntHoldDurDisp_BASE 0;
BA_ "GenSigSendType" SG_ 2600454446 dStmrMngmntTmrSettgsDisp_BASE 0;
BA_ "GenSigSendType" SG_ 2600454440 extrnlChrgPrcTypStateDisp_BASE 0;
BA_ "GenSigSendType" SG_ 2600454440 extrnlChrgCurrencyDisp_BASE 0;
BA_ "GenSigSendType" SG_ 2600454440 extrnlChrgParkingCostsDisp_BASE 0;
BA_ "GenSigSendType" SG_ 2600454440 extrnlChrgChargCostsDisp_BASE 0;
BA_ "GenSigSendType" SG_ 2600454440 extrnlChrgC02emissionDisp_BASE 0;
BA_ "GenSigSendType" SG_ 2600454440 opModeVoKoESTC_BASE 0;
BA_ "GenSigSendType" SG_ 2600421701 prkHeatOpHrs_BASE 0;
BA_ "GenSigSendType" SG_ 2600421701 prkHeatInWtrTemp_BASE 0;
BA_ "GenSigSendType" SG_ 2600421701 prkHeatOutWtrTemp_BASE 0;
BA_ "GenSigSendType" SG_ 2600421701 parkHeatAct_BASE 0;
BA_ "GenSigSendType" SG_ 2600421701 prkHtrStateADR_BASE 0;
BA_ "GenSigSendType" SG_ 2600421701 stateWtrPmpPrkHtr_BASE 0;
BA_ "GenSigSendType" SG_ 2600421701 prkHtrErrAct_BASE 0;
BA_ "GenSigSendType" SG_ 2600425497 nmbStrtCmprssr_BASE 0;
BA_ "GenSigSendType" SG_ 2600425497 totOprtnHoursCmprssr_BASE 0;
BA_ "GenSigSendType" SG_ 2600424473 elecManButPrsHVAC_BASE 0;
BA_ "GenSigSendType" SG_ 2600424473 actStandOp_BASE 0;
BA_ "GenSigSendType" SG_ 2600424473 opModeHVAC_BASE 0;
BA_ "GenSigSendType" SG_ 2600424473 prsCoolantAc_BASE 0;
BA_ "GenSigSendType" SG_ 2600424473 errActPrkHtr_BASE 0;
BA_ "GenSigSendType" SG_ 2600424473 heatingModeActiveHVAC_BASE 0;
BA_ "GenSigSendType" SG_ 2600424473 lvlCabVentFan_BASE 0;
BA_ "GenSigSendType" SG_ 2600421445 stateWtrVlvPrkHtr_BASE 0;
BA_ "GenSigSendType" SG_ 2600421445 prkHtrActFuelCon_BASE 0;
BA_ "GenSigSendType" SG_ 2600421445 prkHtrSumFuelCon_BASE 0;
BA_ "GenSigSendType" SG_ 2600421445 actPwrParkHeater_BASE 0;
BA_ "GenSigSendType" SG_ 2600425241 nmbStrtElCmprssr_BASE 0;
BA_ "GenSigSendType" SG_ 2600425241 totOprtnHoursElCmprssr_BASE 0;
BA_ "GenSigSendType" SG_ 2583675635 battPack1TempSpreadMax_BASE 0;
BA_ "GenSigSendType" SG_ 2583675635 battPack2TempSpreadMax_BASE 0;
BA_ "GenSigSendType" SG_ 2583675635 battPack3TempSpreadMax_BASE 0;
BA_ "GenSigSendType" SG_ 2583675635 battPack4TempSpreadMax_BASE 0;
BA_ "GenSigSendType" SG_ 2583675635 battPack5TempSpreadMax_BASE 0;
BA_ "GenSigSendType" SG_ 2583675891 battPack6TempSpreadMax_BASE 0;
BA_ "GenSigSendType" SG_ 2583675891 battPack7TempSpreadMax_BASE 0;
BA_ "GenSigSendType" SG_ 2583675891 battPackLast1TempSpreadMax_BASE 0;
BA_ "GenSigSendType" SG_ 2583675891 battPack9TempSpreadMax_BASE 0;
BA_ "GenSigSendType" SG_ 2583675891 battPack10TempSpreadMax_BASE 0;
BA_ "GenSigSendType" SG_ 2583676147 battPack11TempSpreadMax_BASE 0;
BA_ "GenSigSendType" SG_ 2583676147 battPack12TempSpreadMax_BASE 0;
BA_ "GenSigSendType" SG_ 2583676147 battPack13TempSpreadMax_BASE 0;
BA_ "GenSigSendType" SG_ 2583676147 battPack14TempSpreadMax_BASE 0;
BA_ "GenSigSendType" SG_ 2583676147 battPack15TempSpreadMax_BASE 0;
BA_ "GenSigSendType" SG_ 2600403762 CVM50placeholder_BASE 0;
BA_ "GenSigSendType" SG_ 2600403763 CVM51placeholder_BASE 0;
BA_ "GenSigSendType" SG_ 2583677942 battAnalyticsPack02muxID_BASE 0;
BA_ "GenSigSendType" SG_ 2583677942 HVESP2highestCellTemp_BASE 0;
BA_ "GenSigSendType" SG_ 2583677942 HVESP2lowestCellTemp_BASE 0;
BA_ "GenSigSendType" SG_ 2583677942 battPack02dschrgEthrtcMax_BASE 0;
BA_ "GenSigSendType" SG_ 2583677942 HVESP2dischargeCapacity_BASE 0;
BA_ "GenSigSendType" SG_ 2583677942 HVESP2fastUpdateSOC_BASE 0;
BA_ "GenSigSendType" SG_ 2583677942 HVESP2voltageLevel_BASE 0;
BA_ "GenSigSendType" SG_ 2583677942 battPack02minCellVoltage_BASE 0;
BA_ "GenSigSendType" SG_ 2583677942 battPack02isoMeasResNegv_BASE 0;
BA_ "GenSigSendType" SG_ 2583677942 battPack02isoMeasResPosv_BASE 0;
BA_ "GenSigSendType" SG_ 2583677942 battPack02glblDscnnctReq_BASE 0;
BA_ "GenSigSendType" SG_ 2583677942 battPack02maxCellVoltage_BASE 0;
BA_ "GenSigSendType" SG_ 2583677942 HVESP2current_BASE 0;
BA_ "GenSigSendType" SG_ 2583677942 battPack02SOH_BASE 0;
BA_ "GenSigSendType" SG_ 2583677942 battPack02modeReq_BASE 0;
BA_ "GenSigSendType" SG_ 2583677881 battAnalyticsPack03muxID_BASE 0;
BA_ "GenSigSendType" SG_ 2583677881 HVESP3highestCellTemp_BASE 0;
BA_ "GenSigSendType" SG_ 2583677881 HVESP3lowestCellTemp_BASE 0;
BA_ "GenSigSendType" SG_ 2583677881 battPack03dschrgEthrtcMax_BASE 0;
BA_ "GenSigSendType" SG_ 2583677881 HVESP3dischargeCapacity_BASE 0;
BA_ "GenSigSendType" SG_ 2583677881 HVESP3fastUpdateSOC_BASE 0;
BA_ "GenSigSendType" SG_ 2583677881 battPack03minCellVoltage_BASE 0;
BA_ "GenSigSendType" SG_ 2583677881 HVESP3voltageLevel_BASE 0;
BA_ "GenSigSendType" SG_ 2583677881 battPack03isoMeasResPosv_BASE 0;
BA_ "GenSigSendType" SG_ 2583677881 battPack03isoMeasResNegv_BASE 0;
BA_ "GenSigSendType" SG_ 2583677881 battPack03glblDscnnctReq_BASE 0;
BA_ "GenSigSendType" SG_ 2583677881 HVESP3current_BASE 0;
BA_ "GenSigSendType" SG_ 2583677881 battPack03maxCellVoltage_BASE 0;
BA_ "GenSigSendType" SG_ 2583677881 battPack03SOH_BASE 0;
BA_ "GenSigSendType" SG_ 2583677881 battPack03modeReq_BASE 0;
BA_ "GenSigSendType" SG_ 2583677882 battAnalyticsPack04muxID_BASE 0;
BA_ "GenSigSendType" SG_ 2583677882 battPack04dschrgEthrtcMax_BASE 0;
BA_ "GenSigSendType" SG_ 2583677882 HVESP4lowestCellTemp_BASE 0;
BA_ "GenSigSendType" SG_ 2583677882 HVESP4highestCellTemp_BASE 0;
BA_ "GenSigSendType" SG_ 2583677882 HVESP4dischargeCapacity_BASE 0;
BA_ "GenSigSendType" SG_ 2583677882 HVESP4fastUpdateSOC_BASE 0;
BA_ "GenSigSendType" SG_ 2583677882 HVESP4voltageLevel_BASE 0;
BA_ "GenSigSendType" SG_ 2583677882 battPack04minCellVoltage_BASE 0;
BA_ "GenSigSendType" SG_ 2583677882 battPack04isoMeasResPosv_BASE 0;
BA_ "GenSigSendType" SG_ 2583677882 battPack04glblDscnnctReq_BASE 0;
BA_ "GenSigSendType" SG_ 2583677882 battPack04isoMeasResNegv_BASE 0;
BA_ "GenSigSendType" SG_ 2583677882 battPack04maxCellVoltage_BASE 0;
BA_ "GenSigSendType" SG_ 2583677882 HVESP4current_BASE 0;
BA_ "GenSigSendType" SG_ 2583677882 battPack04SOH_BASE 0;
BA_ "GenSigSendType" SG_ 2583677882 battPack04modeReq_BASE 0;
BA_ "GenSigSendType" SG_ 2583677883 battAnalyticsPack05muxID_BASE 0;
BA_ "GenSigSendType" SG_ 2583677883 battPack05dschrgEthrtcMax_BASE 0;
BA_ "GenSigSendType" SG_ 2583677883 HVESP5lowestCellTemp_BASE 0;
BA_ "GenSigSendType" SG_ 2583677883 HVESP5highestCellTemp_BASE 0;
BA_ "GenSigSendType" SG_ 2583677883 HVESP5fastUpdateSOC_BASE 0;
BA_ "GenSigSendType" SG_ 2583677883 HVESP5dischargeCapacity_BASE 0;
BA_ "GenSigSendType" SG_ 2583677883 battPack05minCellVoltage_BASE 0;
BA_ "GenSigSendType" SG_ 2583677883 HVESP5voltageLevel_BASE 0;
BA_ "GenSigSendType" SG_ 2583677883 battPack05glblDscnnctReq_BASE 0;
BA_ "GenSigSendType" SG_ 2583677883 battPack05isoMeasResNegv_BASE 0;
BA_ "GenSigSendType" SG_ 2583677883 battPack05isoMeasResPosv_BASE 0;
BA_ "GenSigSendType" SG_ 2583677883 HVESP5current_BASE 0;
BA_ "GenSigSendType" SG_ 2583677883 battPack05maxCellVoltage_BASE 0;
BA_ "GenSigSendType" SG_ 2583677883 battPack05SOH_BASE 0;
BA_ "GenSigSendType" SG_ 2583677883 battPack05modeReq_BASE 0;
BA_ "GenSigSendType" SG_ 2583677884 battAnalyticsPack06muxID_BASE 0;
BA_ "GenSigSendType" SG_ 2583677884 battPack06dschrgEthrtcMax_BASE 0;
BA_ "GenSigSendType" SG_ 2583677884 HVESP6highestCellTemp_BASE 0;
BA_ "GenSigSendType" SG_ 2583677884 HVESP6lowestCellTemp_BASE 0;
BA_ "GenSigSendType" SG_ 2583677884 HVESP6dischargeCapacity_BASE 0;
BA_ "GenSigSendType" SG_ 2583677884 HVESP6fastUpdateSOC_BASE 0;
BA_ "GenSigSendType" SG_ 2583677884 HVESP6voltageLevel_BASE 0;
BA_ "GenSigSendType" SG_ 2583677884 battPack06minCellVoltage_BASE 0;
BA_ "GenSigSendType" SG_ 2583677884 battPack06isoMeasResPosv_BASE 0;
BA_ "GenSigSendType" SG_ 2583677884 battPack06isoMeasResNegv_BASE 0;
BA_ "GenSigSendType" SG_ 2583677884 battPack06glblDscnnctReq_BASE 0;
BA_ "GenSigSendType" SG_ 2583677884 battPack06maxCellVoltage_BASE 0;
BA_ "GenSigSendType" SG_ 2583677884 HVESP6current_BASE 0;
BA_ "GenSigSendType" SG_ 2583677884 battPack06SOH_BASE 0;
BA_ "GenSigSendType" SG_ 2583677884 battPack06modeReq_BASE 0;
BA_ "GenSigSendType" SG_ 2583677886 battAnalyticsPack07muxID_BASE 0;
BA_ "GenSigSendType" SG_ 2583677886 HVESP7highestCellTemp_BASE 0;
BA_ "GenSigSendType" SG_ 2583677886 battPack07dschrgEthrtcMax_BASE 0;
BA_ "GenSigSendType" SG_ 2583677886 HVESP7lowestCellTemp_BASE 0;
BA_ "GenSigSendType" SG_ 2583677886 HVESP7dischargeCapacity_BASE 0;
BA_ "GenSigSendType" SG_ 2583677886 HVESP7fastUpdateSOC_BASE 0;
BA_ "GenSigSendType" SG_ 2583677886 battPack07minCellVoltage_BASE 0;
BA_ "GenSigSendType" SG_ 2583677886 HVESP7voltageLevel_BASE 0;
BA_ "GenSigSendType" SG_ 2583677886 battPack07isoMeasResNegv_BASE 0;
BA_ "GenSigSendType" SG_ 2583677886 battPack07isoMeasResPosv_BASE 0;
BA_ "GenSigSendType" SG_ 2583677886 battPack07glblDscnnctReq_BASE 0;
BA_ "GenSigSendType" SG_ 2583677886 HVESP7current_BASE 0;
BA_ "GenSigSendType" SG_ 2583677886 battPack07maxCellVoltage_BASE 0;
BA_ "GenSigSendType" SG_ 2583677886 battPack07SOH_BASE 0;
BA_ "GenSigSendType" SG_ 2583677886 battPack07modeReq_BASE 0;
BA_ "GenSigSendType" SG_ 2600423961 actClimateSys_BASE 0;
BA_ "GenSigSendType" SG_ 2600423961 actReqDefrost_BASE 0;
BA_ "GenSigSendType" SG_ 2600423961 actReqFootAir_BASE 0;
BA_ "GenSigSendType" SG_ 2600423961 actReqFrontWndwAir_BASE 0;
BA_ "GenSigSendType" SG_ 2600423961 actReqPrkHeat_BASE 0;
BA_ "GenSigSendType" SG_ 2600423961 actReqAC_BASE 0;
BA_ "GenSigSendType" SG_ 2600423961 actReqRecirAir_BASE 0;
BA_ "GenSigSendType" SG_ 2600423961 actReqSideWndwAir_BASE 0;
BA_ "GenSigSendType" SG_ 2600423961 actReqCabVentFan_BASE 0;
BA_ "GenSigSendType" SG_ 2600423961 actReqTempStage_BASE 0;
BA_ "GenSigSendType" SG_ 2600423961 actReqAutoMode_BASE 0;
BA_ "GenSigSendType" SG_ 2600423961 actReqTemp_BASE 0;
BA_ "GenSigSendType" SG_ 2600423961 actReqAutoRecirAir_BASE 0;
BA_ "GenSigSendType" SG_ 2600423961 actReqBodyAir_BASE 0;
BA_ "GenSigSendType" SG_ 2583677894 battAnalyticsPack08muxID_BASE 0;
BA_ "GenSigSendType" SG_ 2583677894 HVESP8lowestCellTemp_BASE 0;
BA_ "GenSigSendType" SG_ 2583677894 HVESP8highestCellTemp_BASE 0;
BA_ "GenSigSendType" SG_ 2583677894 battPack08dschrgEthrtcMax_BASE 0;
BA_ "GenSigSendType" SG_ 2583677894 HVESP8dischargeCapacity_BASE 0;
BA_ "GenSigSendType" SG_ 2583677894 HVESP8fastUpdateSOC_BASE 0;
BA_ "GenSigSendType" SG_ 2583677894 HVESP8voltageLevel_BASE 0;
BA_ "GenSigSendType" SG_ 2583677894 battPack08minCellVoltage_BASE 0;
BA_ "GenSigSendType" SG_ 2583677894 battPack08isoMeasResNegv_BASE 0;
BA_ "GenSigSendType" SG_ 2583677894 battPack08isoMeasResPosv_BASE 0;
BA_ "GenSigSendType" SG_ 2583677894 battPack08glblDscnnctReq_BASE 0;
BA_ "GenSigSendType" SG_ 2583677894 HVESP8current_BASE 0;
BA_ "GenSigSendType" SG_ 2583677894 battPack08maxCellVoltage_BASE 0;
BA_ "GenSigSendType" SG_ 2583677894 battPack08SOH_BASE 0;
BA_ "GenSigSendType" SG_ 2583677894 battPack08modeReq_BASE 0;
BA_ "GenSigSendType" SG_ 2583677895 battAnalyticsPack09muxID_BASE 0;
BA_ "GenSigSendType" SG_ 2583677895 HVESP9fastUpdateSOC_BASE 0;
BA_ "GenSigSendType" SG_ 2583677895 battPack09dschrgEthrtcMax_BASE 0;
BA_ "GenSigSendType" SG_ 2583677895 HVESP9lowestCellTemp_BASE 0;
BA_ "GenSigSendType" SG_ 2583677895 HVESP9dischargeCapacity_BASE 0;
BA_ "GenSigSendType" SG_ 2583677895 HVESP9highestCellTemp_BASE 0;
BA_ "GenSigSendType" SG_ 2583677895 battPack09minCellVoltage_BASE 0;
BA_ "GenSigSendType" SG_ 2583677895 HVESP9voltageLevel_BASE 0;
BA_ "GenSigSendType" SG_ 2583677895 battPack09isoMeasResPosv_BASE 0;
BA_ "GenSigSendType" SG_ 2583677895 battPack09glblDscnnctReq_BASE 0;
BA_ "GenSigSendType" SG_ 2583677895 battPack09isoMeasResNegv_BASE 0;
BA_ "GenSigSendType" SG_ 2583677895 HVESP9current_BASE 0;
BA_ "GenSigSendType" SG_ 2583677895 battPack09maxCellVoltage_BASE 0;
BA_ "GenSigSendType" SG_ 2583677895 battPack09SOH_BASE 0;
BA_ "GenSigSendType" SG_ 2583677895 battPack09modeReq_BASE 0;
BA_ "GenSigSendType" SG_ 2583677902 battAnalyticsPack11muxID_BASE 0;
BA_ "GenSigSendType" SG_ 2583677902 HVESP11highestCellTemp_BASE 0;
BA_ "GenSigSendType" SG_ 2583677902 HVESP11fastUpdateSOC_BASE 0;
BA_ "GenSigSendType" SG_ 2583677902 battPack11dschrgEthrtcMax_BASE 0;
BA_ "GenSigSendType" SG_ 2583677902 HVESP11dischargeCapacity_BASE 0;
BA_ "GenSigSendType" SG_ 2583677902 HVESP11lowestCellTemp_BASE 0;
BA_ "GenSigSendType" SG_ 2583677902 HVESP11voltageLevel_BASE 0;
BA_ "GenSigSendType" SG_ 2583677902 battPack11minCellVoltage_BASE 0;
BA_ "GenSigSendType" SG_ 2583677902 battPack11glblDscnnctReq_BASE 0;
BA_ "GenSigSendType" SG_ 2583677902 battPack11isoMeasResNegv_BASE 0;
BA_ "GenSigSendType" SG_ 2583677902 battPack11isoMeasResPosv_BASE 0;
BA_ "GenSigSendType" SG_ 2583677902 battPack11maxCellVoltage_BASE 0;
BA_ "GenSigSendType" SG_ 2583677902 HVESP11current_BASE 0;
BA_ "GenSigSendType" SG_ 2583677902 battPack11SOH_BASE 0;
BA_ "GenSigSendType" SG_ 2583677902 battPack11modeReq_BASE 0;
BA_ "GenSigSendType" SG_ 2583677903 battAnalyticsPack12muxID_BASE 0;
BA_ "GenSigSendType" SG_ 2583677903 battPack12dschrgEthrtcMax_BASE 0;
BA_ "GenSigSendType" SG_ 2583677903 HVESP12dischargeCapacity_BASE 0;
BA_ "GenSigSendType" SG_ 2583677903 HVESP12highestCellTemp_BASE 0;
BA_ "GenSigSendType" SG_ 2583677903 HVESP12lowestCellTemp_BASE 0;
BA_ "GenSigSendType" SG_ 2583677903 HVESP12fastUpdateSOC_BASE 0;
BA_ "GenSigSendType" SG_ 2583677903 battPack12minCellVoltage_BASE 0;
BA_ "GenSigSendType" SG_ 2583677903 HVESP12voltageLevel_BASE 0;
BA_ "GenSigSendType" SG_ 2583677903 battPack12glblDscnnctReq_BASE 0;
BA_ "GenSigSendType" SG_ 2583677903 battPack12isoMeasResPosv_BASE 0;
BA_ "GenSigSendType" SG_ 2583677903 battPack12isoMeasResNegv_BASE 0;
BA_ "GenSigSendType" SG_ 2583677903 HVESP12current_BASE 0;
BA_ "GenSigSendType" SG_ 2583677903 battPack12maxCellVoltage_BASE 0;
BA_ "GenSigSendType" SG_ 2583677903 battPack12SOH_BASE 0;
BA_ "GenSigSendType" SG_ 2583677903 battPack12modeReq_BASE 0;
BA_ "GenSigSendType" SG_ 2583677900 battAnalyticsPack10muxID_BASE 0;
BA_ "GenSigSendType" SG_ 2583677900 HVESP10fastUpdateSOC_BASE 0;
BA_ "GenSigSendType" SG_ 2583677900 HVESP10highestCellTemp_BASE 0;
BA_ "GenSigSendType" SG_ 2583677900 HVESP10dischargeCapacity_BASE 0;
BA_ "GenSigSendType" SG_ 2583677900 HVESP10lowestCellTemp_BASE 0;
BA_ "GenSigSendType" SG_ 2583677900 battPack10dschrgEthrtcMax_BASE 0;
BA_ "GenSigSendType" SG_ 2583677900 HVESP10voltageLevel_BASE 0;
BA_ "GenSigSendType" SG_ 2583677900 battPack10minCellVoltage_BASE 0;
BA_ "GenSigSendType" SG_ 2583677900 battPack10isoMeasResPosv_BASE 0;
BA_ "GenSigSendType" SG_ 2583677900 battPack10isoMeasResNegv_BASE 0;
BA_ "GenSigSendType" SG_ 2583677900 battPack10glblDscnnctReq_BASE 0;
BA_ "GenSigSendType" SG_ 2583677900 battPack10maxCellVoltage_BASE 0;
BA_ "GenSigSendType" SG_ 2583677900 HVESP10current_BASE 0;
BA_ "GenSigSendType" SG_ 2583677900 battPack10SOH_BASE 0;
BA_ "GenSigSendType" SG_ 2583677900 battPack10modeReq_BASE 0;
BA_ "GenSigSendType" SG_ 2583677939 battAnalyticsPack01muxID_BASE 0;
BA_ "GenSigSendType" SG_ 2583677939 battPack01dschrgEthrtcMax_BASE 0;
BA_ "GenSigSendType" SG_ 2583677939 HVESP1dischargeCapacity_BASE 0;
BA_ "GenSigSendType" SG_ 2583677939 HVESP1fastUpdateSOC_BASE 0;
BA_ "GenSigSendType" SG_ 2583677939 HVESP1highestCellTemp_BASE 0;
BA_ "GenSigSendType" SG_ 2583677939 HVESP1lowestCellTemp_BASE 0;
BA_ "GenSigSendType" SG_ 2583677939 battPack01minCellVoltage_BASE 0;
BA_ "GenSigSendType" SG_ 2583677939 HVESP1voltageLevel_BASE 0;
BA_ "GenSigSendType" SG_ 2583677939 battPack01glblDscnnctReq_BASE 0;
BA_ "GenSigSendType" SG_ 2583677939 battPack01isoMeasResNegv_BASE 0;
BA_ "GenSigSendType" SG_ 2583677939 battPack01isoMeasResPosv_BASE 0;
BA_ "GenSigSendType" SG_ 2583677939 battPack01maxCellVoltage_BASE 0;
BA_ "GenSigSendType" SG_ 2583677939 HVESP1current_BASE 0;
BA_ "GenSigSendType" SG_ 2583677939 battPack01SOH_BASE 0;
BA_ "GenSigSendType" SG_ 2583677939 battPack01modeReq_BASE 0;
BA_ "GenSigSendType" SG_ 2600454404 dispDriveProgram_VAR1 3;
BA_ "GenSigSendType" SG_ 2600454404 dispPreselDriveProgram_BASE 3;
BA_ "GenSigSendType" SG_ 2600454404 gearModeManualActive_BASE 3;
BA_ "GenSigSendType" SG_ 2600454404 dispDriveModeList_BASE 3;
BA_ "GenSigSendType" SG_ 2600454404 rollMaticActiveDisp_BASE 3;
BA_ "GenSigSendType" SG_ 2600454404 rollMaticEnabled_BASE 3;
BA_ "GenSigSendType" SG_ 2399077149 ASP2_CRC8_BASE 0;
BA_ "GenSigSendType" SG_ 2399077149 gearIndicator_BASE 0;
BA_ "GenSigSendType" SG_ 2399077149 engineSpeed_BASIS 0;
BA_ "GenSigSendType" SG_ 2399077149 parkBrakeActuatorFullyActivated_ 0;
BA_ "GenSigSendType" SG_ 2399077149 neutralIndicator_BASIS 0;
BA_ "GenSigSendType" SG_ 2399077149 drivelineEngaged_BASIS 0;
BA_ "GenSigSendType" SG_ 2399077149 reverseGearStatus_BASE 0;
BA_ "GenSigSendType" SG_ 2399077149 resPressReached_BASE 0;
BA_ "GenSigSendType" SG_ 2399077149 ASP2__cnt_BASE 0;
BA_ "GenSigSendType" SG_ 2566871591 diagCondVehSpd_BASE 0;
BA_ "GenSigSendType" SG_ 2566871591 drvSysActv_BASE 0;
BA_ "GenSigSendType" SG_ 2566871591 clamp15netw_BASE 0;
BA_ "GenSigSendType" SG_ 2566871591 StartUpInProgress_BASE 0;
BA_ "GenSigSendType" SG_ 2566871591 diagCondHighVoltage_BASE 0;
BA_ "GenSigSendType" SG_ 2566871591 diagCondEngSpd_BASE 0;
BA_ "GenSigSendType" SG_ 2566871591 E2EmsgCounterDiagVehState_BASE 0;
BA_ "GenSigSendType" SG_ 2566871591 E2EmsgChckSumDiagVehState_BASE 0;
BA_ "GenSigSendType" SG_ 2566871591 highResolutionTotalVehDistance_B 0;
BA_ "GenSigSendType" SG_ 2566871591 diagCondGearNeutral_BASE 0;
BA_ "GenSigSendType" SG_ 2566871591 diagCondParkingBrake_BASE 0;
BA_ "GenSigSendType" SG_ 2566871591 diagCondC1_BASE 0;
BA_ "GenSigSendType" SG_ 2382338571 EBS3_propMessage_CRC_BASE 0;
BA_ "GenSigSendType" SG_ 2382338571 ABSactive_BASIS 0;
BA_ "GenSigSendType" SG_ 2382338571 XBRsystemState_BASIS 0;
BA_ "GenSigSendType" SG_ 2382338571 BPposition_BASIS 0;
BA_ "GenSigSendType" SG_ 2382338571 cwsQuality_BASE 0;
BA_ "GenSigSendType" SG_ 2382338571 DTCactive_BASE 0;
BA_ "GenSigSendType" SG_ 2382338571 ABSfullyOperational_BASIS 0;
BA_ "GenSigSendType" SG_ 2382338571 EBSfullyOperational_BASIS 0;
BA_ "GenSigSendType" SG_ 2382338571 foundationBrakeUse_BASIS 0;
BA_ "GenSigSendType" SG_ 2382338571 ABSaxleActive_BASE 0;
BA_ "GenSigSendType" SG_ 2382338571 CombinedWheelSpeed_BASE 0;
BA_ "GenSigSendType" SG_ 2382338571 EBS3_propMessage_Cnt_BASE 0;
BA_ "GenSigSendType" SG_ 2600454441 extrnlChrgHVACimmedDisp_BASE 0;
BA_ "GenSigSendType" SG_ 2600454441 extrnlChrgSelPrcTypDisp_BASE 0;
BA_ "GenSigSendType" SG_ 2600454441 actPantoPositionStateDisp_BASE 0;
BA_ "GenSigSendType" SG_ 2600454441 extrnlChrgHoldDurImmedDisp_BASE 0;
BA_ "GenSigSendType" SG_ 2600454441 extrnlChrgBulkChrgDisp_BASE 0;
BA_ "GenSigSendType" SG_ 2600454441 extrnlChrgBulkSOCdisp_BASE 0;
BA_ "GenSigSendType" SG_ 2600454441 extrnlChrgHVACstateDisp_BASE 0;
BA_ "GenSigSendType" SG_ 2600454441 extrnlChrgTargetSOCdisp_BASE 0;
BA_ "GenSigSendType" SG_ 2600454441 extrnlChrgBulkSOC_BASE 0;
BA_ "GenSigSendType" SG_ 2600454441 extrnlChrgRenEnrgyPercDisp_BASE 0;
BA_ "GenSigSendType" SG_ 2600454441 extrnlChrgAMSstateDisp_BASE 0;
BA_ "GenSigSendType" SG_ 2600403757 mean100msDCpowerDS1_BASE 0;
BA_ "GenSigSendType" SG_ 2600403757 mean100msDCpowerDS2_BASE 0;
BA_ "GenSigSendType" SG_ 2600403757 mean100msPowerTES_BASE 0;
BA_ "GenSigSendType" SG_ 2600403757 actEnergyDischrgDrvTES_BASE 0;
BA_ "GenSigSendType" SG_ 2600415783 extnlChargingStAct_BASE 0;
BA_ "GenSigSendType" SG_ 2600415783 extrnlChrgWakeUpReq_BASE 0;
BA_ "GenSigSendType" SG_ 2600415783 preCondAirReq_BASE 0;
BA_ "GenSigSendType" SG_ 2600415783 preCondClimateReq_BASE 0;
BA_ "GenSigSendType" SG_ 2600415783 ambientAirTemperature_BASIS 0;
BA_ "GenSigSendType" SG_ 2600415783 stCombHeat_BASE 0;
BA_ "GenSigSendType" SG_ 2600415783 highVoltSysModeAct_BASE 0;
BA_ "GenSigSendType" SG_ 2600415783 networkWakeUpStAct_BASE 0;
BA_ "GenSigSendType" SG_ 2600415783 drvSysActv_BASE 0;
BA_ "GenSigSendType" SG_ 2600415783 thermalAlertPredctnTES_BASE 0;
BA_ "GenSigSendType" SG_ 2600415783 extrnlChrgVehRdy2Drv_BASE 0;
BA_ "GenSigSendType" SG_ 2566865813 BDM2_CRC_BASE 0;
BA_ "GenSigSendType" SG_ 2566865813 batt24Vlearning_A_BASE 0;
BA_ "GenSigSendType" SG_ 2566865813 actModelBatt24V_A_BASE 0;
BA_ "GenSigSendType" SG_ 2566865813 batt24VcapMax_A_BASE 0;
BA_ "GenSigSendType" SG_ 2566865813 tempActBatt24V_A_BASE 0;
BA_ "GenSigSendType" SG_ 2566865813 batt24VcapMaxT_A_BASE 0;
BA_ "GenSigSendType" SG_ 2566865813 batt24VcapAct_A_BASE 0;
BA_ "GenSigSendType" SG_ 2566865813 batt24VcapActT_A_BASE 0;
BA_ "GenSigSendType" SG_ 2566865813 BDM2_Cnt_BASE 0;
BA_ "GenSigSendType" SG_ 2566865772 BDM2_CRC_BASE 0;
BA_ "GenSigSendType" SG_ 2566865772 batt24Vlearning_B_BASE 0;
BA_ "GenSigSendType" SG_ 2566865772 actModelBatt24V_B_BASE 0;
BA_ "GenSigSendType" SG_ 2566865772 batt24VcapMax_B_BASE 0;
BA_ "GenSigSendType" SG_ 2566865772 tempActBatt24V_B_BASE 0;
BA_ "GenSigSendType" SG_ 2566865772 batt24VcapMaxT_B_BASE 0;
BA_ "GenSigSendType" SG_ 2566865772 batt24VcapAct_B_BASE 0;
BA_ "GenSigSendType" SG_ 2566865772 batt24VcapActT_B_BASE 0;
BA_ "GenSigSendType" SG_ 2566865772 BDM2_Cnt_BASE 0;
BA_ "GenSigSendType" SG_ 2667525633 driveProgramAppVersion_BASE 0;
BA_ "GenSigSendType" SG_ 2667525633 appMinValSlider1_BASE 0;
BA_ "GenSigSendType" SG_ 2667525633 appValSlider1_BASE 0;
BA_ "GenSigSendType" SG_ 2667525633 appMaxValSlider2_BASE 0;
BA_ "GenSigSendType" SG_ 2667525633 appMinValSlider2_BASE 0;
BA_ "GenSigSendType" SG_ 2667525633 appValSlider2_BASE 0;
BA_ "GenSigSendType" SG_ 2667525633 appEnaSwitch3_BASE 0;
BA_ "GenSigSendType" SG_ 2667525633 appValSwitch3_BASE 0;
BA_ "GenSigSendType" SG_ 2667525633 appEnaSwitch4_BASE 0;
BA_ "GenSigSendType" SG_ 2667525633 appValSwitch4_BASE 0;
BA_ "GenSigSendType" SG_ 2667525633 appEnaSwitch1_BASE 0;
BA_ "GenSigSendType" SG_ 2667525633 appEnaSwitch5_BASE 0;
BA_ "GenSigSendType" SG_ 2667525633 appValSwitch5_BASE 0;
BA_ "GenSigSendType" SG_ 2667525633 appMaxValSlider3_BASE 0;
BA_ "GenSigSendType" SG_ 2667525633 appMinValSlider3_BASE 0;
BA_ "GenSigSendType" SG_ 2667525633 appValSlider3_BASE 0;
BA_ "GenSigSendType" SG_ 2667525633 appEnaSwitch2_BASE 0;
BA_ "GenSigSendType" SG_ 2667525633 appValSwitch2_BASE 0;
BA_ "GenSigSendType" SG_ 2667525633 appValSwitch1_BASE 0;
BA_ "GenSigSendType" SG_ 2667525633 appMaxValSlider1_BASE 0;
BA_ "GenSigSendType" SG_ 2600403747 estAvgHVpower_ePTO_BASE 0;
BA_ "GenSigSendType" SG_ 2600403747 estAvgHVpowerHVAC_BASE 0;
BA_ "GenSigSendType" SG_ 2600403747 sMeanDCpowerDS1_BASE 0;
BA_ "GenSigSendType" SG_ 2600403747 sMeanDCpowerDS2_BASE 0;
BA_ "GenSigSendType" SG_ 2600403756 estAvgHVpowerCHS_BASE 0;
BA_ "GenSigSendType" SG_ 2600403756 estAvgHVpowerAMS_BASE 0;
BA_ "GenSigSendType" SG_ 2600403756 energyChargedEVSE_BASE 0;
BA_ "GenSigSendType" SG_ 2600403756 actEnergyChrgTES_BASE 0;
BA_ "GenSigSendType" SG_ 2600403781 clutchWork_BASE 0;
BA_ "GenSigSendType" SG_ 2600403781 neutPreWarnCnt_BASE 0;
BA_ "GenSigSendType" SG_ 2600403781 neutReqCounter_BASE 0;
BA_ "GenSigSendType" SG_ 2566807240 tyreWheelIdentification_T1_TO_TR 0;
BA_ "GenSigSendType" SG_ 2566807240 tireAirLeakageRate_T1_TO_TRUCK 0;
BA_ "GenSigSendType" SG_ 2566807240 tirePressureThresholdDetection_T 0;
BA_ "GenSigSendType" SG_ 2566807240 tireModulePowerSupply_T1_TO_TRUC 0;
BA_ "GenSigSendType" SG_ 2566807240 identificationDataIndex_BASE 0;
BA_ "GenSigSendType" SG_ 2566807240 identificationDataContent_BASE 0;
BA_ "GenSigSendType" SG_ 2566807240 tireTemperature_T1_TO_TRUCK 0;
VAL_ 2600460823 rmtTstrInstallScreenInfo_VAR1 0 "CLUSTER_ANYSCREEN" 1 "CLUSTER_SHUTDOWN_UPDATES_AVAILABLE" 2 "MANDIGITAL_UPDATES_AVAILABLE" 3 "MANDIGITAL_INSTALLATION_MENU" 4 "MANDIGITAL_INSTALLATION_MENU_INFO_UPDATE_X" 6 "MANDIGITAL_INSTALLATION_MENU_INSTALL_UPDATES_CONDITIONS_NOT_FULFILLED" 8 "MANDIGITAL_INSTALLATION_MENU_INSTALL_UPDATES_INSTALLATION_INFO" 9 "MANDIGITAL_INSTALLATION_MENU_INSTALL_UPDATES_INSTALLATION_PROCESS_INSTALLING" 10 "MANDIGITAL_INSTALLATION_MENU_INSTALL_UPDATES_INSTALLATION_PROCESS_CONDITION_NOT_FULFILLED_DURING_INSTALLATION_PROCESS" 11 "MANDIGITAL_INSTALLATION_MENU_INSTALL_UPDATES_INSTALLATION_PROCESS_UPDATE_SUCCESSFUL" 13 "MANDIGITAL_INSTALLATION_MENU_INSTALL_UPDATES_INSTALLATION_PROCESS_UPDATE_NOT_SUCCESSFUL" 14 "MANDIGITAL_INSTALLATION_MENU_INSTALL_UPDATES_INSTALLATION_PROCESS_UPDATE_FAILED" 16 "MANDIGITAL_INSTALLATION_MENU_INSTALL_UPDATES_INSTALLATION_PROCESS_UPDATE_INTERRUPTED" 17 "MANDIGITAL_NO_UPDATES_AVAILABLE" 18 "MANDIGITAL_INSTALLATION_MENU_INFO_DRIVERLESS_NA" 19 "MANDIGITAL_INSTALLATION_MENU_INFO_DRIVERLESS" 20 "MANDIGITAL_INSTALLATION_MENU_INSTALL_UPDATES_24V_BATTERY_TOO_LOW" 21 "MANDIGITAL_INSTALLATION_MENU_INSTALL_UPDATES_INSTALLATION_PROCESS_START_CONTINUE_UPDATE_DRIVERLESS_NA" 22 "MANDIGITAL_INSTALLATION_MENU_INSTALL_UPDATES_INSTALLATION_PROCESS_FLASHING_CLUSTER" 23 "MANDIGITAL_INSTALLATION_MENU_INSTALL_UPDATES_INSTALLATION_PROCESS_DRIVERLESS";
VAL_ 2600460823 rmtTstrDrivRestartConfirm_BASE 0 "not confirmed" 1 "confirmed" 2 "error" 3 "not available";
VAL_ 2600460823 tsiModeReq_BASE 0 "request mode 0 - OFF" 1 "request mode 1 - static signs" 2 "request mode 2 - flashing signs" 3 "request mode 3 - flashing signs and tone" 4 "no request active" 14 "error" 15 "not available";
VAL_ 2600460823 tsiTolSettingReq_BASE 0 "0kph / 0mph" 1 "1kph / 1mph" 2 "2kph / 2mph" 3 "3kph / 3mph" 4 "4kph / 4mph" 5 "5kph / 5mph" 6 "6kph / 6mph" 7 "7kph / 7mph" 8 "8kph / 8mph" 9 "9kph / 9mph" 10 "10kph / 10mph" 11 "11kph / 11mph" 12 "12kph / 12mph" 13 "13kph / 13mph" 14 "14kph / 14mph" 15 "15kph / 15mph" 16 "16kph / 16mph" 17 "17kph / 17mph" 18 "18kph / 18mph" 19 "19kph / 19mph" 20 "20kph / 20mph" 21 "No request active" 62 "error" 63 "not available";
VAL_ 2600460823 rmtTstrDrivEndConfirm_BASE 0 "not confirmed" 1 "confirmed" 2 "error" 3 "not available";
VAL_ 2600460823 tsiEnableSpdWrnReq_BASE 0 "request off" 1 "request on" 2 "no request" 14 "error" 15 "not available";
VAL_ 2600460823 tsiChangeInfoSettingReq_BASE 0 "request off" 1 "request on" 2 "no request" 14 "error" 15 "not available";
VAL_ 2600460823 EBAactivationReqVRU_BASE 0 "EBA VRU checkbox not selected" 1 "EBA VRU checkbox selected" 2 "error" 3 "not available";
VAL_ 2600460823 EBAactivationReq_BASE 0 "EBA Checkbox not selected" 1 "EBA Checkbox selected" 2 "error" 3 "not available";
VAL_ 2600460823 CCselectedModeReq_BASE 0 "ACC preselected" 1 "FGR preselected" 2 "FGB preselected" 13 "Cluster init" 14 "Error" 15 "Not available";
VAL_ 2600460823 DIGenableDistWrnReq_BASE 0 "request off" 1 "request on" 2 "no request" 14 "error" 15 "not available";
VAL_ 2600460823 updtMstrDrvrNotifReq_BASE 0 "deselected (no confirmation notifications)" 1 "selected (confirmation notifications)" 14 "error" 15 "not available";
VAL_ 2600460823 updtMstrDrvrAuth_BASE 0 "take no action" 1 "not authorized" 2 "authorized" 3 "postponed" 14 "error" 15 "not available";
VAL_ 2600460823 rmtTstrDrivUpdateConfirm_BASE 0 "not confirmed" 1 "confirmed" 2 "error" 3 "not available";
VAL_ 2566891559 bckgrndLghtAutoRevRqSave_BASE 0 "deactivated" 1 "activated" 2 "error" 3 "not available";
VAL_ 2566891559 ISCcondClutchOpen_BASE 0 "Condition fulfilled or not evaluated" 1 "Condition not fulfilled - Clutch open" 2 "error" 3 "not available";
VAL_ 2566891559 ISCcondEngWarming_BASE 0 "Condition fulfilled or not evaluated" 1 "Condition not fulfilled - Engine warming active" 2 "error" 3 "not available";
VAL_ 2566891559 ISCcondBrakeNotPressed_BASE 0 "Condition fulfilled or not evaluated" 1 "Condition not fulfilled - Brakepedal not pressed" 2 "error" 3 "not available";
VAL_ 2566891559 ISCcondGearEngaged_BASE 0 "Condition fulfilled or not evaluated" 1 "Condition not fulfilled - Gear engaged" 2 "error" 3 "not available";
VAL_ 2566891559 ISCcondNeutralEngaged_BASE 0 "Condition fulfilled or not evaluated" 1 "Condition not fulfilled - Neutral engaged" 2 "error" 3 "not available";
VAL_ 2566891559 ISCcondParkingBrakeActv_BASE 0 "Condition fulfilled or not evaluated" 1 "Condition not fulfilled - Parkingbrake activated" 2 "error" 3 "not available";
VAL_ 2566891559 ISCcondParkingBrakeNotActv_BASE 0 "Condition fulfilled or not evaluated" 1 "Condition not fulfilled - Parkingbrake not activated" 2 "error" 3 "not available";
VAL_ 2566891559 ISCcondVehSpd_BASE 0 "Condition fulfilled or not evaluated" 1 "Condition not fulfilled - vehicle speed too high" 2 "error" 3 "not available";
VAL_ 2566891559 ZDRact_BASE 0 "ZDR not active" 1 "ZDR active" 2 "error" 3 "not available";
VAL_ 2566891559 ISCcondBrakePressed_BASE 0 "Condition fulfilled or not evaluated" 1 "Condition not fulfilled - Brakepedal pressed" 2 "error" 3 "not available";
VAL_ 2566891559 dispInteriorLightAutoReq_BASE 0 "deactivated" 1 "activated" 2 "error" 3 "not available";
VAL_ 2566891559 dispIntLghtAutoCLreq_BASE 0 "deactivated" 1 "activated" 2 "error" 3 "not available";
VAL_ 2566891559 centrLubGreaseLvlLow_BASE 0 "grease level above threshold" 1 "grease level below threshold" 2 "error" 3 "not available";
VAL_ 2566891559 vehStandStill_BASE 0 "Vehicle not standing still" 1 "Vehicle standing still" 2 "error" 3 "not available";
VAL_ 2566891559 centralUnlockDoorSelect_BASE 0 "unlock driver door" 1 "unlock all doors" 2 "error" 3 "not available";
VAL_ 2566891559 dispEntranceLightAutoReq_BASE 0 "deactivated" 1 "activated";
VAL_ 2566891559 ureaLvlWarningDisp_BASE 0 "warning urea level not active" 1 "warning urea level active" 2 "error" 3 "not available";
VAL_ 2566891559 centralLockSpeedSelect_BASE 0 "OFF (don't lock doors)" 1 "ON (lock doors)" 2 "error" 3 "not available";
VAL_ 2566891559 ISCcondClutchClosed_BASE 0 "Condition fulfilled or not evaluated" 1 "Condition not fulfilled - Clutch closed" 2 "error" 3 "not available";
VAL_ 2566897703 genericBobuOut101_BASE 0 "passive" 1 "active" 2 "error" 3 "not available";
VAL_ 2566897703 genericBobuOut102_BASE 0 "passive" 1 "active" 2 "error" 3 "not available";
VAL_ 2566897703 genericBobuOut103_BASE 0 "passive" 1 "active" 2 "error" 3 "not available";
VAL_ 2566897703 genericBobuOut104_BASE 0 "passive" 1 "active" 2 "error" 3 "not available";
VAL_ 2566897703 genericBobuOut105_BASE 0 "passive" 1 "active" 2 "error" 3 "not available";
VAL_ 2566897703 genericBobuOut106_BASE 0 "passive" 1 "active" 2 "error" 3 "not available";
VAL_ 2566897703 genericBobuOut107_BASE 0 "passive" 1 "active" 2 "error" 3 "not available";
VAL_ 2566897703 genericBobuOut108_BASE 0 "passive" 1 "active" 2 "error" 2 "" 3 "not available";
VAL_ 2566897703 genericBobuOut109_BASE 0 "passive" 1 "active" 2 "error" 3 "not available";
VAL_ 2566897703 genericBobuOut110_BASE 0 "passive" 1 "active" 2 "error" 3 "not available";
VAL_ 2565879335 HVESSDischrgPwLimDueSOC_BASE 0 "No power limit for this reason" 1 "Power limit for this reason" 2 "error" 3 "not available";
VAL_ 2561553175 axleLocation_TPRS 15 "Axle1" 31 "Axle2" 47 "Axle3" 63 "Axle4" 79 "Axle5" 95 "Axle6" 224 "Spare tire 1" 254 "Error" 255 "Not Available";
VAL_ 2561553175 referenceTirePressureSetting_BAS 253 "enable spare tire monitoring" 254 "error" 255 "not available / disable spare tire monitoring";
VAL_ 2566764851 axleLocation_TPRI 15 "Axle1" 31 "Axle2" 47 "Axle3" 63 "Axle4" 79 "Axle5" 95 "Axle6" 224 "Spare tire 1" 254 "Error" 255 "Not Available";
VAL_ 2566876977 dispFireDtctnWrning1_BASE 0 "Fire Alarm is OFF" 1 "Fire Alarm is ON" 2 "error" 3 "not available";
VAL_ 2566876977 dispFireDtctnWrning2_BASE 0 "Fire Alarm is OFF" 1 "Fire Alarm is ON" 2 "error" 3 "not available";
VAL_ 2566876977 dispFireDtctnWrningFail2_BASE 0 "Fire Detection system Failure is Not Detected" 1 "Fire Detection system Failure is Detected" 2 "error" 3 "not available";
VAL_ 2566876977 dispFireDtctnWrningFail1_BASE 0 "Fire Detection system Failure is Not Detected" 1 "Fire Detection system Failure is Detected" 2 "error" 3 "not available";
VAL_ 2566876977 dispFireDtctnWrningFailure_BASE 0 "Fire Detection system Failure is Not Detected" 1 "Fire Detection system Failure is Detected" 2 "error" 3 "not available";
VAL_ 2566876977 dispFireDtctnWrning_BASE 0 "Fire Alarm is OFF" 1 "Fire Alarm is ON" 2 "error" 3 "not available";
VAL_ 2566845491 tirePressureThresholdDetection_B 0 "extreme over pressure" 1 "over pressure" 2 "no warning pressure" 3 "under pressure" 4 "extreme under pressure" 5 "not defined" 6 "error indicator" 7 "not available";
VAL_ 2382347251 BattSysState_BASE 0 "Init" 1 "HV off" 2 "HV off - Locked" 3 "HV off - Error" 4 "HV on - Precharge" 5 "HV on - Drive" 6 "HV on - Charging" 7 "HV on - Electrical afterrun" 8 "HV on - Zero current request" 9 "HV on - Error" 10 "Shutdown" 11 "Reserved" 12 "Reserved" 13 "Reserved" 14 "Error" 15 "Not available";
VAL_ 2382347251 BattSysEvacuationAlarm_BASE 0 "not active" 1 "active" 2 "error" 3 "not available";
VAL_ 2382347251 BattSysCritOtWarn_BASE 0 "Not Active" 1 "Active" 2 "Error" 3 "Not available";
VAL_ 2382347251 BattSysPickUpIntention_BASE 0 "Not intended" 1 "Intended" 2 "Error" 3 "Not available";
VAL_ 2382347251 battSysIsoMeasOkToCharge_BASE 0 "No recent measurement available" 1 "Ok to Charge" 2 "Not Ok to Charge" 14 "error" 15 "not available";
VAL_ 2600406039 uiLCWactivationReq_BASE 0 "LCW user interface not pressed" 1 "LCW user interface pressed" 2 "error" 3 "not available";
VAL_ 2600406039 uiTCWactivationReq_BASE 0 "TCW user interface not pressed" 1 "TCW user interface pressed" 2 "error" 3 "not available";
VAL_ 2600454695 dispBatt24VpwrSaveInfo_BASE 0 "no pwr save" 1 "level 1" 2 "level 2" 3 "shut off" 4 "charging current" 5 "level with engine running" 6 "temporarily not available";
VAL_ 2600454695 dispBatt24VpwrSaveWarning_BASE 0 "no warning" 1 "need engine start" 2 "not switch off engine" 3 "no cold crank" 4 "low battery level" 5 "engine speed by battery" 6 "need parking brake" 7 "deep discharge";
VAL_ 2600454695 dispBatt24VCheck_BASE 0 "no menue display" 1 "voltage only" 2 "battery menue not possible" 3 "exchanged battery A" 4 "exchanged battery B" 5 "training battery A" 6 "(reserved: training battery B)" 7 "(reserved 7)" 8 "(reserved 8)" 9 "(reserved 9)" 10 "battery condition no restriction" 11 "battery condition comfort restriction" 12 "battery condition function restriction" 13 "battery condition engine start restriction bar 2" 14 "battery condition engine start restritcion bar 1" 15 "battery condition engine start restriction bar 0" 16 "(reserved 16)" 17 "(reserved 17)" 18 "(reserved 18)" 19 "(reserved 19)" 20 "no recharging normal" 21 "recharging active" 22 "source failure SOC ok" 23 "source failure bar 2" 24 "source failure bar 1" 25 "source failure bar 0" 26 "(reserved 26)" 27 "(reserved 27)" 28 "(reserved 28)" 29 "(reserved 29)";
VAL_ 2566759463 engagemCnstnt_PTOengAccesDrive1_ 0 "Consent not given - PTO drive may not be engaged" 1 "Consent given - PTO drive may be engaged" 2 "Error" 3 "Not available";
VAL_ 2566759463 engagemStatus_transInpShaftPTO2_ 0 "Drive not engaged" 1 "Drive is engaged" 2 "Error" 3 "Not available";
VAL_ 2566759463 engagemStatus_transInpShaftPTO1_ 0 "Drive not engaged" 1 "Drive is engaged" 2 "Error" 3 "Not available";
VAL_ 2566759463 engagemStatus_PTOengineFlywheel_ 0 "Drive not engaged" 1 "Drive engaged" 2 "Error" 3 "Not available";
VAL_ 2566759463 atLeastOnePTOengaged_BASE 0 "No PTO drive is engaged" 1 "At least one PTO drive is engaged" 2 "Error" 3 "Not available";
VAL_ 2583651111 vehProfileBKClass_BASE 0 "No BK class or no setting" 1 "international" 2 "BK-Class 1" 3 "BK-Class 2" 4 "BK-Class 3" 5 "BK-Class 4" 14 "error" 15 "not available";
VAL_ 2583651111 vehProfileVehicleType_BASE 0 "Truck" 1 "Bus" 2 "error" 3 "not available";
VAL_ 2583651111 vehProfileNmbrOfTrailer_BASE 0 "No trailer" 1 "1 trailer" 2 "2 trailer" 3 "3 or more trailer" 4 "Not set" 14 "error" 15 "not available";
VAL_ 2600403755 dispRelFricBrkPow_BASE 0 "don't display friction brake interaction" 1 "display friction brake interaction" 2 "error" 3 "not available";
VAL_ 2600403755 fuelingIndicationDiesel_BASE 0 "no fueling detected" 1 "Diesel tank is refueled" 2 "Diesel tank is defueled" 3 "small rise / fill up detected" 14 "error" 15 "not available";
VAL_ 2600403755 fuelTankSrvllncStatus_BASE 0 "passive" 1 "mode concealed alert activated" 2 "mode acoustic alert activated" 3 "mode reserve 1 activated" 4 "mode reserve 2 activated" 5 "alert active - elect. fault (concealed)" 6 "alert active - elect. fault (acoustic)" 7 "alert active - fuel theft (concealed)" 8 "alert active - fuel theft (acoustic)" 9 "alert active - reserve 1 (concealed)" 10 "alert active - reserve1 (acoustic)" 11 "alert active - reserve2 (concealed)" 12 "alert active - reserve2 (acoustic)" 13 "reserve" 14 "error" 15 "not available";
VAL_ 2382346791 BattSysModeReq_BASE 0 "HV off" 1 "HV off - Emergency" 2 "HV on - Drive" 3 "HV on - Charge" 4 "Reserved" 5 "Reserved" 6 "Reserved" 7 "Reserved" 8 "Reserved" 9 "Reserved" 10 "Reserved" 11 "Reserved" 12 "Reserved" 13 "Reserved" 14 "Error" 15 "Not available";
VAL_ 2382346791 BattSysPickUpAllowed_BASE 0 "Inhibited" 1 "Allowed" 2 "Error" 3 "Not available";
VAL_ 2600454446 tmrMngmntTimerIndexDisp_BASE 0 "timer 1" 1 "timer 2" 2 "timer 3" 3 "timer 4" 4 "timer 5" 5 "timer 6" 6 "timer 7" 14 "error" 15 "not available";
VAL_ 2600454440 extrnlChrgPrcTypStateDisp_BASE 0 "no pricing/battery optimal" 1 "relative price" 2 "absolut price" 3 "CO2 emission" 4 "renewable energy %" 14 "error" 15 "not available";
VAL_ 2600454440 extrnlChrgCurrencyDisp_BASE 0 "to be defined";
VAL_ 2600454440 opModeVoKoESTC_BASE 0 "TES VoKo not active" 1 "TES VoKo active" 2 "error" 3 "not available";
VAL_ 2600421701 parkHeatAct_BASE 0 "park heater deactive" 1 "park heater active" 2 "error" 3 "not available";
VAL_ 2600421701 prkHtrStateADR_BASE 0 "ADR in park heater deactive" 1 "ADR in park heater active" 2 "error" 3 "not available";
VAL_ 2600421701 stateWtrPmpPrkHtr_BASE 0 "off" 1 "on" 2 "error" 3 "not available";
VAL_ 2600421701 prkHtrErrAct_BASE 0 "No Error Active" 1 "Error Active" 2 "AWH locked" 254 "error" 255 "not available";
VAL_ 2600424473 elecManButPrsHVAC_BASE 0 "no Button pressed" 1 "AC Button pressed" 2 "Auto Button pressed" 3 "air flow windows pressed" 4 "air flow body pressed" 5 "air flow foot pressed" 6 "defrost button pressed" 7 "programming button pressed" 8 "cabin fan level changed" 9 "target temperature changed" 10 "park heating pressed" 11 "recirculation auto pressed" 12 "recirculation manual pressed" 13 "windscreen heating pressed" 14 "air flow side window pressed" 254 "error" 255 "not available";
VAL_ 2600424473 actStandOp_BASE 0 "no stand operation active" 1 "park heater active" 2 "park cooling active" 3 "error park heating /cooling / ventilation" 4 "park ventilation active" 254 "error" 255 "not available";
VAL_ 2600424473 opModeHVAC_BASE 0 "off" 1 "hold" 2 "cool" 3 "heat" 4 "defrost" 5 "defog" 254 "error" 255 "not available";
VAL_ 2600424473 errActPrkHtr_BASE 0 "no restrictions" 1 "not enough fuel in tank";
VAL_ 2600424473 heatingModeActiveHVAC_BASE 0 "no heating mode active" 1 "heating mode active" 2 "error" 3 "not available";
VAL_ 2600421445 stateWtrVlvPrkHtr_BASE 0 "open" 1 "closed" 2 "mixing" 254 "error" 255 "not available";
VAL_ 2583677942 battAnalyticsPack02muxID_BASE 0 "layout 0" 1 "layout 1" 2 "layout 2" 3 "layout 3" 4 "layout 4" 5 "layout 5" 6 "layout 6" 7 "layout 7" 8 "layout 8" 9 "layout 9";
VAL_ 2583677942 battPack02modeReq_BASE 0 "HV off" 1 "HV off - emergency" 2 "HV on - drive" 3 "HV on - charge" 4 "HV on - prepare" 14 "error" 15 "not available";
VAL_ 2583677881 battAnalyticsPack03muxID_BASE 0 "layout 0" 1 "layout 1" 2 "layout 2" 3 "layout 3" 4 "layout 4" 5 "layout 5" 6 "layout 6" 7 "layout 7" 8 "layout 8" 9 "layout 9";
VAL_ 2583677881 battPack03modeReq_BASE 0 "HV off" 1 "HV off - emergency" 2 "HV on - drive" 3 "HV on - charge" 4 "HV on - prepare" 14 "error" 15 "not available";
VAL_ 2583677882 battAnalyticsPack04muxID_BASE 0 "layout 0" 1 "layout 1" 2 "layout 2" 3 "layout 3" 4 "layout 4" 5 "layout 5" 6 "layout 6" 7 "layout 7" 8 "layout 8" 9 "layout 9";
VAL_ 2583677882 battPack04modeReq_BASE 0 "HV off" 1 "HV off - emergency" 2 "HV on - drive" 3 "HV on - charge" 4 "HV on - prepare" 14 "error" 15 "not available";
VAL_ 2583677883 battAnalyticsPack05muxID_BASE 0 "layout 0" 1 "layout 1" 2 "layout 2" 3 "layout 3" 4 "layout 4" 5 "layout 5" 6 "layout 6" 7 "layout 7" 8 "layout 8" 9 "layout 9";
VAL_ 2583677883 battPack05modeReq_BASE 0 "HV off" 1 "HV off - emergency" 2 "HV on - drive" 3 "HV on - charge" 4 "HV on - prepare" 14 "error" 15 "not available";
VAL_ 2583677884 battAnalyticsPack06muxID_BASE 0 "layout 0" 1 "layout 1" 2 "layout 2" 3 "layout 3" 4 "layout 4" 5 "layout 5" 6 "layout 6" 7 "layout 7" 8 "layout 8" 9 "layout 9";
VAL_ 2583677884 battPack06modeReq_BASE 0 "HV off" 1 "HV off - emergency" 2 "HV on - drive" 3 "HV on - charge" 4 "HV on - prepare" 14 "error" 15 "not available";
VAL_ 2583677886 battAnalyticsPack07muxID_BASE 0 "layout 0" 1 "layout 1" 2 "layout 2" 3 "layout 3" 4 "layout 4" 5 "layout 5" 6 "layout 6" 7 "layout 7" 8 "layout 8" 9 "layout 9";
VAL_ 2583677886 battPack07modeReq_BASE 0 "HV off" 1 "HV off - emergency" 2 "HV on - drive" 3 "HV on - charge" 4 "HV on - prepare" 14 "error" 15 "not available";
VAL_ 2600423961 actClimateSys_BASE 0 "HVAC deactive" 1 "HVAC active" 2 "error" 3 "not available";
VAL_ 2600423961 actReqDefrost_BASE 0 "no request for defrost" 1 "request for defrost" 2 "error" 3 "not available";
VAL_ 2600423961 actReqFootAir_BASE 0 "no request for foot air." 1 "request for foot air." 2 "error" 3 "not available";
VAL_ 2600423961 actReqFrontWndwAir_BASE 0 "no request for front window air." 1 "request for front window air." 2 "error" 3 "not available";
VAL_ 2600423961 actReqPrkHeat_BASE 0 "no request for park heater" 1 "request for park heater" 2 "error" 3 "not available";
VAL_ 2600423961 actReqAC_BASE 0 "no request AC-usage" 1 "request AC usage" 2 "error" 3 "not available";
VAL_ 2600423961 actReqRecirAir_BASE 0 "no request for recirculation air" 1 "request for recirculation air" 2 "error" 3 "not available";
VAL_ 2600423961 actReqSideWndwAir_BASE 0 "no request for side window air" 1 "request for side window air" 2 "error" 3 "not available";
VAL_ 2600423961 actReqAutoMode_BASE 0 "no request for Auto Mode" 1 "request for Auto Mode usage" 2 "error" 3 "not available";
VAL_ 2600423961 actReqAutoRecirAir_BASE 0 "no request for auto recirculation air" 1 "request for auto recirculation air" 2 "error" 3 "not available";
VAL_ 2600423961 actReqBodyAir_BASE 0 "no request for body air" 1 "request for body air" 2 "error" 3 "not available";
VAL_ 2583677894 battAnalyticsPack08muxID_BASE 0 "layout 0" 1 "layout 1" 2 "layout 2" 3 "layout 3" 4 "layout 4" 5 "layout 5" 6 "layout 6" 7 "layout 7" 8 "layout 8" 9 "layout 9";
VAL_ 2583677894 battPack08modeReq_BASE 0 "HV off" 1 "HV off - emergency" 2 "HV on - drive" 3 "HV on - charge" 4 "HV on - prepare" 14 "error" 15 "not available";
VAL_ 2583677895 battAnalyticsPack09muxID_BASE 0 "layout 0" 1 "layout 1" 2 "layout 2" 3 "layout 3" 4 "layout 4" 5 "layout 5" 6 "layout 6" 7 "layout 7" 8 "layout 8" 9 "layout 9";
VAL_ 2583677895 battPack09modeReq_BASE 0 "HV off" 1 "HV off - emergency" 2 "HV on - drive" 3 "HV on - charge" 4 "HV on - prepare" 14 "error" 15 "not available";
VAL_ 2583677902 battAnalyticsPack11muxID_BASE 0 "layout 0" 1 "layout 1" 2 "layout 2" 3 "layout 3" 4 "layout 4" 5 "layout 5" 6 "layout 6" 7 "layout 7" 8 "layout 8" 9 "layout 9";
VAL_ 2583677902 battPack11modeReq_BASE 0 "HV off" 1 "HV off - emergency" 2 "HV on - drive" 3 "HV on - charge" 4 "HV on - prepare" 14 "error" 15 "not available";
VAL_ 2583677903 battAnalyticsPack12muxID_BASE 0 "layout 0" 1 "layout 1" 2 "layout 2" 3 "layout 3" 4 "layout 4" 5 "layout 5" 6 "layout 6" 7 "layout 7" 8 "layout 8" 9 "layout 9";
VAL_ 2583677903 battPack12modeReq_BASE 0 "HV off" 1 "HV off - emergency" 2 "HV on - drive" 3 "HV on - charge" 4 "HV on - prepare" 14 "error" 15 "not available";
VAL_ 2583677900 battAnalyticsPack10muxID_BASE 0 "layout 0" 1 "layout 1" 2 "layout 2" 3 "layout 3" 4 "layout 4" 5 "layout 5" 6 "layout 6" 7 "layout 7" 8 "layout 8" 9 "layout 9";
VAL_ 2583677900 battPack10modeReq_BASE 0 "HV off" 1 "HV off - emergency" 2 "HV on - drive" 3 "HV on - charge" 4 "HV on - prepare" 14 "error" 15 "not available";
VAL_ 2583677939 battAnalyticsPack01muxID_BASE 0 "layout 0" 1 "layout 1" 2 "layout 2" 3 "layout 3" 4 "layout 4" 5 "layout 5" 6 "layout 6" 7 "layout 7" 8 "layout 8" 9 "layout 9";
VAL_ 2583677939 battPack01modeReq_BASE 0 "HV off" 1 "HV off - emergency" 2 "HV on - drive" 3 "HV on - charge" 4 "HV on - prepare" 14 "error" 15 "not available";
VAL_ 2600454404 dispDriveProgram_VAR1 0 "programm 0 (default)" 1 "programm 1" 2 "programm 2" 3 "programm 3" 4 "programm 4" 5 "programm 5" 6 "programm 6" 7 "programm 7" 8 "programm 8" 9 "programm 9" 10 "programm 10" 11 "programm 11" 12 "programm 12" 13 "programm 13" 14 "error" 15 "not available";
VAL_ 2600454404 dispPreselDriveProgram_BASE 0 "programm 0 (default)" 1 "programm 1" 2 "programm 2" 3 "programm 3" 4 "programm 4" 5 "programm 5" 6 "programm 6" 7 "programm 7" 8 "programm 8" 9 "programm 9" 10 "programm 10" 11 "programm 11" 12 "programm 12" 13 "programm 13" 14 "error" 15 "not available";
VAL_ 2600454404 gearModeManualActive_BASE 0 "auto mode active" 1 "manual mode active" 2 "error" 3 "not available";
VAL_ 2600454404 dispDriveModeList_BASE 0 "Not visible" 1 "Visible" 2 "Special Effect" 3 "not available";
VAL_ 2600454404 rollMaticActiveDisp_BASE 0 "display rollmatic not active" 1 "display rollmatic active" 2 "error" 3 "not available";
VAL_ 2600454404 rollMaticEnabled_BASE 0 "rollMatic not enabled" 1 "rollMatic enabled" 2 "error" 3 "not available";
VAL_ 2399077149 gearIndicator_BASE 0 "Reverse Gears" 1 "Neutral Gear" 2 "Forward Gears" 3 "Error Indication not possible" 4 "not available 2" 5 "not available 3" 6 "not available 4" 7 "not available 5" 8 "not available 6" 9 "not available 7" 10 "not available 8" 11 "not available 9" 12 "not available 10" 13 "not available 11" 14 "error" 15 "not available";
VAL_ 2399077149 parkBrakeActuatorFullyActivated_ 0 "Parking Brake Actuator not fully activated" 1 "Parking Brake Actuator fully activated" 2 "Error" 3 "Not available";
VAL_ 2399077149 neutralIndicator_BASIS 0 "Off" 1 "On" 2 "Error" 3 "Not available";
VAL_ 2399077149 drivelineEngaged_BASIS 0 "driveline disengaged" 1 "driveline engaged" 2 "error" 3 "not available";
VAL_ 2399077149 reverseGearStatus_BASE 0 "reverse gear not engaged" 1 "reverse gear engaged" 2 "error indicator" 3 "not available";
VAL_ 2399077149 resPressReached_BASE 0 "inactive" 1 "active" 2 "error" 3 "not available";
VAL_ 2566871591 diagCondVehSpd_BASE 0 "condition not fullfilled" 1 "condition fullfilled" 2 "error" 3 "not available";
VAL_ 2566871591 drvSysActv_BASE 0 "drive system not active" 1 "drive system active" 2 "error" 3 "not available / not installed";
VAL_ 2566871591 clamp15netw_BASE 0 "Clamp 15 off" 1 "Clamp 15 on" 2 "error" 3 "not available";
VAL_ 2566871591 StartUpInProgress_BASE 0 "System is normal running" 1 "System is in engine start phase" 2 "error" 3 "not available";
VAL_ 2566871591 diagCondHighVoltage_BASE 0 "condition not fullfilled" 1 "condition fullfilled" 2 "error" 3 "not available";
VAL_ 2566871591 diagCondEngSpd_BASE 0 "condition not fullfilled" 1 "condition fullfilled" 2 "error" 3 "not available";
VAL_ 2566871591 diagCondGearNeutral_BASE 0 "condition not fullfilled" 1 "condition fullfilled" 2 "error" 3 "not available";
VAL_ 2566871591 diagCondParkingBrake_BASE 0 "condition not fullfilled" 1 "condition fullfilled" 2 "error" 3 "not available";
VAL_ 2566871591 diagCondC1_BASE 0 "condition not fullfilled" 1 "condition fullfilled" 2 "error" 3 "not available";
VAL_ 2382338571 ABSactive_BASIS 0 "ABS passive but installed" 1 "ABS active" 2 "Reserved" 3 "Don´t care";
VAL_ 2382338571 XBRsystemState_BASIS 0 "Any external brake demand will be accepted (brake system fully operational)" 1 "Only external brake demand of highest XBR Priority (00) will be accepted (e.g. because the temperature limit of the brake system is exceeded)" 2 "No external brake demand will be accepted (e.g. because of fault in brake system)" 3 "not available";
VAL_ 2382338571 cwsQuality_BASE 0 "ASIL D" 1 "ASIL B" 2 "ASIL QM" 3 "error" 4 "error" 5 "error" 6 "error" 7 "not available";
VAL_ 2382338571 DTCactive_BASE 0 "not active" 1 "active" 2 "error" 3 "not available";
VAL_ 2382338571 ABSfullyOperational_BASIS 0 "Not Fully Operaional" 1 "Fully Operational" 2 "Reserved" 3 "Take No Action";
VAL_ 2382338571 EBSfullyOperational_BASIS 0 "not fully operational" 1 "fully operational" 2 "error" 3 "not available";
VAL_ 2382338571 foundationBrakeUse_BASIS 0 "Foundation Brakes not in use" 1 "Foundation_Brakes in use" 2 "reserved" 3 "not available";
VAL_ 2382338571 ABSaxleActive_BASE 0 "ABS not active" 01 "ABS active axle 1" 02 "ABS active axle 2" 03 "ABS active axle 1 and 2" 04 "ABS active axle 3" 05 "ABS active axle 1 and 3" 06 "ABS active axle 2 and 3" 07 "ABS active axle 1, 2 and 3" 08 "ABS active axle 4" 09 "ABS active axle 1 and 4" 10 "ABS active axle 2 and 4" 11 "ABS active axle 1, 2 and 4" 12 "ABS active axle 3 and 4" 13 "ABS active axle 1, 3 and 4" 14 "ABS active axle 2, 3 and 4" 15 "ABS active axle 1, 2, 3 and 4" 16 "ABS active axle 5" 17 "ABS active axle 1and 5" 18 "ABS active axle 2 and 5" 19 "ABS active axle 1, 2 and 5" 20 "ABS active axle 3 and 5" 21 "ABS active axle 1, 3 and 5" 22 "ABS active axle 2, 3 and 5" 23 "ABS active axle 1, 2, 3 and 5" 24 "ABS active axle 4 and 5" 25 "ABS active axle 1, 4 and 5" 26 "ABS active axle 2, 4 and 5" 27 "ABS active axle 1, 2, 4 and 5" 28 "ABS active axle 3, 4 and 5" 29 "ABS active axle 1, 3, 4 and 5" 30 "ABS active axle 2, 3, 4 and 5" 31 "ABS active axle 1, 2, 3, 4 and 5" 32 "ABS active trailer" 33 "ABS active axle 1 and trailer" 34 "ABS active axle 2 and trailer" 35 "ABS active axle 1, 2 and trailer" 36 "ABS active axle 3 and trailer" 37 "ABS active axle 1, 3 and trailer" 38 "ABS active axle 2, 3 and trailer" 39 "ABS active axle 1, 2, 3 and trailer" 40 "ABS active axle 4 and trailer" 41 "ABS active axle 1, 4 and trailer" 42 "ABS active axle 2, 4 and trailer" 43 "ABS active axle 1, 2, 4 and trailer" 44 "ABS active axle 3, 4 and trailer" 45 "ABS active axle 1, 3, 4 and trailer" 46 "ABS active axle 2, 3, 4 and trailer" 47 "ABS active axle 1, 2, 3, 4 and trailer" 48 "ABS active axle 5 and trailer" 49 "ABS active axle 1, 5 and trailer" 50 "ABS active axle 2, 5 and trailer" 51 "ABS active axle 1, 2, 5 and trailer" 52 "ABS active axle 3, 5 and trailer" 53 "ABS active axle 1, 3, 5 and trailer" 54 "ABS active axle 2, 3, 5 and trailer" 55 "ABS active axle 1, 2, 3, 5 and trailer" 56 "ABS active axle 4, 5 and trailer" 57 "ABS active axle 1, 4, 5 and trailer" 58 "ABS active axle 2, 4, 5 and trailer" 59 "ABS active axle 1, 2, 4, 5 and trailer" 60 "ABS active axle 3, 4, 5 and trailer" 61 "ABS active axle 1, 3, 4, 5 and trailer" 62 "ABS active axle 2, 3, 4, 5 and trailer" 63 "ABS active axle 1, 2, 3, 4, 5 and trailer";
VAL_ 2600454441 extrnlChrgHVACimmedDisp_BASE 0 "not selected" 1 "immediate selected" 2 "timed selected" 14 "error" 15 "not available";
VAL_ 2600454441 extrnlChrgSelPrcTypDisp_BASE 0 "no pricing/battery optimal" 1 "relative price" 2 "absolut price" 3 "CO2 emission" 4 "renewable energy %" 14 "error" 15 "not available";
VAL_ 2600454441 actPantoPositionStateDisp_BASE 0 "not connected and idle" 1 "connecting" 2 "connected" 3 "disconnecting" 4 "position error - CP disconnected" 5 "position error - CP connected" 6 "not plausible" 14 "error" 15 "not available";
VAL_ 2600454441 extrnlChrgBulkChrgDisp_BASE 0 "not selected" 1 "selected" 2 "running" 3 "finished" 14 "error" 15 "not available";
VAL_ 2600454441 extrnlChrgHVACstateDisp_BASE 0 "not selected" 1 "selected" 2 "running" 3 "finished" 14 "error" 15 "not available";
VAL_ 2600454441 extrnlChrgAMSstateDisp_BASE 0 "not selected" 1 "selected" 2 "running" 3 "finished" 14 "error" 15 "not available";
VAL_ 2600415783 extnlChargingStAct_BASE 0 "char. not active - not connected" 1 "char. not active - connected" 2 "immediate charging active" 3 "immediate charging finished" 4 "charging can not start; error" 5 "char. not active- veh. not ready" 6 "timer/profile charging active" 7 "timer/profile charging finished" 8 "timer/profile charging paused" 14 "error" 15 "not available";
VAL_ 2600415783 extrnlChrgWakeUpReq_BASE 0 "no vehicle wake request" 1 "vehicle wake request" 2 "error" 3 "not available";
VAL_ 2600415783 preCondAirReq_BASE 0 "no AMS precond request" 1 "AMS precond request" 2 "error" 3 "not available";
VAL_ 2600415783 preCondClimateReq_BASE 0 "no HVAC precond request" 1 "HVAC precond request" 2 "error" 3 "not available";
VAL_ 2600415783 stCombHeat_BASE 0 "off" 1 "active" 2 "closed" 3 "failure" 14 "error" 15 "not available";
VAL_ 2600415783 highVoltSysModeAct_BASE 0 "HV-off" 1 "Drive" 2 "AC-Charge" 3 "DC-Charge" 4 "HVsysError" 5 "Discharging" 14 "Error" 15 "Not available";
VAL_ 2600415783 networkWakeUpStAct_BASE 0 "afterrun" 1 "clamp15 active" 2 "partial-wake active" 3 "vehicle-wake active" 4 "network inactive" 5 "network error" 14 "error" 15 "not available";
VAL_ 2600415783 drvSysActv_BASE 0 "drive system not active" 1 "drive system active" 2 "error" 3 "not available / not installed";
VAL_ 2600415783 thermalAlertPredctnTES_BASE 0 "no thermal alert detected" 1 "thermal alert detected" 2 "error" 3 "not available";
VAL_ 2600415783 extrnlChrgVehRdy2Drv_BASE 0 "vehicle is not ready to go" 1 "vehicle is ready to go" 2 "error" 3 "not available";
VAL_ 2566865813 batt24Vlearning_A_BASE 0 "None learned" 1 "capAct partLearned" 2 "Temp learned" 3 "LowDis partLearned" 4 "Temp learned capAct partLearned" 5 "Temp learned LowDis partLearned" 6 "capAct+LowDis partLearned" 7 "Temp learned capAct+LowDis partLearned" 8 "Temp learned capAct+capMax partLearned" 9 "Temp learned rest partLearned" 10 "Temp+capAct learned capMax partLearned" 11 "Temp+capAct+LowDis learned capMax partLearned" 12 "Temp+capAct+capmax learned" 13 "All learned" 14 "error" 15 "not available";
VAL_ 2566865813 actModelBatt24V_A_BASE 0 "no model" 1 "150Ah" 2 "180Ah" 3 "230Ah" 4 "reserved model 04" 5 "50Ah_AGM" 6 "85Ah_Gel" 7 "reserved model 07" 8 "170Ah_AGM" 9 "210Ah_AGM" 10 "reserved model 10" 11 "120Ah_AGM" 12 "210Ah_Gel" 13 "reserved model 13" 14 "reserved model 14" 15 "reserved model 15" 16 "reserved model 16" 17 "reserved model 17" 18 "reserved model 18" 19 "reserved model 19" 20 "reserved model 20" 254 "error" 255 "not available";
VAL_ 2566865772 batt24Vlearning_B_BASE 0 "None learned" 1 "capAct partLearned" 2 "Temp learned" 3 "LowDis partLearned" 4 "Temp learned capAct partLearned" 5 "Temp learned LowDis partLearned" 6 "capAct+LowDis partLearned" 7 "Temp learned capAct+LowDis partLearned" 8 "Temp learned capAct+capMax partLearned" 9 "Temp learned rest partLearned" 10 "Temp+capAct learned capMax partLearned" 11 "Temp+capAct+LowDis learned capMax partLearned" 12 "Temp+capAct+capmax learned" 13 "All learned" 14 "error" 15 "not available";
VAL_ 2566865772 actModelBatt24V_B_BASE 0 "no model" 1 "150Ah" 2 "180Ah" 3 "230Ah" 4 "reserved model 04" 5 "50Ah_AGM" 6 "85Ah_Gel" 7 "reserved model 07" 8 "170Ah_AGM" 9 "210Ah_AGM" 10 "reserved model 10" 11 "120Ah_AGM" 12 "210Ah_Gel" 13 "reserved model 13" 14 "reserved model 14" 15 "reserved model 15" 16 "reserved model 16" 17 "reserved model 17" 18 "reserved model 18" 19 "reserved model 19" 20 "reserved model 20" 254 "error" 255 "not available";
VAL_ 2667525633 appEnaSwitch3_BASE 0 "not enabled" 1 "enabled" 2 "error" 3 "not available";
VAL_ 2667525633 appValSwitch3_BASE 0 "not enabled" 1 "enabled" 2 "error" 3 "not available";
VAL_ 2667525633 appEnaSwitch4_BASE 0 "not enabled" 1 "enabled" 2 "error" 3 "not available";
VAL_ 2667525633 appValSwitch4_BASE 0 "not enabled" 1 "enabled" 2 "error" 3 "not available";
VAL_ 2667525633 appEnaSwitch1_BASE 0 "not enabled" 1 "enabled" 2 "error" 3 "not available";
VAL_ 2667525633 appEnaSwitch5_BASE 0 "not enabled" 1 "enabled" 2 "error" 3 "not available";
VAL_ 2667525633 appValSwitch5_BASE 0 "not enabled" 1 "enabled" 2 "error" 3 "not available";
VAL_ 2667525633 appEnaSwitch2_BASE 0 "not enabled" 1 "enabled" 2 "error" 3 "not available";
VAL_ 2667525633 appValSwitch2_BASE 0 "not enabled" 1 "enabled" 2 "error" 3 "not available";
VAL_ 2667525633 appValSwitch1_BASE 0 "not enabled" 1 "enabled" 2 "error" 3 "not available";
VAL_ 2566807240 tyreWheelIdentification_T1_TO_TR 0 "wheel position undefined, axle position undefined" 1 "wheel position 1, axle position undefined" 2 "wheel position 2, axle position undefined" 3 "wheel position 3, axle position undefined" 4 "wheel position 4, axle position undefined" 5 "wheel position 5, axle position undefined" 6 "wheel position 6, axle position undefined" 7 "wheel position 7, axle position undefined" 8 "wheel position 8, axle position undefined" 9 "wheel position 9, axle position undefined" 10 "wheel position 10, axle position undefined" 11 "wheel position 11, axle position undefined" 12 "wheel position 12, axle position undefined" 13 "wheel position 13, axle position undefined" 14 "wheel position 14, axle position undefined" 15 "wheel position 15, axle position undefined" 16 "wheel position undefined, axle position 1" 17 "wheel position 1, axle position 1" 18 "wheel position 2, axle position 1" 19 "wheel position 3, axle position 1" 20 "wheel position 4, axle position 1" 21 "wheel position 5, axle position 1" 22 "wheel position 6, axle position 1" 23 "wheel position 7, axle position 1" 24 "wheel position 8, axle position 1" 25 "wheel position 9, axle position 1" 26 "wheel position 10, axle position 1" 27 "wheel position 11, axle position 1" 28 "wheel position 12, axle position 1" 29 "wheel position 13, axle position 1" 30 "wheel position 14, axle position 1" 31 "wheel position 15, axle position 1" 32 "wheel position undefined, axle position 2" 33 "wheel position 1, axle position 2" 34 "wheel position 2, axle position 2" 35 "wheel position 3, axle position 2" 36 "wheel position 4, axle position 2" 37 "wheel position 5, axle position 2" 38 "wheel position 6, axle position 2" 39 "wheel position 7, axle position 2" 40 "wheel position 8, axle position 2" 41 "wheel position 9, axle position 2" 42 "wheel position 10, axle position 2" 43 "wheel position 11, axle position 2" 44 "wheel position 12, axle position 2" 45 "wheel position 13, axle position 2" 46 "wheel position 14, axle position 2" 47 "wheel position 15, axle position 2" 48 "wheel position undefined, axle position 3" 49 "wheel position 1, axle position 3" 50 "wheel position 2, axle position 3" 51 "wheel position 3, axle position 3" 52 "wheel position 4, axle position 3" 53 "wheel position 5, axle position 3" 54 "wheel position 6, axle position 3" 55 "wheel position 7, axle position 3" 56 "wheel position 8, axle position 3" 57 "wheel position 9, axle position 3" 58 "wheel position 10, axle position 3" 59 "wheel position 11, axle position 3" 60 "wheel position 12, axle position 3" 61 "wheel position 13, axle position 3" 62 "wheel position 14, axle position 3" 63 "wheel position 15, axle position 3" 64 "wheel position undefined, axle position 4" 65 "wheel position 1, axle position 4" 66 "wheel position 2, axle position 4" 67 "wheel position 3, axle position 4" 68 "wheel position 4, axle position 4" 69 "wheel position 5, axle position 4" 70 "wheel position 6, axle position 4" 71 "wheel position 7, axle position 4" 72 "wheel position 8, axle position 4" 73 "wheel position 9, axle position 4" 74 "wheel position 10, axle position 4" 75 "wheel position 11, axle position 4" 76 "wheel position 12, axle position 4" 77 "wheel position 13, axle position 4" 78 "wheel position 14, axle position 4" 79 "wheel position 15, axle position 4" 80 "wheel position undefined, axle position 5" 81 "wheel position 1, axle position 5" 82 "wheel position 2, axle position 5" 83 "wheel position 3, axle position 5" 84 "wheel position 4, axle position 5" 85 "wheel position 5, axle position 5" 86 "wheel position 6, axle position 5" 87 "wheel position 7, axle position 5" 88 "wheel position 8, axle position 5" 89 "wheel position 9, axle position 5" 90 "wheel position 10, axle position 5" 91 "wheel position 11, axle position 5" 92 "wheel position 12, axle position 5" 93 "wheel position 13, axle position 5" 94 "wheel position 14, axle position 5" 95 "wheel position 15, axle position 5" 96 "wheel position undefined, axle position 6" 97 "wheel position 1, axle position 6" 98 "wheel position 2, axle position 6" 99 "wheel position 3, axle position 6" 100 "wheel position 4, axle position 6" 101 "wheel position 5, axle position 6" 102 "wheel position 6, axle position 6" 103 "wheel position 7, axle position 6" 104 "wheel position 8, axle position 6" 105 "wheel position 9, axle position 6" 106 "wheel position 10, axle position 6" 107 "wheel position 11, axle position 6" 108 "wheel position 12, axle position 6" 109 "wheel position 13, axle position 6" 110 "wheel position 14, axle position 6" 111 "wheel position 15, axle position 6" 112 "wheel position undefined, axle position 7" 113 "wheel position 1, axle position 7" 114 "wheel position 2, axle position 7" 115 "wheel position 3, axle position 7" 116 "wheel position 4, axle position 7" 117 "wheel position 5, axle position 7" 118 "wheel position 6, axle position 7" 119 "wheel position 7, axle position 7" 120 "wheel position 8, axle position 7" 121 "wheel position 9, axle position 7" 122 "wheel position 10, axle position 7" 123 "wheel position 11, axle position 7" 124 "wheel position 12, axle position 7" 125 "wheel position 13, axle position 7" 126 "wheel position 14, axle position 7" 127 "wheel position 15, axle position 7" 128 "wheel position undefined, axle position 8" 129 "wheel position 1, axle position 8" 130 "wheel position 2, axle position 8" 131 "wheel position 3, axle position 8" 132 "wheel position 4, axle position 8" 133 "wheel position 5, axle position 8" 134 "wheel position 6, axle position 8" 135 "wheel position 7, axle position 8" 136 "wheel position 8, axle position 8" 137 "wheel position 9, axle position 8" 138 "wheel position 10, axle position 8" 139 "wheel position 11, axle position 8" 140 "wheel position 12, axle position 8" 141 "wheel position 13, axle position 8" 142 "wheel position 14, axle position 8" 143 "wheel position 15, axle position 8" 144 "wheel position undefined, axle position 9" 145 "wheel position 1, axle position 9" 146 "wheel position 2, axle position 9" 147 "wheel position 3, axle position 9" 148 "wheel position 4, axle position 9" 149 "wheel position 5, axle position 9" 150 "wheel position 6, axle position 9" 151 "wheel position 7, axle position 9" 152 "wheel position 8, axle position 9" 153 "wheel position 9, axle position 9" 154 "wheel position 10, axle position 9" 155 "wheel position 11, axle position 9" 156 "wheel position 12, axle position 9" 157 "wheel position 13, axle position 9" 158 "wheel position 14, axle position 9" 159 "wheel position 15, axle position 9" 160 "wheel position undefined, axle position 10" 161 "wheel position 1, axle position 10" 162 "wheel position 2, axle position 10" 163 "wheel position 3, axle position 10" 164 "wheel position 4, axle position 10" 165 "wheel position 5, axle position 10" 166 "wheel position 6, axle position 10" 167 "wheel position 7, axle position 10" 168 "wheel position 8, axle position 10" 169 "wheel position 9, axle position 10" 170 "wheel position 10, axle position 10" 171 "wheel position 11, axle position 10" 172 "wheel position 12, axle position 10" 173 "wheel position 13, axle position 10" 174 "wheel position 14, axle position 10" 175 "wheel position 15, axle position 10" 176 "wheel position undefined, axle position 11" 177 "wheel position 1, axle position 11" 178 "wheel position 2, axle position 11" 179 "wheel position 3, axle position 11" 180 "wheel position 4, axle position 11" 181 "wheel position 5, axle position 11" 182 "wheel position 6, axle position 11" 183 "wheel position 7, axle position 11" 184 "wheel position 8, axle position 11" 185 "wheel position 9, axle position 11" 186 "wheel position 10, axle position 11" 187 "wheel position 11, axle position 11" 188 "wheel position 12, axle position 11" 189 "wheel position 13, axle position 11" 190 "wheel position 14, axle position 11" 191 "wheel position 15, axle position 11" 192 "wheel position undefined, axle position 12" 193 "wheel position 1, axle position 12" 194 "wheel position 2, axle position 12" 195 "wheel position 3, axle position 12" 196 "wheel position 4, axle position 12" 197 "wheel position 5, axle position 12" 198 "wheel position 6, axle position 12" 199 "wheel position 7, axle position 12" 200 "wheel position 8, axle position 12" 201 "wheel position 9, axle position 12" 202 "wheel position 10, axle position 12" 203 "wheel position 11, axle position 12" 204 "wheel position 12, axle position 12" 205 "wheel position 13, axle position 12" 206 "wheel position 14, axle position 12" 207 "wheel position 15, axle position 12" 208 "wheel position undefined, axle position 13" 209 "wheel position 1, axle position 13" 210 "wheel position 2, axle position 13" 211 "wheel position 3, axle position 13" 212 "wheel position 4, axle position 13" 213 "wheel position 5, axle position 13" 214 "wheel position 6, axle position 13" 215 "wheel position 7, axle position 13" 216 "wheel position 8, axle position 13" 217 "wheel position 9, axle position 13" 218 "wheel position 10, axle position 13" 219 "wheel position 11, axle position 13" 220 "wheel position 12, axle position 13" 221 "wheel position 13, axle position 13" 222 "wheel position 14, axle position 13" 223 "wheel position 15, axle position 13" 224 "wheel position undefined, axle position 14" 225 "wheel position 1, axle position 14" 226 "wheel position 2, axle position 14" 227 "wheel position 3, axle position 14" 228 "wheel position 4, axle position 14" 229 "wheel position 5, axle position 14" 230 "wheel position 6, axle position 14" 231 "wheel position 7, axle position 14" 232 "wheel position 8, axle position 14" 233 "wheel position 9, axle position 14" 234 "wheel position 10, axle position 14" 235 "wheel position 11, axle position 14" 236 "wheel position 12, axle position 14" 237 "wheel position 13, axle position 14" 238 "wheel position 14, axle position 14" 239 "wheel position 15, axle position 14" 240 "wheel position undefined, axle position 15" 241 "wheel position 1, axle position 15" 242 "wheel position 2, axle position 15" 243 "wheel position 3, axle position 15" 244 "wheel position 4, axle position 15" 245 "wheel position 5, axle position 15" 246 "wheel position 6, axle position 15" 247 "wheel position 7, axle position 15" 248 "wheel position 8, axle position 15" 249 "wheel position 9, axle position 15" 250 "wheel position 10, axle position 15" 251 "wheel position 11, axle position 15" 252 "wheel position 12, axle position 15" 253 "wheel position 13, axle position 15" 254 "wheel position 14, axle position 15" 255 "wheel position 15, axle position 15";
VAL_ 2566807240 tirePressureThresholdDetection_T 0 "extreme over pressure" 1 "over pressure" 2 "no warning pressure" 3 "under pressure" 4 "extreme under pressure" 5 "not defined" 6 "error indicator" 7 "not available";
VAL_ 2566807240 tireModulePowerSupply_T1_TO_TRUC 0 "Insufficient power supply" 1 "Sufficient power supply" 2 "error" 3 "not available";

SG_MUL_VAL_ 2583677942 HVESP2highestCellTemp_BASE battAnalyticsPack02muxID_BASE 5-5;
SG_MUL_VAL_ 2583677942 HVESP2lowestCellTemp_BASE battAnalyticsPack02muxID_BASE 6-6;
SG_MUL_VAL_ 2583677942 battPack02dschrgEthrtcMax_BASE battAnalyticsPack02muxID_BASE 4-4;
SG_MUL_VAL_ 2583677942 HVESP2dischargeCapacity_BASE battAnalyticsPack02muxID_BASE 3-3;
SG_MUL_VAL_ 2583677942 HVESP2fastUpdateSOC_BASE battAnalyticsPack02muxID_BASE 0-0;
SG_MUL_VAL_ 2583677942 HVESP2voltageLevel_BASE battAnalyticsPack02muxID_BASE 0-0;
SG_MUL_VAL_ 2583677942 battPack02minCellVoltage_BASE battAnalyticsPack02muxID_BASE 1-1;
SG_MUL_VAL_ 2583677942 battPack02isoMeasResNegv_BASE battAnalyticsPack02muxID_BASE 3-3;
SG_MUL_VAL_ 2583677942 battPack02isoMeasResPosv_BASE battAnalyticsPack02muxID_BASE 2-2;
SG_MUL_VAL_ 2583677942 battPack02glblDscnnctReq_BASE battAnalyticsPack02muxID_BASE 0-0;
SG_MUL_VAL_ 2583677942 battPack02maxCellVoltage_BASE battAnalyticsPack02muxID_BASE 1-1;
SG_MUL_VAL_ 2583677942 HVESP2current_BASE battAnalyticsPack02muxID_BASE 0-0;
SG_MUL_VAL_ 2583677942 battPack02SOH_BASE battAnalyticsPack02muxID_BASE 1-1;
SG_MUL_VAL_ 2583677942 battPack02modeReq_BASE battAnalyticsPack02muxID_BASE 0-0;
SG_MUL_VAL_ 2583677881 HVESP3highestCellTemp_BASE battAnalyticsPack03muxID_BASE 5-5;
SG_MUL_VAL_ 2583677881 HVESP3lowestCellTemp_BASE battAnalyticsPack03muxID_BASE 6-6;
SG_MUL_VAL_ 2583677881 battPack03dschrgEthrtcMax_BASE battAnalyticsPack03muxID_BASE 4-4;
SG_MUL_VAL_ 2583677881 HVESP3dischargeCapacity_BASE battAnalyticsPack03muxID_BASE 3-3;
SG_MUL_VAL_ 2583677881 HVESP3fastUpdateSOC_BASE battAnalyticsPack03muxID_BASE 0-0;
SG_MUL_VAL_ 2583677881 battPack03minCellVoltage_BASE battAnalyticsPack03muxID_BASE 1-1;
SG_MUL_VAL_ 2583677881 HVESP3voltageLevel_BASE battAnalyticsPack03muxID_BASE 0-0;
SG_MUL_VAL_ 2583677881 battPack03isoMeasResPosv_BASE battAnalyticsPack03muxID_BASE 2-2;
SG_MUL_VAL_ 2583677881 battPack03isoMeasResNegv_BASE battAnalyticsPack03muxID_BASE 3-3;
SG_MUL_VAL_ 2583677881 battPack03glblDscnnctReq_BASE battAnalyticsPack03muxID_BASE 0-0;
SG_MUL_VAL_ 2583677881 HVESP3current_BASE battAnalyticsPack03muxID_BASE 0-0;
SG_MUL_VAL_ 2583677881 battPack03maxCellVoltage_BASE battAnalyticsPack03muxID_BASE 1-1;
SG_MUL_VAL_ 2583677881 battPack03SOH_BASE battAnalyticsPack03muxID_BASE 1-1;
SG_MUL_VAL_ 2583677881 battPack03modeReq_BASE battAnalyticsPack03muxID_BASE 0-0;
SG_MUL_VAL_ 2583677882 battPack04dschrgEthrtcMax_BASE battAnalyticsPack04muxID_BASE 4-4;
SG_MUL_VAL_ 2583677882 HVESP4lowestCellTemp_BASE battAnalyticsPack04muxID_BASE 6-6;
SG_MUL_VAL_ 2583677882 HVESP4highestCellTemp_BASE battAnalyticsPack04muxID_BASE 5-5;
SG_MUL_VAL_ 2583677882 HVESP4dischargeCapacity_BASE battAnalyticsPack04muxID_BASE 3-3;
SG_MUL_VAL_ 2583677882 HVESP4fastUpdateSOC_BASE battAnalyticsPack04muxID_BASE 0-0;
SG_MUL_VAL_ 2583677882 HVESP4voltageLevel_BASE battAnalyticsPack04muxID_BASE 0-0;
SG_MUL_VAL_ 2583677882 battPack04minCellVoltage_BASE battAnalyticsPack04muxID_BASE 1-1;
SG_MUL_VAL_ 2583677882 battPack04isoMeasResPosv_BASE battAnalyticsPack04muxID_BASE 2-2;
SG_MUL_VAL_ 2583677882 battPack04glblDscnnctReq_BASE battAnalyticsPack04muxID_BASE 0-0;
SG_MUL_VAL_ 2583677882 battPack04isoMeasResNegv_BASE battAnalyticsPack04muxID_BASE 3-3;
SG_MUL_VAL_ 2583677882 battPack04maxCellVoltage_BASE battAnalyticsPack04muxID_BASE 1-1;
SG_MUL_VAL_ 2583677882 HVESP4current_BASE battAnalyticsPack04muxID_BASE 0-0;
SG_MUL_VAL_ 2583677882 battPack04SOH_BASE battAnalyticsPack04muxID_BASE 1-1;
SG_MUL_VAL_ 2583677882 battPack04modeReq_BASE battAnalyticsPack04muxID_BASE 0-0;
SG_MUL_VAL_ 2583677883 battPack05dschrgEthrtcMax_BASE battAnalyticsPack05muxID_BASE 4-4;
SG_MUL_VAL_ 2583677883 HVESP5lowestCellTemp_BASE battAnalyticsPack05muxID_BASE 6-6;
SG_MUL_VAL_ 2583677883 HVESP5highestCellTemp_BASE battAnalyticsPack05muxID_BASE 5-5;
SG_MUL_VAL_ 2583677883 HVESP5fastUpdateSOC_BASE battAnalyticsPack05muxID_BASE 0-0;
SG_MUL_VAL_ 2583677883 HVESP5dischargeCapacity_BASE battAnalyticsPack05muxID_BASE 3-3;
SG_MUL_VAL_ 2583677883 battPack05minCellVoltage_BASE battAnalyticsPack05muxID_BASE 1-1;
SG_MUL_VAL_ 2583677883 HVESP5voltageLevel_BASE battAnalyticsPack05muxID_BASE 0-0;
SG_MUL_VAL_ 2583677883 battPack05glblDscnnctReq_BASE battAnalyticsPack05muxID_BASE 0-0;
SG_MUL_VAL_ 2583677883 battPack05isoMeasResNegv_BASE battAnalyticsPack05muxID_BASE 3-3;
SG_MUL_VAL_ 2583677883 battPack05isoMeasResPosv_BASE battAnalyticsPack05muxID_BASE 2-2;
SG_MUL_VAL_ 2583677883 HVESP5current_BASE battAnalyticsPack05muxID_BASE 0-0;
SG_MUL_VAL_ 2583677883 battPack05maxCellVoltage_BASE battAnalyticsPack05muxID_BASE 1-1;
SG_MUL_VAL_ 2583677883 battPack05SOH_BASE battAnalyticsPack05muxID_BASE 1-1;
SG_MUL_VAL_ 2583677883 battPack05modeReq_BASE battAnalyticsPack05muxID_BASE 0-0;
SG_MUL_VAL_ 2583677884 battPack06dschrgEthrtcMax_BASE battAnalyticsPack06muxID_BASE 4-4;
SG_MUL_VAL_ 2583677884 HVESP6highestCellTemp_BASE battAnalyticsPack06muxID_BASE 5-5;
SG_MUL_VAL_ 2583677884 HVESP6lowestCellTemp_BASE battAnalyticsPack06muxID_BASE 6-6;
SG_MUL_VAL_ 2583677884 HVESP6dischargeCapacity_BASE battAnalyticsPack06muxID_BASE 3-3;
SG_MUL_VAL_ 2583677884 HVESP6fastUpdateSOC_BASE battAnalyticsPack06muxID_BASE 0-0;
SG_MUL_VAL_ 2583677884 HVESP6voltageLevel_BASE battAnalyticsPack06muxID_BASE 0-0;
SG_MUL_VAL_ 2583677884 battPack06minCellVoltage_BASE battAnalyticsPack06muxID_BASE 1-1;
SG_MUL_VAL_ 2583677884 battPack06isoMeasResPosv_BASE battAnalyticsPack06muxID_BASE 2-2;
SG_MUL_VAL_ 2583677884 battPack06isoMeasResNegv_BASE battAnalyticsPack06muxID_BASE 3-3;
SG_MUL_VAL_ 2583677884 battPack06glblDscnnctReq_BASE battAnalyticsPack06muxID_BASE 0-0;
SG_MUL_VAL_ 2583677884 battPack06maxCellVoltage_BASE battAnalyticsPack06muxID_BASE 1-1;
SG_MUL_VAL_ 2583677884 HVESP6current_BASE battAnalyticsPack06muxID_BASE 0-0;
SG_MUL_VAL_ 2583677884 battPack06SOH_BASE battAnalyticsPack06muxID_BASE 1-1;
SG_MUL_VAL_ 2583677884 battPack06modeReq_BASE battAnalyticsPack06muxID_BASE 0-0;
SG_MUL_VAL_ 2583677886 HVESP7highestCellTemp_BASE battAnalyticsPack07muxID_BASE 5-5;
SG_MUL_VAL_ 2583677886 battPack07dschrgEthrtcMax_BASE battAnalyticsPack07muxID_BASE 4-4;
SG_MUL_VAL_ 2583677886 HVESP7lowestCellTemp_BASE battAnalyticsPack07muxID_BASE 6-6;
SG_MUL_VAL_ 2583677886 HVESP7dischargeCapacity_BASE battAnalyticsPack07muxID_BASE 3-3;
SG_MUL_VAL_ 2583677886 HVESP7fastUpdateSOC_BASE battAnalyticsPack07muxID_BASE 0-0;
SG_MUL_VAL_ 2583677886 battPack07minCellVoltage_BASE battAnalyticsPack07muxID_BASE 1-1;
SG_MUL_VAL_ 2583677886 HVESP7voltageLevel_BASE battAnalyticsPack07muxID_BASE 0-0;
SG_MUL_VAL_ 2583677886 battPack07isoMeasResNegv_BASE battAnalyticsPack07muxID_BASE 3-3;
SG_MUL_VAL_ 2583677886 battPack07isoMeasResPosv_BASE battAnalyticsPack07muxID_BASE 2-2;
SG_MUL_VAL_ 2583677886 battPack07glblDscnnctReq_BASE battAnalyticsPack07muxID_BASE 0-0;
SG_MUL_VAL_ 2583677886 HVESP7current_BASE battAnalyticsPack07muxID_BASE 0-0;
SG_MUL_VAL_ 2583677886 battPack07maxCellVoltage_BASE battAnalyticsPack07muxID_BASE 1-1;
SG_MUL_VAL_ 2583677886 battPack07SOH_BASE battAnalyticsPack07muxID_BASE 1-1;
SG_MUL_VAL_ 2583677886 battPack07modeReq_BASE battAnalyticsPack07muxID_BASE 0-0;
SG_MUL_VAL_ 2583677894 HVESP8lowestCellTemp_BASE battAnalyticsPack08muxID_BASE 6-6;
SG_MUL_VAL_ 2583677894 HVESP8highestCellTemp_BASE battAnalyticsPack08muxID_BASE 5-5;
SG_MUL_VAL_ 2583677894 battPack08dschrgEthrtcMax_BASE battAnalyticsPack08muxID_BASE 4-4;
SG_MUL_VAL_ 2583677894 HVESP8dischargeCapacity_BASE battAnalyticsPack08muxID_BASE 3-3;
SG_MUL_VAL_ 2583677894 HVESP8fastUpdateSOC_BASE battAnalyticsPack08muxID_BASE 0-0;
SG_MUL_VAL_ 2583677894 HVESP8voltageLevel_BASE battAnalyticsPack08muxID_BASE 0-0;
SG_MUL_VAL_ 2583677894 battPack08minCellVoltage_BASE battAnalyticsPack08muxID_BASE 1-1;
SG_MUL_VAL_ 2583677894 battPack08isoMeasResNegv_BASE battAnalyticsPack08muxID_BASE 3-3;
SG_MUL_VAL_ 2583677894 battPack08isoMeasResPosv_BASE battAnalyticsPack08muxID_BASE 2-2;
SG_MUL_VAL_ 2583677894 battPack08glblDscnnctReq_BASE battAnalyticsPack08muxID_BASE 0-0;
SG_MUL_VAL_ 2583677894 HVESP8current_BASE battAnalyticsPack08muxID_BASE 0-0;
SG_MUL_VAL_ 2583677894 battPack08maxCellVoltage_BASE battAnalyticsPack08muxID_BASE 1-1;
SG_MUL_VAL_ 2583677894 battPack08SOH_BASE battAnalyticsPack08muxID_BASE 1-1;
SG_MUL_VAL_ 2583677894 battPack08modeReq_BASE battAnalyticsPack08muxID_BASE 0-0;
SG_MUL_VAL_ 2583677895 HVESP9fastUpdateSOC_BASE battAnalyticsPack09muxID_BASE 0-0;
SG_MUL_VAL_ 2583677895 battPack09dschrgEthrtcMax_BASE battAnalyticsPack09muxID_BASE 4-4;
SG_MUL_VAL_ 2583677895 HVESP9lowestCellTemp_BASE battAnalyticsPack09muxID_BASE 6-6;
SG_MUL_VAL_ 2583677895 HVESP9dischargeCapacity_BASE battAnalyticsPack09muxID_BASE 3-3;
SG_MUL_VAL_ 2583677895 HVESP9highestCellTemp_BASE battAnalyticsPack09muxID_BASE 5-5;
SG_MUL_VAL_ 2583677895 battPack09minCellVoltage_BASE battAnalyticsPack09muxID_BASE 1-1;
SG_MUL_VAL_ 2583677895 HVESP9voltageLevel_BASE battAnalyticsPack09muxID_BASE 0-0;
SG_MUL_VAL_ 2583677895 battPack09isoMeasResPosv_BASE battAnalyticsPack09muxID_BASE 2-2;
SG_MUL_VAL_ 2583677895 battPack09glblDscnnctReq_BASE battAnalyticsPack09muxID_BASE 0-0;
SG_MUL_VAL_ 2583677895 battPack09isoMeasResNegv_BASE battAnalyticsPack09muxID_BASE 3-3;
SG_MUL_VAL_ 2583677895 HVESP9current_BASE battAnalyticsPack09muxID_BASE 0-0;
SG_MUL_VAL_ 2583677895 battPack09maxCellVoltage_BASE battAnalyticsPack09muxID_BASE 1-1;
SG_MUL_VAL_ 2583677895 battPack09SOH_BASE battAnalyticsPack09muxID_BASE 1-1;
SG_MUL_VAL_ 2583677895 battPack09modeReq_BASE battAnalyticsPack09muxID_BASE 0-0;
SG_MUL_VAL_ 2583677902 HVESP11highestCellTemp_BASE battAnalyticsPack11muxID_BASE 5-5;
SG_MUL_VAL_ 2583677902 HVESP11fastUpdateSOC_BASE battAnalyticsPack11muxID_BASE 0-0;
SG_MUL_VAL_ 2583677902 battPack11dschrgEthrtcMax_BASE battAnalyticsPack11muxID_BASE 4-4;
SG_MUL_VAL_ 2583677902 HVESP11dischargeCapacity_BASE battAnalyticsPack11muxID_BASE 3-3;
SG_MUL_VAL_ 2583677902 HVESP11lowestCellTemp_BASE battAnalyticsPack11muxID_BASE 6-6;
SG_MUL_VAL_ 2583677902 HVESP11voltageLevel_BASE battAnalyticsPack11muxID_BASE 0-0;
SG_MUL_VAL_ 2583677902 battPack11minCellVoltage_BASE battAnalyticsPack11muxID_BASE 1-1;
SG_MUL_VAL_ 2583677902 battPack11glblDscnnctReq_BASE battAnalyticsPack11muxID_BASE 0-0;
SG_MUL_VAL_ 2583677902 battPack11isoMeasResNegv_BASE battAnalyticsPack11muxID_BASE 3-3;
SG_MUL_VAL_ 2583677902 battPack11isoMeasResPosv_BASE battAnalyticsPack11muxID_BASE 2-2;
SG_MUL_VAL_ 2583677902 battPack11maxCellVoltage_BASE battAnalyticsPack11muxID_BASE 1-1;
SG_MUL_VAL_ 2583677902 HVESP11current_BASE battAnalyticsPack11muxID_BASE 0-0;
SG_MUL_VAL_ 2583677902 battPack11SOH_BASE battAnalyticsPack11muxID_BASE 1-1;
SG_MUL_VAL_ 2583677902 battPack11modeReq_BASE battAnalyticsPack11muxID_BASE 0-0;
SG_MUL_VAL_ 2583677903 battPack12dschrgEthrtcMax_BASE battAnalyticsPack12muxID_BASE 4-4;
SG_MUL_VAL_ 2583677903 HVESP12dischargeCapacity_BASE battAnalyticsPack12muxID_BASE 3-3;
SG_MUL_VAL_ 2583677903 HVESP12highestCellTemp_BASE battAnalyticsPack12muxID_BASE 5-5;
SG_MUL_VAL_ 2583677903 HVESP12lowestCellTemp_BASE battAnalyticsPack12muxID_BASE 6-6;
SG_MUL_VAL_ 2583677903 HVESP12fastUpdateSOC_BASE battAnalyticsPack12muxID_BASE 0-0;
SG_MUL_VAL_ 2583677903 battPack12minCellVoltage_BASE battAnalyticsPack12muxID_BASE 1-1;
SG_MUL_VAL_ 2583677903 HVESP12voltageLevel_BASE battAnalyticsPack12muxID_BASE 0-0;
SG_MUL_VAL_ 2583677903 battPack12glblDscnnctReq_BASE battAnalyticsPack12muxID_BASE 0-0;
SG_MUL_VAL_ 2583677903 battPack12isoMeasResPosv_BASE battAnalyticsPack12muxID_BASE 2-2;
SG_MUL_VAL_ 2583677903 battPack12isoMeasResNegv_BASE battAnalyticsPack12muxID_BASE 3-3;
SG_MUL_VAL_ 2583677903 HVESP12current_BASE battAnalyticsPack12muxID_BASE 0-0;
SG_MUL_VAL_ 2583677903 battPack12maxCellVoltage_BASE battAnalyticsPack12muxID_BASE 1-1;
SG_MUL_VAL_ 2583677903 battPack12SOH_BASE battAnalyticsPack12muxID_BASE 1-1;
SG_MUL_VAL_ 2583677903 battPack12modeReq_BASE battAnalyticsPack12muxID_BASE 0-0;
SG_MUL_VAL_ 2583677900 HVESP10fastUpdateSOC_BASE battAnalyticsPack10muxID_BASE 0-0;
SG_MUL_VAL_ 2583677900 HVESP10highestCellTemp_BASE battAnalyticsPack10muxID_BASE 5-5;
SG_MUL_VAL_ 2583677900 HVESP10dischargeCapacity_BASE battAnalyticsPack10muxID_BASE 3-3;
SG_MUL_VAL_ 2583677900 HVESP10lowestCellTemp_BASE battAnalyticsPack10muxID_BASE 6-6;
SG_MUL_VAL_ 2583677900 battPack10dschrgEthrtcMax_BASE battAnalyticsPack10muxID_BASE 4-4;
SG_MUL_VAL_ 2583677900 HVESP10voltageLevel_BASE battAnalyticsPack10muxID_BASE 0-0;
SG_MUL_VAL_ 2583677900 battPack10minCellVoltage_BASE battAnalyticsPack10muxID_BASE 1-1;
SG_MUL_VAL_ 2583677900 battPack10isoMeasResPosv_BASE battAnalyticsPack10muxID_BASE 2-2;
SG_MUL_VAL_ 2583677900 battPack10isoMeasResNegv_BASE battAnalyticsPack10muxID_BASE 3-3;
SG_MUL_VAL_ 2583677900 battPack10glblDscnnctReq_BASE battAnalyticsPack10muxID_BASE 0-0;
SG_MUL_VAL_ 2583677900 battPack10maxCellVoltage_BASE battAnalyticsPack10muxID_BASE 1-1;
SG_MUL_VAL_ 2583677900 HVESP10current_BASE battAnalyticsPack10muxID_BASE 0-0;
SG_MUL_VAL_ 2583677900 battPack10SOH_BASE battAnalyticsPack10muxID_BASE 1-1;
SG_MUL_VAL_ 2583677900 battPack10modeReq_BASE battAnalyticsPack10muxID_BASE 0-0;
SG_MUL_VAL_ 2583677939 battPack01dschrgEthrtcMax_BASE battAnalyticsPack01muxID_BASE 4-4;
SG_MUL_VAL_ 2583677939 HVESP1dischargeCapacity_BASE battAnalyticsPack01muxID_BASE 3-3;
SG_MUL_VAL_ 2583677939 HVESP1fastUpdateSOC_BASE battAnalyticsPack01muxID_BASE 0-0;
SG_MUL_VAL_ 2583677939 HVESP1highestCellTemp_BASE battAnalyticsPack01muxID_BASE 5-5;
SG_MUL_VAL_ 2583677939 HVESP1lowestCellTemp_BASE battAnalyticsPack01muxID_BASE 6-6;
SG_MUL_VAL_ 2583677939 battPack01minCellVoltage_BASE battAnalyticsPack01muxID_BASE 1-1;
SG_MUL_VAL_ 2583677939 HVESP1voltageLevel_BASE battAnalyticsPack01muxID_BASE 0-0;
SG_MUL_VAL_ 2583677939 battPack01glblDscnnctReq_BASE battAnalyticsPack01muxID_BASE 0-0;
SG_MUL_VAL_ 2583677939 battPack01isoMeasResNegv_BASE battAnalyticsPack01muxID_BASE 3-3;
SG_MUL_VAL_ 2583677939 battPack01isoMeasResPosv_BASE battAnalyticsPack01muxID_BASE 2-2;
SG_MUL_VAL_ 2583677939 battPack01maxCellVoltage_BASE battAnalyticsPack01muxID_BASE 1-1;
SG_MUL_VAL_ 2583677939 HVESP1current_BASE battAnalyticsPack01muxID_BASE 0-0;
SG_MUL_VAL_ 2583677939 battPack01SOH_BASE battAnalyticsPack01muxID_BASE 1-1;
SG_MUL_VAL_ 2583677939 battPack01modeReq_BASE battAnalyticsPack01muxID_BASE 0-0;
